VERSION "dbc-export 1 2026.26.6.5"

NS_ :

BS_:

BU_: BMS CP DAS DIF GTW HVP ICR PCS SCCM VCBATT VCFRONT VCFRONT1 VCLEFT VCRIGHT VCSEC

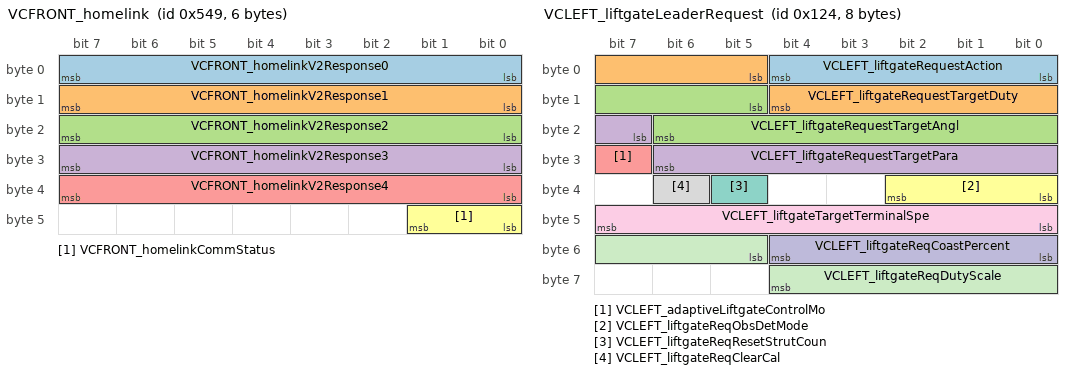
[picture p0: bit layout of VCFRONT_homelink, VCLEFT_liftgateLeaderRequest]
BO_ 1353 VCFRONT_homelink: 6 VCFRONT
 SG_ VCFRONT_homelinkV2Response0 : 0|8@1+ (1,0) [0|255] "" Vector__XXX
 SG_ VCFRONT_homelinkV2Response1 : 8|8@1+ (1,0) [0|255] "" Vector__XXX
 SG_ VCFRONT_homelinkV2Response2 : 16|8@1+ (1,0) [0|255] "" Vector__XXX
 SG_ VCFRONT_homelinkV2Response3 : 24|8@1+ (1,0) [0|255] "" Vector__XXX
 SG_ VCFRONT_homelinkV2Response4 : 32|8@1+ (1,0) [0|255] "" Vector__XXX
 SG_ VCFRONT_homelinkCommStatus : 40|2@1+ (1,0) [1|3] "" Vector__XXX

BO_ 1801 VCFRONT_logging0point1Hz: 8 VCFRONT
 SG_ VCFRONT_logging0point1HzIndex M : 0|6@1+ (1,0) [0|63] "" Vector__XXX
 SG_ VC_hcmlFactoryOfOrigin m26 : 6|2@1+ (1,0) [0|3] "" Vector__XXX
 SG_ VC_hcmlHellaPartNumberStatus m26 : 8|1@1+ (1,0) [0|1] "" Vector__XXX
 SG_ VC_hcmlHellaPartNumber m26 : 9|32@1+ (1,0) [0|4294967295] "-" Vector__XXX
 SG_ VC_hcmlCurrentBinMappingType m26 : 41|2@1+ (1,0) [0|3] "" Vector__XXX
 SG_ VC_hcmlCurrentBin0Value m26 : 43|3@1+ (1,0) [1|7] "" Vector__XXX
 SG_ VC_hcmlCurrentBin1Value m26 : 46|3@1+ (1,0) [1|7] "" Vector__XXX
 SG_ VC_hcmlCurrentBin2Value m26 : 49|3@1+ (1,0) [1|7] "" Vector__XXX
 SG_ VC_hcmlCurrentBin3Value m26 : 52|3@1+ (1,0) [1|7] "" Vector__XXX
 SG_ VC_hcmlCurrentBin4Value m26 : 55|3@1+ (1,0) [1|7] "" Vector__XXX
 SG_ VC_hcmlCurrentBin5Value m26 : 58|3@1+ (1,0) [1|7] "" Vector__XXX
 SG_ VC_hcmlRegionAndSide m26 : 61|3@1+ (1,0) [1|7] "" Vector__XXX
 SG_ VC_hcmrFactoryOfOrigin m27 : 6|2@1+ (1,0) [0|3] "" Vector__XXX
 SG_ VC_hcmrHellaPartNumberStatus m27 : 8|1@1+ (1,0) [0|1] "" Vector__XXX
 SG_ VC_hcmrHellaPartNumber m27 : 9|32@1+ (1,0) [0|4294967295] "-" Vector__XXX
 SG_ VC_hcmrCurrentBinMappingType m27 : 41|2@1+ (1,0) [0|3] "" Vector__XXX
 SG_ VC_hcmrCurrentBin0Value m27 : 43|3@1+ (1,0) [1|7] "" Vector__XXX
 SG_ VC_hcmrCurrentBin1Value m27 : 46|3@1+ (1,0) [1|7] "" Vector__XXX
 SG_ VC_hcmrCurrentBin2Value m27 : 49|3@1+ (1,0) [1|7] "" Vector__XXX
 SG_ VC_hcmrCurrentBin3Value m27 : 52|3@1+ (1,0) [1|7] "" Vector__XXX
 SG_ VC_hcmrCurrentBin4Value m27 : 55|3@1+ (1,0) [1|7] "" Vector__XXX
 SG_ VC_hcmrCurrentBin5Value m27 : 58|3@1+ (1,0) [1|7] "" Vector__XXX
 SG_ VC_hcmrRegionAndSide m27 : 61|3@1+ (1,0) [1|7] "" Vector__XXX

BO_ 957 VCFRONT_parkedEnergyLoss: 8 VCFRONT
 SG_ VCFRONT_energyLossIndex M : 0|3@1+ (1,0) [0|7] "" Vector__XXX
 SG_ VCFRONT_userEnergyLossSinceDrive m1 : 8|14@1+ (0.01,0) [0|163.83] "kWh" Vector__XXX
 SG_ VCFRONT_preconditioningEner_0001 m1 : 22|14@1+ (0.01,0) [0|163.83] "kWh" Vector__XXX
 SG_ VCFRONT_cabinOverheatEnergy_0001 m1 : 36|14@1+ (0.01,0) [0|163.83] "kWh" Vector__XXX
 SG_ VCFRONT_mobileAppEnergyLoss_0001 m1 : 50|14@1+ (0.01,0) [0|163.83] "kWh" Vector__XXX
 SG_ VCFRONT_summonStandbyEnergy_0001 m2 : 8|14@1+ (0.01,0) [0|163.83] "kWh" Vector__XXX
 SG_ VCFRONT_sentryModeEnergyLos_0001 m2 : 22|14@1+ (0.01,0) [0|163.83] "kWh" Vector__XXX
 SG_ VCFRONT_backgroundEnergyLos_0001 m2 : 36|14@1+ (0.01,0) [0|163.83] "kWh" Vector__XXX
 SG_ VCFRONT_evapDryingEnergyLos_0001 m2 : 50|14@1+ (0.01,0) [0|163.83] "kWh" Vector__XXX
 SG_ VCFRONT_userEnergyLossSinceCharg m3 : 8|14@1+ (0.01,0) [0|163.83] "kWh" Vector__XXX
 SG_ VCFRONT_preconditioningEnergyLos m3 : 22|14@1+ (0.01,0) [0|163.83] "kWh" Vector__XXX
 SG_ VCFRONT_cabinOverheatEnergyLossS m3 : 36|14@1+ (0.01,0) [0|163.83] "kWh" Vector__XXX
 SG_ VCFRONT_mobileAppEnergyLossSince m3 : 50|14@1+ (0.01,0) [0|163.83] "kWh" Vector__XXX
 SG_ VCFRONT_summonStandbyEnergyLossS m4 : 8|14@1+ (0.01,0) [0|163.83] "kWh" Vector__XXX
 SG_ VCFRONT_sentryModeEnergyLossSinc m4 : 22|14@1+ (0.01,0) [0|163.83] "kWh" Vector__XXX
 SG_ VCFRONT_backgroundEnergyLossSinc m4 : 36|14@1+ (0.01,0) [0|163.83] "kWh" Vector__XXX
 SG_ VCFRONT_evapDryingEnergyLossSinc m4 : 50|14@1+ (0.01,0) [0|163.83] "kWh" Vector__XXX

BO_ 737 VCFRONT_status: 8 VCFRONT
 SG_ VCFRONT_statusIndex M : 0|3@1+ (1,0) [0|7] "" Vector__XXX
 SG_ VCFRONT_frunkLatchStatus m0 : 3|4@1+ (1,0) [1|15] "" Vector__XXX
 SG_ VCFRONT_wiperSpeed m0 : 8|4@1+ (1,0) [1|15] "" Vector__XXX
 SG_ VCFRONT_wiperPosition m0 : 12|3@1+ (1,0) [1|7] "" Vector__XXX
 SG_ VCFRONT_wiperBlocked m0 : 15|1@1+ (1,0) [0|1] "" Vector__XXX
 SG_ VCFRONT_wiperState m0 : 16|4@1+ (1,0) [1|15] "" Vector__XXX
 SG_ VCFRONT_crashDetectedType m0 : 20|2@1+ (1,0) [0|3] "" Vector__XXX
 SG_ VCFRONT_crashState m0 : 22|2@1+ (1,0) [0|3] "" Vector__XXX
 SG_ VCFRONT_crashUnlockOverrideSet m0 : 24|1@1+ (1,0) [0|1] "" Vector__XXX
 SG_ VCFRONT_washPumpState m0 : 25|2@1+ (1,0) [0|3] "" Vector__XXX
 SG_ VCFRONT_turnIndicatorControlType m0 : 27|2@1+ (1,0) [0|3] "" Vector__XXX
 SG_ VCFRONT_wiperHealth m0 : 32|3@1+ (1,0) [0|7] "" Vector__XXX
 SG_ VCFRONT_wiperLINHealth m0 : 35|3@1+ (1,0) [0|7] "" Vector__XXX
 SG_ VCFRONT_frunkLatchCurrent m0 : 40|8@1- (0.157480314374,0) [-10|10] "A" Vector__XXX
 SG_ VCFRONT_frunkInteriorRelSwitch m0 : 48|1@1+ (1,0) [0|1] "" Vector__XXX
 SG_ VCFRONT_anyClosureOpen m0 : 49|1@1+ (1,0) [0|1] "" Vector__XXX
 SG_ VCFRONT_anyDoorOpen m0 : 50|1@1+ (1,0) [0|1] "" Vector__XXX
 SG_ VCFRONT_hornOn m0 : 51|1@1+ (1,0) [0|1] "" Vector__XXX
 SG_ VCFRONT_radarHeaterState m0 : 52|3@1+ (1,0) [1|7] "" Vector__XXX
 SG_ VCFRONT_trunkExteriorWakeSwitch m0 : 55|1@1+ (1,0) [0|1] "" Vector__XXX
 SG_ VCFRONT_passengerBuckleStatus m0 : 57|1@1+ (1,0) [0|1] "" Vector__XXX
 SG_ VCFRONT_frunkLatchType m0 : 58|2@1+ (1,0) [0|3] "" Vector__XXX
 SG_ VCFRONT_headlampLeftFanStatus m0 : 60|1@1+ (1,0) [0|1] "" Vector__XXX
 SG_ VCFRONT_headlampRightFanStatus m0 : 61|1@1+ (1,0) [0|1] "" Vector__XXX
 SG_ VCFRONT_frunkAccessPost m0 : 62|1@1+ (1,0) [0|1] "" Vector__XXX
 SG_ VCFRONT_isActiveHeatingBattery m0 : 63|1@1+ (1,0) [0|1] "" Vector__XXX
 SG_ VCFRONT_iBoosterWakeLine m1 : 3|1@1+ (1,0) [0|1] "" Vector__XXX
 SG_ VCFRONT_epasWakeLine m1 : 4|1@1+ (1,0) [0|1] "" Vector__XXX
 SG_ VCFRONT_iBoosterStateDBG m1 : 5|3@1+ (1,0) [0|7] "" Vector__XXX
 SG_ VCFRONT_vehicleStatusDBG m1 : 8|5@1+ (1,0) [0|31] "" Vector__XXX
 SG_ VCFRONT_timeSpentSleeping m1 : 13|10@1+ (1,0) [0|1023] "s" Vector__XXX
 SG_ VCFRONT_sleepCurrent m1 : 24|12@1+ (0.125,-511.875) [-511.875|-0.125] "mA" Vector__XXX
 SG_ VCFRONT_hibernationState m1 : 36|3@1+ (1,0) [0|7] "" Vector__XXX
 SG_ VCFRONT_wiperECUType m1 : 40|2@1+ (1,0) [0|3] "" Vector__XXX
 SG_ VCFRONT_wiperHeaterState m1 : 42|3@1+ (1,0) [1|7] "" Vector__XXX
 SG_ VCFRONT_occupantCount m1 : 45|3@1+ (1,0) [0|7] "" Vector__XXX
 SG_ VCFRONT_closureEasterEggState m1 : 48|3@1+ (1,0) [0|7] "" Vector__XXX
 SG_ VCFRONT_espWakeLine m1 : 51|1@1+ (1,0) [0|1] "" Vector__XXX
 SG_ VCFRONT_allowEvapInLowAmbient m1 : 52|1@1+ (1,0) [0|1] "" Vector__XXX
 SG_ VCFRONT_potentialRadiatorSteam m1 : 53|1@1+ (1,0) [0|1] "" Vector__XXX
 SG_ VCFRONT_potentialRadiatorSteamUI m1 : 54|1@1+ (1,0) [0|1] "" Vector__XXX
 SG_ VCFRONT_hvacReqOffForFasterCharg m1 : 55|1@1+ (1,0) [0|1] "" Vector__XXX
 SG_ VCFRONT_limitedSplitTempDeltaEnf m1 : 56|1@1+ (1,0) [0|1] "" Vector__XXX
 SG_ VCFRONT_batteryDischArbState m1 : 57|3@1+ (1,0) [0|7] "" Vector__XXX
 SG_ VCFRONT_maxEvapHeatRejection m2 : 8|8@1+ (65,0) [0|16575] "W" Vector__XXX
 SG_ VCFRONT_minEvapHeatRejection m2 : 16|8@1+ (15,0) [0|3800] "W" Vector__XXX
 SG_ VCFRONT_freezeEvapITerm m2 : 24|1@1+ (1,0) [0|1] "" Vector__XXX
 SG_ VCFRONT_isEvapOperationAllowed m2 : 25|1@1+ (1,0) [0|1] "" Vector__XXX
 SG_ VCFRONT_chillerDemandActive m2 : 26|1@1+ (1,0) [0|1] "" Vector__XXX
 SG_ VCFRONT_compPerfRecoveryLimited m2 : 27|1@1+ (1,0) [0|1] "" Vector__XXX
 SG_ VCFRONT_hvacModeNotAttainable m2 : 28|1@1+ (1,0) [0|1] "" Vector__XXX
 SG_ VCFRONT_hasLowRefrigerant m2 : 29|1@1+ (1,0) [0|1] "" Vector__XXX
 SG_ VCFRONT_isColdStartRunning m2 : 30|1@1+ (1,0) [0|1] "" Vector__XXX
 SG_ VCFRONT_isHeatPumpOilPurgeActive m2 : 31|1@1+ (1,0) [0|1] "" Vector__XXX
 SG_ VCFRONT_pressureRefrigSuction m2 : 32|7@1+ (0.125,0) [0|11.5] "bar" Vector__XXX
 SG_ VCFRONT_pressureRefrigDischarge m2 : 40|9@1+ (0.08,0) [0|37.25] "bar" Vector__XXX
 SG_ VCFRONT_hvacPerfTestCommand m2 : 49|3@1+ (1,0) [0|7] "" Vector__XXX
 SG_ VCFRONT_coolantFillRoutineStatus m2 : 52|2@1+ (1,0) [0|3] "" Vector__XXX
 SG_ VCFRONT_refrigFillRoutineStatus m2 : 54|2@1+ (1,0) [0|3] "" Vector__XXX
 SG_ VCFRONT_isCOP1Running m2 : 56|1@1+ (1,0) [0|1] "" Vector__XXX
 SG_ VCFRONT_closeValvesRoutineStatus m2 : 57|2@1+ (1,0) [0|3] "" Vector__XXX
 SG_ VCFRONT_thermalPerfTestRunning m2 : 59|1@1+ (1,0) [0|1] "" Vector__XXX
 SG_ VCFRONT_extendedHvacPerfTestComm m2 : 60|4@1+ (1,0) [0|15] "" Vector__XXX
 SG_ VCFRONT_5VARailStable m3 : 3|1@1+ (1,0) [0|1] "" Vector__XXX
 SG_ VCFRONT_5VBRailStable m3 : 4|1@1+ (1,0) [0|1] "" Vector__XXX
 SG_ VCFRONT_12VARailStable m3 : 5|1@1+ (1,0) [0|1] "" Vector__XXX
 SG_ VCFRONT_12VBRailStable m3 : 6|1@1+ (1,0) [0|1] "" Vector__XXX
 SG_ VCFRONT_railAState m3 : 7|1@1+ (1,0) [0|1] "" Vector__XXX
 SG_ VCFRONT_railBState m3 : 8|1@1+ (1,0) [0|1] "" Vector__XXX
 SG_ VCFRONT_ChargePumpVoltageStable m3 : 9|1@1+ (1,0) [0|1] "" Vector__XXX
 SG_ VCFRONT_PEResetLineState m3 : 10|1@1+ (1,0) [0|1] "" Vector__XXX
 SG_ VCFRONT_HSDInitCompleteU13 m3 : 11|1@1+ (1,0) [0|1] "" Vector__XXX
 SG_ VCFRONT_HSDInitCompleteU16 m3 : 12|1@1+ (1,0) [0|1] "" Vector__XXX
 SG_ VCFRONT_vbatMonitorVoltage m3 : 16|12@1+ (0.005443676,0) [0|22.286409544] "V" Vector__XXX
 SG_ VCFRONT_AS8510Voltage m3 : 28|12@1+ (0.005443676,0) [0|22.286409544] "V" Vector__XXX
 SG_ VCFRONT_vbatProt m3 : 40|12@1+ (0.005443676,0) [0|22.29185322] "V" Vector__XXX
 SG_ VCFRONT_logVerbosity m3 : 52|3@1+ (1,0) [0|7] "" Vector__XXX
 SG_ VCFRONT_cabinCoolingCapacityLimi m4 : 6|1@1+ (1,0) [0|1] "" Vector__XXX
 SG_ VCFRONT_cabinHeatingCapacityLimi m4 : 7|1@1+ (1,0) [0|1] "" Vector__XXX
 SG_ VCFRONT_compPowerSupportingHvac m4 : 8|11@1+ (10,0) [0|20470] "W" Vector__XXX
 SG_ VCFRONT_compPowerSupportingPT m4 : 19|11@1+ (10,0) [0|20470] "W" Vector__XXX
 SG_ VCFRONT_maxHeatingPowerLeftCC m4 : 30|7@1+ (100,0) [0|12000] "W" Vector__XXX
 SG_ VCFRONT_maxHeatingPowerRightCC m4 : 37|7@1+ (100,0) [0|12000] "W" Vector__XXX
 SG_ VCFRONT_activeLouverOpenPos m4 : 44|7@1+ (1,0) [0|100] "%" Vector__XXX
 SG_ VCFRONT_activeLouverState m4 : 51|5@1+ (1,0) [0|31] "" Vector__XXX
 SG_ VCFRONT_windshieldCameraHeaterPo m4 : 56|6@1+ (2.5,0) [0|155] "W" Vector__XXX

BO_ 507 VCLEFT_TLCStatus: 8 VCLEFT
 SG_ VCLEFT_TLCStatusIndex M : 0|2@1+ (1,0) [0|3] "" Vector__XXX
 SG_ VCLEFT_TLCTemperature m1 : 2|8@1- (1,68) [-59|195] "degC" Vector__XXX
 SG_ VCLEFT_TLCLeftTurnVoltage m1 : 10|8@1+ (0.1,0) [0|25.4] "V" Vector__XXX
 SG_ VCLEFT_TLCRightTurnVoltage m1 : 18|8@1+ (0.1,0) [0|25.4] "V" Vector__XXX
 SG_ VCLEFT_TLCState_LeftTurn m1 : 26|3@1+ (1,0) [0|7] "" Vector__XXX
 SG_ VCLEFT_TLCState_RightTurn m1 : 29|3@1+ (1,0) [0|7] "" Vector__XXX
 SG_ VCLEFT_TLCState_Tail m1 : 32|3@1+ (1,0) [0|7] "" Vector__XXX
 SG_ VCLEFT_TLCState_Stop m1 : 35|3@1+ (1,0) [0|7] "" Vector__XXX
 SG_ VCLEFT_TLCState_Fog m1 : 38|3@1+ (1,0) [0|7] "" Vector__XXX
 SG_ VCLEFT_TLCState_Reverse m1 : 41|3@1+ (1,0) [0|7] "" Vector__XXX

BO_ 292 VCLEFT_liftgateLeaderRequest: 8 VCLEFT
 SG_ VCLEFT_liftgateRequestAction : 0|5@1+ (1,0) [0|31] "" Vector__XXX
 SG_ VCLEFT_liftgateRequestTargetDuty : 5|8@1- (1,0) [-100|100] "%" Vector__XXX
 SG_ VCLEFT_liftgateRequestTargetAngl : 13|10@1- (0.2,0) [-100|100] "deg" Vector__XXX
 SG_ VCLEFT_liftgateRequestTargetPara : 23|8@1- (1,0) [-100|100] "" Vector__XXX
 SG_ VCLEFT_adaptiveLiftgateControlMo : 31|1@1+ (1,0) [0|1] "" Vector__XXX
 SG_ VCLEFT_liftgateReqObsDetMode : 32|3@1+ (1,0) [0|7] "" Vector__XXX
 SG_ VCLEFT_liftgateReqResetStrutCoun : 37|1@1+ (1,0) [0|1] "" Vector__XXX
 SG_ VCLEFT_liftgateReqClearCal : 38|1@1+ (1,0) [0|1] "" Vector__XXX
 SG_ VCLEFT_liftgateTargetTerminalSpe : 40|8@1- (0.08,10) [0|20] "deg/s" Vector__XXX
 SG_ VCLEFT_liftgateReqCoastPercent : 48|5@1+ (4,0) [0|100] "%" Vector__XXX
 SG_ VCLEFT_liftgateReqDutyScale : 53|8@1+ (0.0125,0) [0|3.15] "-" Vector__XXX

BO_ 1802 VCLEFT_logging0point1Hz: 8 VCLEFT
 SG_ VCLEFT_logging0point1HzIndex M : 0|1@1+ (1,0) [0|1] "" Vector__XXX
 SG_ VCLEFT_leftBrakeTailLightCurrent m0 : 2|9@1+ (0.005,0) [0|2.55] "A" Vector__XXX
 SG_ VCLEFT_leftBrakeTailLightCu_0001 m0 : 11|3@1+ (1,0) [1|7] "" Vector__XXX
 SG_ VCLEFT_leftRearTurnLightCurrent m0 : 14|9@1+ (0.002,0) [0|1.02] "A" Vector__XXX
 SG_ VCLEFT_leftRearTurnLightCurrentS m0 : 24|3@1+ (1,0) [1|7] "" Vector__XXX
 SG_ VCLEFT_phoneTemperatureFL m0 : 32|8@1- (1,-50) [-177|77] "degC" Vector__XXX
 SG_ VCLEFT_phoneTemperatureFR m0 : 40|8@1- (1,-50) [-177|77] "degC" Vector__XXX
 SG_ VCLEFT_canAuthResyncDurationMs m0 : 48|16@1+ (1,0) [0|65535] "" Vector__XXX

BO_ 930 VCLEFT_status: 8 VCLEFT
 SG_ VCLEFT_statusIndex M : 0|2@1+ (1,0) [0|3] "" Vector__XXX
 SG_ VCLEFT_securityControllerEnable m0 : 5|1@1+ (1,0) [0|1] "" Vector__XXX
 SG_ VCLEFT_securityControllerVoltage m0 : 6|5@1+ (0.625,0) [0|19.375] "V" Vector__XXX
 SG_ VCLEFT_consoleDoorAssist m0 : 11|1@1+ (1,0) [0|1] "" Vector__XXX
 SG_ VCLEFT_OTAState m0 : 12|1@1+ (1,0) [0|1] "" Vector__XXX
 SG_ VCLEFT_5AVoltage m0 : 13|10@1+ (0.005443676,0) [0|5.568880548] "V" Vector__XXX
 SG_ VCLEFT_vbatProt m0 : 23|12@1+ (0.005443676,0) [0|22.29185322] "V" Vector__XXX
 SG_ VCLEFT_footwellLightCurrent m0 : 35|12@1- (0.1,0) [-204.8|204.7] "mA" Vector__XXX
 SG_ VCLEFT_swcInputVoltage m0 : 47|8@1+ (0.1,0) [0|25.4] "V" Vector__XXX
 SG_ VCLEFT_swcPCBATemperature m0 : 55|8@1- (1,68) [-59|195] "degC" Vector__XXX
 SG_ VCLEFT_obdEthernetActive m0 : 63|1@1+ (1,0) [0|1] "" Vector__XXX
 SG_ VCLEFT_rationalityAggregateCurre m1 : 12|8@1+ (0.5,0) [0|127.5] "A" Vector__XXX
 SG_ VCLEFT_LVBatteryTypeDBG m1 : 20|3@1+ (1,0) [0|7] "" Vector__XXX
 SG_ VCLEFT_DIeFuseFault m1 : 24|1@1+ (1,0) [0|1] "" Vector__XXX
 SG_ VCLEFT_eFuseMgmtVoltageMonitor m1 : 25|7@1+ (0.125,0) [0|15.875] "V" Vector__XXX
 SG_ VCLEFT_trailerAuxCurrent m1 : 32|12@1+ (0.025,0) [0|102.35] "A" Vector__XXX
 SG_ VCLEFT_swcHeatTmp m1 : 44|10@1+ (0.1,-35) [-35|65] "degC" Vector__XXX
 SG_ VCLEFT_swcHeatStatus m1 : 54|3@1+ (1,0) [1|7] "" Vector__XXX
 SG_ VCLEFT_swcHeatInhibited m1 : 57|1@1+ (1,0) [0|1] "" Vector__XXX
 SG_ VCLEFT_obdDeviceDetected m1 : 58|1@1+ (1,0) [0|1] "" Vector__XXX
 SG_ VCLEFT_pcbaTemperature m2 : 4|11@1+ (0.125,-40) [-40|150] "degC" Vector__XXX
 SG_ VCLEFT_swcHeatPwr m2 : 15|9@1+ (0.5,0) [0|254] "W" Vector__XXX
 SG_ VCLEFT_swcHeatDutyCycle m2 : 24|7@1+ (1,0) [0|100] "%" Vector__XXX
 SG_ VCLEFT_DIeFuseCurrent m2 : 31|6@1+ (0.1,0) [0|6.3] "A" Vector__XXX
 SG_ VCLEFT_SWCpresent m2 : 37|1@1+ (1,0) [0|1] "" Vector__XXX
 SG_ VCLEFT_trailerBrakeControllerCur m2 : 38|8@1+ (0.1,0) [0|25.5] "A" Vector__XXX
 SG_ VCLEFT_autonomyBehaviorStatus m2 : 46|2@1+ (1,0) [0|3] "" Vector__XXX
 SG_ VCLEFT_thirdRowLeftMapLightStatu m2 : 48|2@1+ (1,0) [0|2] "" Vector__XXX
 SG_ VCLEFT_thirdRowRightMapLightStat m2 : 50|2@1+ (1,0) [0|2] "" Vector__XXX

BO_ 962 VCLEFT_switchStatus: 8 VCLEFT
 SG_ VCLEFT_switchStatusIndex M : 0|1@1+ (1,0) [0|1] "" Vector__XXX
 SG_ VCLEFT_hornSwitchPressed m0 : 2|1@1+ (1,0) [0|1] "" Vector__XXX
 SG_ VCLEFT_hazardButtonPressed m0 : 3|1@1+ (1,0) [0|1] "" Vector__XXX
 SG_ VCLEFT_brakeSwitchPressed m0 : 4|1@1+ (1,0) [0|1] "" Vector__XXX
 SG_ VCLEFT_rightMirrorTilt m0 : 5|3@1+ (1,0) [0|7] "" Vector__XXX
 SG_ VCLEFT_frontSeatTrackBack m0 : 8|2@1+ (1,0) [1|3] "" Vector__XXX
 SG_ VCLEFT_frontSeatTrackForward m0 : 10|2@1+ (1,0) [1|3] "" Vector__XXX
 SG_ VCLEFT_frontSeatTiltDown m0 : 12|2@1+ (1,0) [1|3] "" Vector__XXX
 SG_ VCLEFT_frontSeatTiltUp m0 : 14|2@1+ (1,0) [1|3] "" Vector__XXX
 SG_ VCLEFT_frontSeatLiftDown m0 : 16|2@1+ (1,0) [1|3] "" Vector__XXX
 SG_ VCLEFT_frontSeatLiftUp m0 : 18|2@1+ (1,0) [1|3] "" Vector__XXX
 SG_ VCLEFT_frontSeatBackrestBack m0 : 20|2@1+ (1,0) [1|3] "" Vector__XXX
 SG_ VCLEFT_frontSeatBackrestForward m0 : 22|2@1+ (1,0) [1|3] "" Vector__XXX
 SG_ VCLEFT_frontSeatLumbarDown m0 : 24|2@1+ (1,0) [1|3] "" Vector__XXX
 SG_ VCLEFT_frontSeatLumbarUp m0 : 26|2@1+ (1,0) [1|3] "" Vector__XXX
 SG_ VCLEFT_frontSeatLumbarIn m0 : 28|2@1+ (1,0) [1|3] "" Vector__XXX
 SG_ VCLEFT_frontSeatLumbarOut m0 : 30|2@1+ (1,0) [1|3] "" Vector__XXX
 SG_ VCLEFT_btnWindowSwPackUpLF m0 : 32|1@1+ (1,0) [0|1] "" Vector__XXX
 SG_ VCLEFT_btnWindowSwPackAutoUpLF m0 : 33|1@1+ (1,0) [0|1] "" Vector__XXX
 SG_ VCLEFT_btnWindowSwPackDownLF m0 : 34|1@1+ (1,0) [0|1] "" Vector__XXX
 SG_ VCLEFT_btnWindowSwPackAutoDownLF m0 : 35|1@1+ (1,0) [0|1] "" Vector__XXX
 SG_ VCLEFT_btnWindowSwPackUpLR m0 : 36|1@1+ (1,0) [0|1] "" Vector__XXX
 SG_ VCLEFT_btnWindowSwPackAutoUpLR m0 : 37|1@1+ (1,0) [0|1] "" Vector__XXX
 SG_ VCLEFT_btnWindowSwPackDownLR m0 : 38|1@1+ (1,0) [0|1] "" Vector__XXX
 SG_ VCLEFT_btnWindowSwPackAutoDownLR m0 : 39|1@1+ (1,0) [0|1] "" Vector__XXX
 SG_ VCLEFT_btnWindowSwPackUpRF m0 : 40|1@1+ (1,0) [0|1] "" Vector__XXX
 SG_ VCLEFT_btnWindowSwPackAutoUpRF m0 : 41|1@1+ (1,0) [0|1] "" Vector__XXX
 SG_ VCLEFT_btnWindowSwPackDownRF m0 : 42|1@1+ (1,0) [0|1] "" Vector__XXX
 SG_ VCLEFT_btnWindowSwPackAutoDownRF m0 : 43|1@1+ (1,0) [0|1] "" Vector__XXX
 SG_ VCLEFT_btnWindowSwPackUpRR m0 : 44|1@1+ (1,0) [0|1] "" Vector__XXX
 SG_ VCLEFT_btnWindowSwPackAutoUpRR m0 : 45|1@1+ (1,0) [0|1] "" Vector__XXX
 SG_ VCLEFT_btnWindowSwPackDownRR m0 : 46|1@1+ (1,0) [0|1] "" Vector__XXX
 SG_ VCLEFT_btnWindowSwPackAutoDownRR m0 : 47|1@1+ (1,0) [0|1] "" Vector__XXX
 SG_ VCLEFT_frontBuckleSwitch m0 : 48|2@1+ (1,0) [1|3] "" Vector__XXX
 SG_ VCLEFT_frontOccupancySwitch m0 : 50|2@1+ (1,0) [1|3] "" Vector__XXX
 SG_ VCLEFT_rearLeftBuckleSwitch m0 : 52|2@1+ (1,0) [1|3] "" Vector__XXX
 SG_ VCLEFT_rearCenterOccupancySwitch m0 : 54|2@1+ (1,0) [1|3] "" Vector__XXX
 SG_ VCLEFT_rearLeftOccupancySwitch m0 : 56|2@1+ (1,0) [1|3] "" Vector__XXX
 SG_ VCLEFT_rearRightOccupancySwitch m0 : 58|2@1+ (1,0) [1|3] "" Vector__XXX
 SG_ VCLEFT_brakePressed m0 : 60|1@1+ (1,0) [0|1] "" Vector__XXX
 SG_ VCLEFT_rearHVACButtonPressed m0 : 61|1@1+ (1,0) [0|1] "" Vector__XXX
 SG_ VCLEFT_rearCenterBuckleSwitch m0 : 62|2@1+ (1,0) [1|3] "" Vector__XXX
 SG_ VCLEFT_isAlcoholInterlockSet m1 : 2|1@1+ (1,0) [0|1] "" Vector__XXX
 SG_ VCLEFT_swcLeftTiltRight m1 : 3|2@1+ (1,0) [1|3] "" Vector__XXX
 SG_ VCLEFT_swcLeftPressed m1 : 5|2@1+ (1,0) [1|3] "" Vector__XXX
 SG_ VCLEFT_swcRightTiltLeft m1 : 8|2@1+ (1,0) [1|3] "" Vector__XXX
 SG_ VCLEFT_swcRightTiltRight m1 : 10|2@1+ (1,0) [1|3] "" Vector__XXX
 SG_ VCLEFT_swcRightPressed m1 : 12|2@1+ (1,0) [1|3] "" Vector__XXX
 SG_ VCLEFT_swcLeftTiltLeft m1 : 14|2@1+ (1,0) [1|3] "" Vector__XXX
 SG_ VCLEFT_swcLeftScrollTicks m1 : 16|6@1- (1,0) [-32|31] "" Vector__XXX
 SG_ VCLEFT_swcWiperButtonState m1 : 22|2@1+ (1,0) [0|3] "" Vector__XXX
 SG_ VCLEFT_swcRightScrollTicks m1 : 24|6@1- (1,0) [-32|31] "" Vector__XXX
 SG_ VCLEFT_swcTurnSignalLeftButtonSt m1 : 30|2@1+ (1,0) [0|3] "" Vector__XXX
 SG_ VCLEFT_btnWindowUpLR m1 : 32|1@1+ (1,0) [0|1] "" Vector__XXX
 SG_ VCLEFT_btnWindowAutoUpLR m1 : 33|1@1+ (1,0) [0|1] "" Vector__XXX
 SG_ VCLEFT_btnWindowDownLR m1 : 34|1@1+ (1,0) [0|1] "" Vector__XXX
 SG_ VCLEFT_btnWindowAutoDownLR m1 : 35|1@1+ (1,0) [0|1] "" Vector__XXX
 SG_ VCLEFT_2RowSeatLeftFoldFlatSwitc m1 : 38|1@1+ (1,0) [0|1] "" Vector__XXX
 SG_ VCLEFT_2RowSeatRightFoldFlatSwit m1 : 39|1@1+ (1,0) [0|1] "" Vector__XXX
 SG_ VCLEFT_2RowSeatBothFoldFlatSwitc m1 : 40|1@1+ (1,0) [0|1] "" Vector__XXX
 SG_ VCLEFT_swcLeftDoublePress m1 : 41|1@1+ (1,0) [0|1] "" Vector__XXX
 SG_ VCLEFT_swcRightDoublePress m1 : 42|1@1+ (1,0) [0|1] "" Vector__XXX
 SG_ VCLEFT_swcTurnSignalRightButtonS m1 : 44|2@1+ (1,0) [0|3] "" Vector__XXX
 SG_ VCLEFT_swcHighBeamButtonState m1 : 46|2@1+ (1,0) [0|3] "" Vector__XXX
 SG_ VCLEFT_swcVoiceControlPress m1 : 48|2@1+ (1,0) [1|3] "" Vector__XXX
 SG_ VCLEFT_swcCameraButtonState m1 : 50|2@1+ (1,0) [0|3] "" Vector__XXX
 SG_ VCLEFT_swcRightPressedQF m1 : 52|1@1+ (1,0) [0|1] "" Vector__XXX
 SG_ VCLEFT_2RowSeatReclineSwitchpack m1 : 53|3@1+ (1,0) [0|7] "" Vector__XXX
 SG_ VCLEFT_3RowLeftBuckleSwitch m1 : 56|2@1+ (1,0) [1|3] "" Vector__XXX
 SG_ VCLEFT_frontSeatThighSupportExte m1 : 58|2@1+ (1,0) [1|3] "" Vector__XXX
 SG_ VCLEFT_frontSeatThighSupportRetr m1 : 60|2@1+ (1,0) [1|3] "" Vector__XXX
 SG_ VCLEFT_frontSeatResistiveOccupan m1 : 62|2@1+ (1,0) [1|3] "" Vector__XXX

BO_ 1114 VCRIGHT_AP_hvacState10Hz: 8 VCRIGHT
 SG_ VCRIGHT_AP_hvacState10HzIndex M : 0|2@1+ (1,0) [0|3] "" Vector__XXX
 SG_ VCRIGHT_AP_autoDefogAvailable m0 : 2|1@1+ (1,0) [0|1] "" Vector__XXX
 SG_ VCRIGHT_AP_hvacFlashFoggingDetec m0 : 3|1@1+ (1,0) [0|1] "" Vector__XXX
 SG_ VCRIGHT_AP_hvacModelInitStatus m0 : 4|3@1+ (1,0) [0|7] "" Vector__XXX
 SG_ VCRIGHT_AP_cabinTempWindshield m0 : 7|8@1+ (0.5,-40) [-40|80] "degC" Vector__XXX
 SG_ VCRIGHT_AP_cabinTempSideGlassRig m0 : 15|8@1+ (0.5,-40) [-40|80] "degC" Vector__XXX
 SG_ VCRIGHT_AP_cabinTempSideGlassLef m0 : 23|8@1+ (0.5,-40) [-40|80] "degC" Vector__XXX
 SG_ VCRIGHT_AP_hvacRecircDoorPercent m0 : 31|6@1+ (1.6,0) [0|100] "%" Vector__XXX
 SG_ VCRIGHT_AP_hvacAirDistributionMo m0 : 37|3@1+ (1,0) [0|7] "" Vector__XXX
 SG_ VCRIGHT_AP_hvacEstimateWindshiel m0 : 40|8@1+ (1,0) [0|150] "%" Vector__XXX
 SG_ VCRIGHT_AP_hvacMassflowTarget m0 : 48|8@1+ (1,0) [0|200] "g/s" Vector__XXX
 SG_ VCRIGHT_AP_tempDuctDefrost m0 : 56|8@1+ (0.5,-22) [-22|105] "degC" Vector__XXX
 SG_ VCRIGHT_AP_cameraTurnOnTime m1 : 2|9@1+ (5,0) [0|2540] "min" Vector__XXX
 SG_ VCRIGHT_AP_cameraDefogType m1 : 11|3@1+ (1,0) [0|7] "" Vector__XXX
 SG_ VCRIGHT_ah_hvacFaultSurvivabilit m1 : 14|5@1+ (10,0) [0|300] "sec" Vector__XXX
 SG_ VCRIGHT_ah_defoggingTimeNeeded m1 : 19|5@1+ (1,0) [0|30] "min" Vector__XXX
 SG_ VCRIGHT_AP_cameraFanDutyRequest m1 : 24|7@1+ (1,0) [0|100] "%" Vector__XXX
 SG_ VCRIGHT_ah_defogSystemState m1 : 31|3@1+ (1,0) [0|6] "" Vector__XXX
 SG_ VCRIGHT_AP_turnForwardCameraHeat m1 : 34|4@1+ (1,0) [0|15] "" Vector__XXX
 SG_ VCRIGHT_AP_turnCameraFanOffReaso m1 : 38|3@1+ (1,0) [0|7] "" Vector__XXX
 SG_ VCRIGHT_AP_forwardCameraIntegrat m1 : 41|1@1+ (1,0) [0|1] "" Vector__XXX
 SG_ VCRIGHT_AP_solarFluxOnRightWindo m1 : 48|8@1+ (5,0) [0|1150] "W/m2" Vector__XXX
 SG_ VCRIGHT_AP_solarFluxOnLeftWindow m1 : 56|8@1+ (5,0) [0|1150] "W/m2" Vector__XXX

BO_ 1795 VCRIGHT_debugThermal10Hz: 8 VCRIGHT
 SG_ VCRIGHT_debugThermal10HzIndex M : 0|4@1+ (1,0) [0|15] "" Vector__XXX
 SG_ VCRIGHT_hvacPanelFloorSplitRow1 m2 : 8|8@1+ (0.4,0) [0|100] "%" Vector__XXX
 SG_ VCRIGHT_hvacDefrostPercent m2 : 16|8@1+ (0.4,0) [0|100] "%" Vector__XXX
 SG_ VCRIGHT_hvacRow2Percent m2 : 24|8@1+ (0.4,0) [0|100] "%" Vector__XXX
 SG_ VCRIGHT_hvacPanelFloorSplitRow2 m2 : 32|8@1+ (0.4,0) [0|100] "%" Vector__XXX
 SG_ VCRIGHT_hvacFreshMassCounter m2 : 40|12@1+ (10,0) [0|40000] "kg" Vector__XXX
 SG_ VCRIGHT_hvacRecircMassCounter m2 : 52|12@1+ (10,0) [0|40000] "kg" Vector__XXX
 SG_ VCRIGHT_setTempAdjustmentLeft m3 : 8|7@1+ (0.1,0) [0|12] "degC" Vector__XXX
 SG_ VCRIGHT_setTempAdjustmentRight m3 : 16|7@1+ (0.1,0) [0|12] "degC" Vector__XXX
 SG_ VCRIGHT_hvacLHVaneVelocity m3 : 24|8@1- (0.8,0) [-100|100] "deg/s" Vector__XXX
 SG_ VCRIGHT_hvacRHVaneVelocity m3 : 32|8@1- (0.8,0) [-100|100] "deg/s" Vector__XXX
 SG_ VCRIGHT_hvacVehicleSpeed m3 : 40|5@1+ (5,0) [0|150] "kph" Vector__XXX
 SG_ VCRIGHT_hvacMassflowCompensated m3 : 47|8@1+ (1.5,0) [0|250] "g/s" Vector__XXX
 SG_ VCRIGHT_PTCcenterPowerLeft m5 : 8|6@1+ (30,0) [0|1800] "W" Vector__XXX
 SG_ VCRIGHT_PTCouterPowerLeft m5 : 16|6@1+ (30,0) [0|1800] "W" Vector__XXX
 SG_ VCRIGHT_PTCinnerPowerLeft m5 : 24|6@1+ (30,0) [0|1800] "W" Vector__XXX
 SG_ VCRIGHT_PTCcenterPowerRight m5 : 32|6@1+ (30,0) [0|1800] "W" Vector__XXX
 SG_ VCRIGHT_PTCouterPowerRight m5 : 40|6@1+ (30,0) [0|1800] "W" Vector__XXX
 SG_ VCRIGHT_PTCinnerPowerRight m5 : 48|6@1+ (30,0) [0|1800] "W" Vector__XXX
 SG_ VCRIGHT_PTCcenterStoneTempLeft m6 : 8|8@1+ (2,-70) [-70|438] "degC" Vector__XXX
 SG_ VCRIGHT_PTCcenterStoneTempRight m6 : 16|8@1+ (2,-70) [-70|438] "degC" Vector__XXX
 SG_ VCRIGHT_PTCinnerStoneTempLeft m6 : 24|8@1+ (2,-70) [-70|438] "degC" Vector__XXX
 SG_ VCRIGHT_PTCinnerStoneTempRight m6 : 32|8@1+ (2,-70) [-70|438] "degC" Vector__XXX
 SG_ VCRIGHT_PTCouterStoneTempLeft m7 : 8|8@1+ (2,-70) [-70|438] "degC" Vector__XXX
 SG_ VCRIGHT_PTCouterRodTempLeft m7 : 16|8@1+ (2,-70) [-70|438] "degC" Vector__XXX
 SG_ VCRIGHT_PTCouterAirTempLeft m7 : 24|8@1+ (2,-70) [-70|438] "degC" Vector__XXX
 SG_ VCRIGHT_PTCcenterRodTempLeft m7 : 32|8@1+ (2,-70) [-70|438] "degC" Vector__XXX
 SG_ VCRIGHT_PTCinnerRodTempLeft m7 : 40|8@1+ (2,-70) [-70|438] "degC" Vector__XXX
 SG_ VCRIGHT_PTCcenterAirTempLeft m7 : 48|8@1+ (2,-70) [-70|438] "degC" Vector__XXX
 SG_ VCRIGHT_PTCinnerAirTempLeft m7 : 56|8@1+ (2,-70) [-70|438] "degC" Vector__XXX
 SG_ VCRIGHT_PTCouterStoneTempRight m8 : 8|8@1+ (2,-70) [-70|438] "degC" Vector__XXX
 SG_ VCRIGHT_PTCouterRodTempRight m8 : 16|8@1+ (2,-70) [-70|438] "degC" Vector__XXX
 SG_ VCRIGHT_PTCouterAirTempRight m8 : 24|8@1+ (2,-70) [-70|438] "degC" Vector__XXX
 SG_ VCRIGHT_PTCcenterRodTempRight m8 : 32|8@1+ (2,-70) [-70|438] "degC" Vector__XXX
 SG_ VCRIGHT_PTCinnerRodTempRight m8 : 40|8@1+ (2,-70) [-70|438] "degC" Vector__XXX
 SG_ VCRIGHT_PTCcenterAirTempRight m8 : 48|8@1+ (2,-70) [-70|438] "degC" Vector__XXX
 SG_ VCRIGHT_PTCinnerAirTempRight m8 : 56|8@1+ (2,-70) [-70|438] "degC" Vector__XXX

BO_ 291 VCRIGHT_doorStatus2: 8 VCRIGHT
 SG_ VCRIGHT_doorStatus2Index M : 0|1@1+ (1,0) [0|1] "" Vector__XXX
 SG_ VCRIGHT_frontLatchRelDuty m1 : 8|8@1+ (1,0) [0|255] "%" Vector__XXX
 SG_ VCRIGHT_BPillarCameraHeaterState m1 : 16|3@1+ (1,0) [1|7] "" Vector__XXX
 SG_ VCRIGHT_doorLatchAjarSwitchVolta m1 : 24|8@1+ (0.02,0) [0|5] "V" Vector__XXX
 SG_ VCRIGHT_doorLatchAjarSwitch_0001 m1 : 32|8@1+ (0.02,0) [0|5] "V" Vector__XXX
 SG_ VCRIGHT_BPillarCameraHeaterCurre m1 : 40|6@1+ (0.02,0) [0|1.24] "A" Vector__XXX
 SG_ VCRIGHT_mirrorTiltXOffset m1 : 48|8@1- (0.02,0) [-2.5|2.5] "V" Vector__XXX
 SG_ VCRIGHT_mirrorTiltYOffset m1 : 56|8@1- (0.02,0) [-2.5|2.5] "V" Vector__XXX

BO_ 739 VCRIGHT_seatStatus2: 7 VCRIGHT
 SG_ VCRIGHT_seatStatus2Index M : 0|4@1+ (1,0) [0|15] "" Vector__XXX
 SG_ VCRIGHT_frontSeatHeatCurrent m0 : 4|12@1+ (0.01,0) [0|40.95] "A" Vector__XXX
 SG_ VCRIGHT_frontSeatHeatDuty m0 : 16|8@1+ (1,0) [0|255] "%" Vector__XXX
 SG_ VCRIGHT_frontSeatHeatTmp m0 : 24|12@1- (0.05,0) [-40|80] "degC" Vector__XXX
 SG_ VCRIGHT_frontSeatHeatTmpTarget m0 : 36|8@1- (0.5,0) [0|60] "degC" Vector__XXX
 SG_ VCRIGHT_frontSeatHeatInhibited m0 : 44|1@1+ (1,0) [0|1] "" Vector__XXX
 SG_ VCRIGHT_frontSeatHeatPowered m0 : 45|1@1+ (1,0) [0|1] "" Vector__XXX
 SG_ VC_AH_1RowRightSeatHeatVentHealt m0 : 54|2@1+ (1,0) [0|3] "" Vector__XXX
 SG_ VCRIGHT_rearLSeatHeatCurrent m1 : 4|12@1+ (0.01,0) [0|40.95] "A" Vector__XXX
 SG_ VCRIGHT_rearLSeatHeatDuty m1 : 16|8@1+ (1,0) [0|255] "%" Vector__XXX
 SG_ VCRIGHT_rearLSeatHeatTmp m1 : 24|12@1- (0.05,0) [-40|80] "degC" Vector__XXX
 SG_ VCRIGHT_rearLSeatHeatTmpTarget m1 : 36|8@1- (0.5,0) [0|60] "degC" Vector__XXX
 SG_ VCRIGHT_rearLSeatHeatInhibited m1 : 44|1@1+ (1,0) [0|1] "" Vector__XXX
 SG_ VCRIGHT_rearLSeatHeatPowered m1 : 45|1@1+ (1,0) [0|1] "" Vector__XXX
 SG_ VCRIGHT_rearCSeatHeatCurrent m2 : 4|12@1+ (0.01,0) [0|40.95] "A" Vector__XXX
 SG_ VCRIGHT_rearCSeatHeatDuty m2 : 16|8@1+ (1,0) [0|255] "%" Vector__XXX
 SG_ VCRIGHT_rearCSeatHeatTmp m2 : 24|12@1- (0.05,0) [-40|80] "degC" Vector__XXX
 SG_ VCRIGHT_rearCSeatHeatTmpTarget m2 : 36|8@1- (0.5,0) [0|60] "degC" Vector__XXX
 SG_ VCRIGHT_rearCSeatHeatInhibited m2 : 44|1@1+ (1,0) [0|1] "" Vector__XXX
 SG_ VCRIGHT_rearCSeatHeatPowered m2 : 45|1@1+ (1,0) [0|1] "" Vector__XXX
 SG_ VCRIGHT_rearRSeatHeatCurrent m3 : 4|12@1+ (0.01,0) [0|40.95] "A" Vector__XXX
 SG_ VCRIGHT_rearRSeatHeatDuty m3 : 16|8@1+ (1,0) [0|255] "%" Vector__XXX
 SG_ VCRIGHT_rearRSeatHeatTmp m3 : 24|12@1- (0.05,0) [-40|80] "degC" Vector__XXX
 SG_ VCRIGHT_rearRSeatHeatTmpTarget m3 : 36|8@1- (0.5,0) [0|60] "degC" Vector__XXX
 SG_ VCRIGHT_rearRSeatHeatInhibited m3 : 44|1@1+ (1,0) [0|1] "" Vector__XXX
 SG_ VCRIGHT_rearRSeatHeatPowered m3 : 45|1@1+ (1,0) [0|1] "" Vector__XXX
 SG_ VCRIGHT_2RowSeatReclineState m11 : 4|4@1+ (1,0) [0|14] "" Vector__XXX
 SG_ VCRIGHT_2RowSeatReclineDuty m11 : 8|8@1- (1,0) [-100|100] "%" Vector__XXX
 SG_ VCRIGHT_2RowSeatReclineCurrent m11 : 16|12@1- (0.05,0) [-100|100] "A" Vector__XXX
 SG_ VCRIGHT_2RowSeatReclineCalibrate m11 : 28|1@1+ (1,0) [0|1] "" Vector__XXX
 SG_ VCRIGHT_2RowSeatReclinePositionR m11 : 29|12@1- (1,0) [-2048|2047] "" Vector__XXX
 SG_ VCRIGHT_2RowSeatReclineAngle m11 : 41|12@1- (0.1,0) [-204.8|204.7] "deg" Vector__XXX
 SG_ VCRIGHT_2RowSeatReclineAbsPosSwi m11 : 53|2@1+ (1,0) [1|3] "" Vector__XXX
 SG_ VCRIGHT_2RowSeatReclinePositionS m12 : 4|3@1+ (1,0) [0|7] "" Vector__XXX
 SG_ VCRIGHT_2RowSeatReclineAdjustmen m12 : 7|1@1+ (1,0) [0|1] "" Vector__XXX
 SG_ VCRIGHT_2RowSeatReclineFoldAllow m12 : 8|1@1+ (1,0) [0|1] "" Vector__XXX
 SG_ VCRIGHT_2RowSeatReclineUnfoldAll m12 : 9|1@1+ (1,0) [0|1] "" Vector__XXX
 SG_ VCRIGHT_2RowSeatReclineNextToggl m12 : 10|2@1+ (1,0) [0|3] "" Vector__XXX
 SG_ VCRIGHT_2RowSeatReclineChoreoBlo m12 : 12|1@1+ (1,0) [0|1] "" Vector__XXX
 SG_ VCRIGHT_2RowSeat1RClashAvoidance m12 : 13|3@1+ (1,0) [0|7] "" Vector__XXX
 SG_ VCRIGHT_2RowSeat1RClashAvoi_0001 m12 : 16|2@1+ (1,0) [0|3] "" Vector__XXX
 SG_ VCRIGHT_2RowSeatReclineAbsP_0001 m12 : 18|12@1- (0.1,0) [-204.8|204.7] "deg" Vector__XXX
 SG_ VC_AH_2RowRightSeatMovementHealt m12 : 53|3@1+ (1,0) [0|7] "" Vector__XXX
 SG_ VCRIGHT_3RowSeatReclineState m14 : 4|4@1+ (1,0) [0|14] "" Vector__XXX
 SG_ VCRIGHT_3RowSeatReclineDuty m14 : 8|8@1- (1,0) [-100|100] "%" Vector__XXX
 SG_ VCRIGHT_3RowSeatReclineCurrent m14 : 16|12@1- (0.05,0) [-100|100] "A" Vector__XXX
 SG_ VCRIGHT_3RowSeatReclineCalibrate m14 : 28|1@1+ (1,0) [0|1] "" Vector__XXX
 SG_ VCRIGHT_3RowSeatReclinePositionR m14 : 29|12@1- (1,0) [-2048|2047] "" Vector__XXX
 SG_ VCRIGHT_3RowSeatReclineAngle m14 : 41|12@1- (0.1,0) [-204.8|204.7] "deg" Vector__XXX
 SG_ VCRIGHT_3RowSeatReclineNextToggl m14 : 53|2@1+ (1,0) [0|3] "" Vector__XXX
 SG_ VCRIGHT_3RRightSeatHeatCurrent m15 : 5|12@1+ (0.01,0) [0|40.95] "A" Vector__XXX
 SG_ VCRIGHT_3RRightSeatHeatDuty m15 : 17|8@1- (1,0) [-100|100] "%" Vector__XXX
 SG_ VCRIGHT_3RRightSeatHeatTmp m15 : 25|12@1- (0.05,0) [-40|80] "degC" Vector__XXX
 SG_ VCRIGHT_3RRightSeatHeatTmpTarget m15 : 37|8@1- (0.5,0) [0|60] "degC" Vector__XXX
 SG_ VCRIGHT_3RRightSeatHeatInhibited m15 : 45|1@1+ (1,0) [0|1] "" Vector__XXX
 SG_ VCRIGHT_3RowSeatReclinePositionS m15 : 46|3@1+ (1,0) [0|7] "" Vector__XXX
 SG_ VCRIGHT_3RowSeatReclineAdjustmen m15 : 49|1@1+ (1,0) [0|1] "" Vector__XXX
 SG_ VCRIGHT_3RowSeatReclineFoldAllow m15 : 50|1@1+ (1,0) [0|1] "" Vector__XXX
 SG_ VCRIGHT_3RowSeatReclineUnfoldAll m15 : 51|1@1+ (1,0) [0|1] "" Vector__XXX
 SG_ VCRIGHT_3RowSeatReclineChoreoBlo m15 : 52|1@1+ (1,0) [0|1] "" Vector__XXX
 SG_ VCRIGHT_3RowSeatReclineAbsPosSwi m15 : 53|2@1+ (1,0) [1|3] "" Vector__XXX

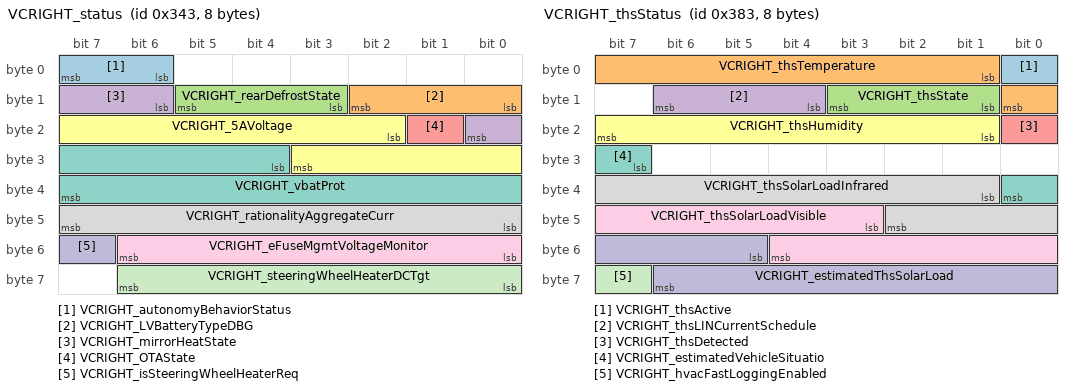
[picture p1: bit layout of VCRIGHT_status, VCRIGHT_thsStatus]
BO_ 835 VCRIGHT_status: 8 VCRIGHT
 SG_ VCRIGHT_autonomyBehaviorStatus : 6|2@1+ (1,0) [0|3] "" Vector__XXX
 SG_ VCRIGHT_LVBatteryTypeDBG : 8|3@1+ (1,0) [0|7] "" Vector__XXX
 SG_ VCRIGHT_rearDefrostState : 11|3@1+ (1,0) [1|7] "" Vector__XXX
 SG_ VCRIGHT_mirrorHeatState : 14|3@1+ (1,0) [1|7] "" Vector__XXX
 SG_ VCRIGHT_OTAState : 17|1@1+ (1,0) [0|1] "" Vector__XXX
 SG_ VCRIGHT_5AVoltage : 18|10@1+ (0.005443676,0) [0|5.568880548] "V" Vector__XXX
 SG_ VCRIGHT_vbatProt : 28|12@1+ (0.005443676,0) [0|22.29185322] "V" Vector__XXX
 SG_ VCRIGHT_rationalityAggregateCurr : 40|8@1+ (0.5,0) [0|127.5] "A" Vector__XXX
 SG_ VCRIGHT_eFuseMgmtVoltageMonitor : 48|7@1+ (0.125,0) [0|15.875] "V" Vector__XXX
 SG_ VCRIGHT_isSteeringWheelHeaterReq : 55|1@1+ (1,0) [0|1] "" Vector__XXX
 SG_ VCRIGHT_steeringWheelHeaterDCTgt : 56|7@1+ (0.01,0) [0|1] "-" Vector__XXX

BO_ 899 VCRIGHT_thsStatus: 8 VCRIGHT
 SG_ VCRIGHT_thsActive : 0|1@1+ (1,0) [0|1] "" Vector__XXX
 SG_ VCRIGHT_thsTemperature : 1|8@1+ (1,-40) [-40|150] "degC" Vector__XXX
 SG_ VCRIGHT_thsState : 9|3@1+ (1,0) [0|7] "" Vector__XXX
 SG_ VCRIGHT_thsLINCurrentSchedule : 12|3@1+ (1,0) [0|7] "" Vector__XXX
 SG_ VCRIGHT_thsDetected : 16|1@1+ (1,0) [0|1] "" Vector__XXX
 SG_ VCRIGHT_thsHumidity : 17|7@1+ (1,0) [0|100] "%" Vector__XXX
 SG_ VCRIGHT_estimatedVehicleSituatio : 31|2@1+ (1,0) [0|3] "" Vector__XXX
 SG_ VCRIGHT_thsSolarLoadInfrared : 33|10@1+ (2,0) [0|2044] "W/m2" Vector__XXX
 SG_ VCRIGHT_thsSolarLoadVisible : 43|10@1+ (2,0) [0|2044] "W/m2" Vector__XXX
 SG_ VCRIGHT_estimatedThsSolarLoad : 53|10@1+ (1,0) [0|1022] "W/m2" Vector__XXX
 SG_ VCRIGHT_hvacFastLoggingEnabled : 63|1@1+ (1,0) [0|1] "" Vector__XXX

BO_ 1066 VCSEC_TPMSConnectionData: 8 VCSEC
 SG_ VCSEC_TPMSSensorState0 : 0|3@1+ (1,0) [0|7] "" Vector__XXX
 SG_ VCSEC_TPMSRSSI0 : 3|7@1+ (1,-127) [-127|0] "dBm" Vector__XXX
 SG_ VCSEC_TPMSConnectionTypeCurrent0 : 10|2@1+ (1,0) [0|3] "" Vector__XXX
 SG_ VCSEC_TPMSConnectionTypeDesired0 : 12|2@1+ (1,0) [0|3] "" Vector__XXX
 SG_ VCSEC_TPMSSensorState1 : 14|3@1+ (1,0) [0|7] "" Vector__XXX
 SG_ VCSEC_TPMSRSSI1 : 17|7@1+ (1,-127) [-127|0] "dBm" Vector__XXX
 SG_ VCSEC_TPMSConnectionTypeCurrent1 : 24|2@1+ (1,0) [0|3] "" Vector__XXX
 SG_ VCSEC_TPMSConnectionTypeDesired1 : 26|2@1+ (1,0) [0|3] "" Vector__XXX
 SG_ VCSEC_TPMSSensorState2 : 28|3@1+ (1,0) [0|7] "" Vector__XXX
 SG_ VCSEC_TPMSRSSI2 : 31|7@1+ (1,-127) [-127|0] "dBm" Vector__XXX
 SG_ VCSEC_TPMSConnectionTypeCurrent2 : 38|2@1+ (1,0) [0|3] "" Vector__XXX
 SG_ VCSEC_TPMSConnectionTypeDesired2 : 40|2@1+ (1,0) [0|3] "" Vector__XXX
 SG_ VCSEC_TPMSSensorState3 : 42|3@1+ (1,0) [0|7] "" Vector__XXX
 SG_ VCSEC_TPMSRSSI3 : 45|7@1+ (1,-127) [-127|0] "dBm" Vector__XXX
 SG_ VCSEC_TPMSConnectionTypeCurrent3 : 52|2@1+ (1,0) [0|3] "" Vector__XXX
 SG_ VCSEC_TPMSConnectionTypeDesired3 : 54|2@1+ (1,0) [0|3] "" Vector__XXX
 SG_ VCSEC_TPMSSensorPresence0 : 56|2@1+ (1,0) [0|3] "" Vector__XXX
 SG_ VCSEC_TPMSSensorPresence1 : 58|2@1+ (1,0) [0|3] "" Vector__XXX
 SG_ VCSEC_TPMSSensorPresence2 : 60|2@1+ (1,0) [0|3] "" Vector__XXX
 SG_ VCSEC_TPMSSensorPresence3 : 62|2@1+ (1,0) [0|3] "" Vector__XXX

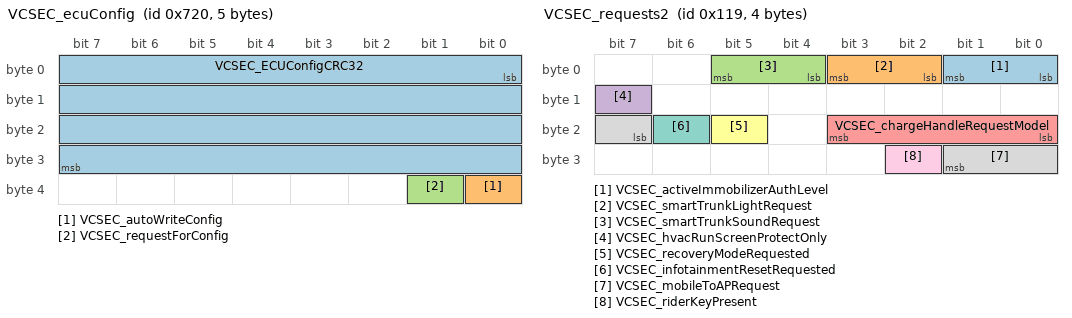
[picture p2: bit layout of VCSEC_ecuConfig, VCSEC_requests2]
BO_ 1824 VCSEC_ecuConfig: 5 VCSEC
 SG_ VCSEC_ECUConfigCRC32 : 0|32@1+ (1,0) [0|4294967295] "" Vector__XXX
 SG_ VCSEC_autoWriteConfig : 32|1@1+ (1,0) [0|1] "" Vector__XXX
 SG_ VCSEC_requestForConfig : 33|1@1+ (1,0) [0|1] "" Vector__XXX

BO_ 281 VCSEC_requests2: 4 VCSEC
 SG_ VCSEC_activeImmobilizerAuthLevel : 0|2@1+ (1,0) [0|3] "" Vector__XXX
 SG_ VCSEC_smartTrunkLightRequest : 2|2@1+ (1,0) [0|3] "" Vector__XXX
 SG_ VCSEC_smartTrunkSoundRequest : 4|2@1+ (1,0) [0|3] "" Vector__XXX
 SG_ VCSEC_hvacRunScreenProtectOnly : 15|1@1+ (1,0) [0|1] "" Vector__XXX
 SG_ VCSEC_chargeHandleRequestModel : 16|4@1+ (1,0) [0|15] "" Vector__XXX
 SG_ VCSEC_recoveryModeRequested : 21|1@1+ (1,0) [0|1] "" Vector__XXX
 SG_ VCSEC_infotainmentResetRequested : 22|1@1+ (1,0) [0|1] "" Vector__XXX
 SG_ VCSEC_mobileToAPRequest : 23|3@1+ (1,0) [0|7] "" Vector__XXX
 SG_ VCSEC_riderKeyPresent : 26|1@1+ (1,0) [0|1] "" Vector__XXX

BO_TX_BU_ 1353 : VCFRONT;
BO_TX_BU_ 1801 : VCFRONT;
BO_TX_BU_ 957 : VCFRONT;
BO_TX_BU_ 737 : VCFRONT;
BO_TX_BU_ 507 : VCLEFT;
BO_TX_BU_ 292 : VCLEFT;
BO_TX_BU_ 1802 : VCLEFT;
BO_TX_BU_ 930 : VCLEFT;
BO_TX_BU_ 962 : VCLEFT;
BO_TX_BU_ 1114 : VCRIGHT;
BO_TX_BU_ 1795 : VCRIGHT;
BO_TX_BU_ 291 : VCRIGHT;
BO_TX_BU_ 739 : VCRIGHT;
BO_TX_BU_ 835 : VCRIGHT;
BO_TX_BU_ 899 : VCRIGHT;
BO_TX_BU_ 1066 : VCSEC;
BO_TX_BU_ 1824 : VCSEC;
BO_TX_BU_ 281 : VCSEC;
CM_ BO_ 1353 "Front body controller message: homelink";
CM_ SG_ 1353 VCFRONT_homelinkV2Response0 "Front body controller: homelink V2 response0";
CM_ SG_ 1353 VCFRONT_homelinkV2Response1 "Front body controller: homelink V2 response1";
CM_ SG_ 1353 VCFRONT_homelinkV2Response2 "Front body controller: homelink V2 response2";
CM_ SG_ 1353 VCFRONT_homelinkV2Response3 "Front body controller: homelink V2 response3";
CM_ SG_ 1353 VCFRONT_homelinkV2Response4 "Front body controller: homelink V2 response4";
CM_ SG_ 1353 VCFRONT_homelinkCommStatus "Homelink communication status; raw 0 = signal not available (SNA)";
CM_ BO_ 1801 "Front body controller message: logging0point1 hz";
CM_ SG_ 1801 VCFRONT_logging0point1HzIndex "Front body controller: logging0point1 hz index";
CM_ SG_ 1801 VC_hcmlFactoryOfOrigin "Tier 1 supplier (Hella) factory of origin of the left headlamp";
CM_ SG_ 1801 VC_hcmlHellaPartNumberStatus "Front body controller: hcml hella part number status";
CM_ SG_ 1801 VC_hcmlHellaPartNumber "Value of the Hella Part Number written into EEPROM in the left headlamp";
CM_ SG_ 1801 VC_hcmlCurrentBinMappingType "Front body controller: hcml current bin mapping type";
CM_ SG_ 1801 VC_hcmlCurrentBin0Value "Front body controller: hcml current bin0 value; raw 0 = signal not available (SNA)";
CM_ SG_ 1801 VC_hcmlCurrentBin1Value "Front body controller: hcml current bin1 value; raw 0 = signal not available (SNA)";
CM_ SG_ 1801 VC_hcmlCurrentBin2Value "Front body controller: hcml current bin2 value; raw 0 = signal not available (SNA)";
CM_ SG_ 1801 VC_hcmlCurrentBin3Value "Front body controller: hcml current bin3 value; raw 0 = signal not available (SNA)";
CM_ SG_ 1801 VC_hcmlCurrentBin4Value "Front body controller: hcml current bin4 value; raw 0 = signal not available (SNA)";
CM_ SG_ 1801 VC_hcmlCurrentBin5Value "Front body controller: hcml current bin5 value; raw 0 = signal not available (SNA)";
CM_ SG_ 1801 VC_hcmlRegionAndSide "Left headlamp EEPROM region and side; raw 0 = signal not available (SNA)";
CM_ SG_ 1801 VC_hcmrFactoryOfOrigin "Tier 1 supplier (Hella) factory of origin of the right headlamp";
CM_ SG_ 1801 VC_hcmrHellaPartNumberStatus "Front body controller: hcmr hella part number status";
CM_ SG_ 1801 VC_hcmrHellaPartNumber "Value of the Hella Part Number written into EEPROM in the right headlamp";
CM_ SG_ 1801 VC_hcmrCurrentBinMappingType "Front body controller: hcmr current bin mapping type";
CM_ SG_ 1801 VC_hcmrCurrentBin0Value "Front body controller: hcmr current bin0 value; raw 0 = signal not available (SNA)";
CM_ SG_ 1801 VC_hcmrCurrentBin1Value "Front body controller: hcmr current bin1 value; raw 0 = signal not available (SNA)";
CM_ SG_ 1801 VC_hcmrCurrentBin2Value "Front body controller: hcmr current bin2 value; raw 0 = signal not available (SNA)";
CM_ SG_ 1801 VC_hcmrCurrentBin3Value "Front body controller: hcmr current bin3 value; raw 0 = signal not available (SNA)";
CM_ SG_ 1801 VC_hcmrCurrentBin4Value "Front body controller: hcmr current bin4 value; raw 0 = signal not available (SNA)";
CM_ SG_ 1801 VC_hcmrCurrentBin5Value "Front body controller: hcmr current bin5 value; raw 0 = signal not available (SNA)";
CM_ SG_ 1801 VC_hcmrRegionAndSide "Right headlamp EEPROM region and side; raw 0 = signal not available (SNA)";
CM_ BO_ 957 "Front body controller message: parked energy loss";
CM_ SG_ 957 VCFRONT_energyLossIndex "Front body controller: energy loss index";
CM_ SG_ 957 VCFRONT_userEnergyLossSinceDrive "Energy loss due to user interaction since last drive";
CM_ SG_ 957 VCFRONT_preconditioningEner_0001 "Energy loss due to preconditioning since last drive";
CM_ SG_ 957 VCFRONT_cabinOverheatEnergy_0001 "Energy loss due to cabin overheat protection since last drive";
CM_ SG_ 957 VCFRONT_mobileAppEnergyLoss_0001 "Energy loss due to mobile app interaction since last drive";
CM_ SG_ 957 VCFRONT_summonStandbyEnergy_0001 "Energy loss due to summon standby since last drive";
CM_ SG_ 957 VCFRONT_sentryModeEnergyLos_0001 "Energy loss due to sentry mode since last drive";
CM_ SG_ 957 VCFRONT_backgroundEnergyLos_0001 "Energy loss due to background vehicle op since last drive";
CM_ SG_ 957 VCFRONT_evapDryingEnergyLos_0001 "Energy loss due to evap drying since last drive";
CM_ SG_ 957 VCFRONT_userEnergyLossSinceCharg "Energy loss due to user interaction since last charge";
CM_ SG_ 957 VCFRONT_preconditioningEnergyLos "Energy loss due to preconditioning since last charge";
CM_ SG_ 957 VCFRONT_cabinOverheatEnergyLossS "Energy loss due to cabin overheat protection since last charge";
CM_ SG_ 957 VCFRONT_mobileAppEnergyLossSince "Energy loss due to mobile app interaction since last charge";
CM_ SG_ 957 VCFRONT_summonStandbyEnergyLossS "Energy loss due to summon standby since last charge";
CM_ SG_ 957 VCFRONT_sentryModeEnergyLossSinc "Energy loss due to sentry mode since last charge";
CM_ SG_ 957 VCFRONT_backgroundEnergyLossSinc "Energy loss due to background vehicle op since last charge";
CM_ SG_ 957 VCFRONT_evapDryingEnergyLossSinc "Energy loss due to evap drying since last charge";
CM_ BO_ 737 "Front body controller message: status";
CM_ SG_ 737 VCFRONT_statusIndex "Front body controller: status index";
CM_ SG_ 737 VCFRONT_frunkLatchStatus "Front body controller: frunk latch status; raw 0 = signal not available (SNA)";
CM_ SG_ 737 VCFRONT_wiperSpeed "Front body controller: wiper speed; raw 0 = signal not available (SNA)";
CM_ SG_ 737 VCFRONT_wiperPosition "Wiper position; raw 0 = signal not available (SNA)";
CM_ SG_ 737 VCFRONT_wiperBlocked "Wiper ECU is reporting a block";
CM_ SG_ 737 VCFRONT_wiperState "Front body controller: wiper state; raw 0 = signal not available (SNA)";
CM_ SG_ 737 VCFRONT_crashDetectedType "Front body controller: crash detected type";
CM_ SG_ 737 VCFRONT_crashState "Front body controller: crash state";
CM_ SG_ 737 VCFRONT_crashUnlockOverrideSet "Indication that vehicle lock state has been overridden due to a collision.";
CM_ SG_ 737 VCFRONT_washPumpState "Front body controller: wash pump state; raw 1 = signal not available (SNA)";
CM_ SG_ 737 VCFRONT_turnIndicatorControlType "Turn indicator control hardware variant";
CM_ SG_ 737 VCFRONT_wiperHealth "Health metric to track the power and communication state of the wiper module";
CM_ SG_ 737 VCFRONT_wiperLINHealth "Health metric to track the power and communication state of the wiper module";
CM_ SG_ 737 VCFRONT_frunkLatchCurrent "Reports the current used by the frunk latch.";
CM_ SG_ 737 VCFRONT_frunkInteriorRelSwitch "State of the frunk interior release switch";
CM_ SG_ 737 VCFRONT_anyClosureOpen "Front body controller: any closure open";
CM_ SG_ 737 VCFRONT_anyDoorOpen "Front body controller: any door open";
CM_ SG_ 737 VCFRONT_hornOn "Indication that the horn is on";
CM_ SG_ 737 VCFRONT_radarHeaterState "Front body controller: radar heater state; raw 0 = signal not available (SNA)";
CM_ SG_ 737 VCFRONT_trunkExteriorWakeSwitch "State of the trunk exterior switch, used for wake only";
CM_ SG_ 737 VCFRONT_passengerBuckleStatus "State of the passenger's seat belt buckle";
CM_ SG_ 737 VCFRONT_frunkLatchType "Front body controller: frunk latch type";
CM_ SG_ 737 VCFRONT_headlampLeftFanStatus "Front body controller: headlamp left fan status";
CM_ SG_ 737 VCFRONT_headlampRightFanStatus "Front body controller: headlamp right fan status";
CM_ SG_ 737 VCFRONT_frunkAccessPost "Front body controller: frunk access post";
CM_ SG_ 737 VCFRONT_isActiveHeatingBattery "Front body controller: is active heating battery";
CM_ SG_ 737 VCFRONT_iBoosterWakeLine "Front body controller: i booster wake line";
CM_ SG_ 737 VCFRONT_epasWakeLine "Front body controller: epas wake line";
CM_ SG_ 737 VCFRONT_iBoosterStateDBG "Front body controller: i booster state DBG";
CM_ SG_ 737 VCFRONT_vehicleStatusDBG "Vehicle state machine state debug; raw 18 = signal not available (SNA)";
CM_ SG_ 737 VCFRONT_timeSpentSleeping "Measures time elapsed while the vehicle has been sleeping.";
CM_ SG_ 737 VCFRONT_sleepCurrent "Calculated electrical current into the 12V battery during VCFRONT sleep; raw 4095 = signal not available (SNA)";
CM_ SG_ 737 VCFRONT_hibernationState "Front body controller: hibernation state";
CM_ SG_ 737 VCFRONT_wiperECUType "Wiper ECU type detected";
CM_ SG_ 737 VCFRONT_wiperHeaterState "Indicates the state of the wiper heater; raw 0 = signal not available (SNA)";
CM_ SG_ 737 VCFRONT_occupantCount "Front body controller: occupant count";
CM_ SG_ 737 VCFRONT_closureEasterEggState "Front body controller: closure easter egg state";
CM_ SG_ 737 VCFRONT_espWakeLine "Front body controller: esp wake line";
CM_ SG_ 737 VCFRONT_allowEvapInLowAmbient "Front body controller: allow evap in low ambient";
CM_ SG_ 737 VCFRONT_potentialRadiatorSteam "Front body controller: potential radiator steam";
CM_ SG_ 737 VCFRONT_potentialRadiatorSteamUI "Front body controller: potential radiator steam UI";
CM_ SG_ 737 VCFRONT_hvacReqOffForFasterCharg "Reports if turning Heating, Ventilation, and Air Conditioning (HVAC) off may improve supercharging power.";
CM_ SG_ 737 VCFRONT_limitedSplitTempDeltaEnf "Front body controller: limited split temp delta enforced";
CM_ SG_ 737 VCFRONT_batteryDischArbState "Front body controller: battery disch arb state";
CM_ SG_ 737 VCFRONT_maxEvapHeatRejection "Front body controller: max evap heat rejection";
CM_ SG_ 737 VCFRONT_minEvapHeatRejection "Front body controller: min evap heat rejection";
CM_ SG_ 737 VCFRONT_freezeEvapITerm "Front body controller: freeze evap i term";
CM_ SG_ 737 VCFRONT_isEvapOperationAllowed "Front body controller: is evap operation allowed";
CM_ SG_ 737 VCFRONT_chillerDemandActive "Front body controller: chiller demand active";
CM_ SG_ 737 VCFRONT_compPerfRecoveryLimited "Front body controller: comp perf recovery limited";
CM_ SG_ 737 VCFRONT_hvacModeNotAttainable "Front body controller: hvac mode not attainable";
CM_ SG_ 737 VCFRONT_hasLowRefrigerant "Front body controller: has low refrigerant";
CM_ SG_ 737 VCFRONT_isColdStartRunning "Front body controller: is cold start running";
CM_ SG_ 737 VCFRONT_isHeatPumpOilPurgeActive "Front body controller: is heat pump oil purge active";
CM_ SG_ 737 VCFRONT_pressureRefrigSuction "Refrigerant system suction pressure; raw 127 = signal not available (SNA)";
CM_ SG_ 737 VCFRONT_pressureRefrigDischarge "Refrigerant system discharge pressure; raw 511 = signal not available (SNA)";
CM_ SG_ 737 VCFRONT_hvacPerfTestCommand "Front body controller: hvac perf test command";
CM_ SG_ 737 VCFRONT_coolantFillRoutineStatus "Front body controller: coolant fill routine status";
CM_ SG_ 737 VCFRONT_refrigFillRoutineStatus "Front body controller: refrig fill routine status";
CM_ SG_ 737 VCFRONT_isCOP1Running "Front body controller: is COP1 running";
CM_ SG_ 737 VCFRONT_closeValvesRoutineStatus "Front body controller: close valves routine status";
CM_ SG_ 737 VCFRONT_thermalPerfTestRunning "Front body controller: thermal perf test running";
CM_ SG_ 737 VCFRONT_extendedHvacPerfTestComm "Front body controller: extended hvac perf test command";
CM_ SG_ 737 VCFRONT_5VARailStable "Front body controller: 5 VA rail stable";
CM_ SG_ 737 VCFRONT_5VBRailStable "Front body controller: 5 VB rail stable";
CM_ SG_ 737 VCFRONT_12VARailStable "Front body controller: 12 VA rail stable";
CM_ SG_ 737 VCFRONT_12VBRailStable "Front body controller: 12 VB rail stable";
CM_ SG_ 737 VCFRONT_railAState "Front body controller: rail a state";
CM_ SG_ 737 VCFRONT_railBState "Front body controller: rail b state";
CM_ SG_ 737 VCFRONT_ChargePumpVoltageStable "Front body controller: charge pump voltage stable";
CM_ SG_ 737 VCFRONT_PEResetLineState "Front body controller: PE reset line state";
CM_ SG_ 737 VCFRONT_HSDInitCompleteU13 "Front body controller: HSD init complete U13";
CM_ SG_ 737 VCFRONT_HSDInitCompleteU16 "Front body controller: HSD init complete U16";
CM_ SG_ 737 VCFRONT_vbatMonitorVoltage "Front body controller: vbat monitor voltage; raw 4095 = signal not available (SNA)";
CM_ SG_ 737 VCFRONT_AS8510Voltage "Front body controller: AS8510 voltage; raw 4095 = signal not available (SNA)";
CM_ SG_ 737 VCFRONT_vbatProt "Front body controller: vbat prot";
CM_ SG_ 737 VCFRONT_logVerbosity "Front body controller: log verbosity";
CM_ SG_ 737 VCFRONT_cabinCoolingCapacityLimi "Front body controller: cabin cooling capacity limited";
CM_ SG_ 737 VCFRONT_cabinHeatingCapacityLimi "Front body controller: cabin heating capacity limited";
CM_ SG_ 737 VCFRONT_compPowerSupportingHvac "Front body controller: comp power supporting hvac";
CM_ SG_ 737 VCFRONT_compPowerSupportingPT "Front body controller: comp power supporting PT";
CM_ SG_ 737 VCFRONT_maxHeatingPowerLeftCC "Front body controller: max heating power left CC";
CM_ SG_ 737 VCFRONT_maxHeatingPowerRightCC "Front body controller: max heating power right CC";
CM_ SG_ 737 VCFRONT_activeLouverOpenPos "The actual position for the active louver";
CM_ SG_ 737 VCFRONT_activeLouverState "State of the active louver circuit";
CM_ SG_ 737 VCFRONT_windshieldCameraHeaterPo "Front body controller: windshield camera heater power; raw 63 = signal not available (SNA)";
CM_ BO_ 507 "Left body controller message: TLC status";
CM_ SG_ 507 VCLEFT_TLCStatusIndex "Left body controller: TLC status index";
CM_ SG_ 507 VCLEFT_TLCTemperature "Monitors board temperatures for electrical validation.; raw 128 = signal not available (SNA)";
CM_ SG_ 507 VCLEFT_TLCLeftTurnVoltage "Reports voltage for analysis of in field issues.; raw 255 = signal not available (SNA)";
CM_ SG_ 507 VCLEFT_TLCRightTurnVoltage "Reports voltage for analysis of in field issues.; raw 255 = signal not available (SNA)";
CM_ SG_ 507 VCLEFT_TLCState_LeftTurn "Reports trailer light status.; raw 5 = signal not available (SNA)";
CM_ SG_ 507 VCLEFT_TLCState_RightTurn "Reports trailer light status.; raw 5 = signal not available (SNA)";
CM_ SG_ 507 VCLEFT_TLCState_Tail "Reports trailer light status.; raw 5 = signal not available (SNA)";
CM_ SG_ 507 VCLEFT_TLCState_Stop "Reports trailer light status.; raw 5 = signal not available (SNA)";
CM_ SG_ 507 VCLEFT_TLCState_Fog "Reports trailer light status.; raw 5 = signal not available (SNA)";
CM_ SG_ 507 VCLEFT_TLCState_Reverse "Reports trailer light status.; raw 5 = signal not available (SNA)";
CM_ BO_ 292 "Left body controller message: liftgate leader request";
CM_ SG_ 292 VCLEFT_liftgateRequestAction "Action of dual strut PLG requested by the leader";
CM_ SG_ 292 VCLEFT_liftgateRequestTargetDuty "Left body controller: liftgate request target duty";
CM_ SG_ 292 VCLEFT_liftgateRequestTargetAngl "Left body controller: liftgate request target angle";
CM_ SG_ 292 VCLEFT_liftgateRequestTargetPara "Left body controller: liftgate request target param";
CM_ SG_ 292 VCLEFT_adaptiveLiftgateControlMo "Indicates if adaptive liftgate control mode is active";
CM_ SG_ 292 VCLEFT_liftgateReqObsDetMode "Pinch mode requrest by the PLG leader";
CM_ SG_ 292 VCLEFT_liftgateReqResetStrutCoun "Set strut count reset request from the leader";
CM_ SG_ 292 VCLEFT_liftgateReqClearCal "Request follower strut ro clear it calibration";
CM_ SG_ 292 VCLEFT_liftgateTargetTerminalSpe "Left body controller: liftgate target terminal speed";
CM_ SG_ 292 VCLEFT_liftgateReqCoastPercent "Reports the percentage of time to coast the strut.";
CM_ SG_ 292 VCLEFT_liftgateReqDutyScale "Reports the amount to scale duty from current value to ramp to for a LATCH_CURRENT_SCALED request";
CM_ BO_ 1802 "Left body controller message: logging0point1 hz";
CM_ SG_ 1802 VCLEFT_logging0point1HzIndex "Left body controller: logging0point1 hz index";
CM_ SG_ 1802 VCLEFT_leftBrakeTailLightCurrent "Current sensed by the left brake tail light HSD (high side driver).; raw 511 = signal not available (SNA)";
CM_ SG_ 1802 VCLEFT_leftBrakeTailLightCu_0001 "State representing validity of the left brake tail light HSD (high side driver) current sense.; raw 0 = signal not available (SNA)";
CM_ SG_ 1802 VCLEFT_leftRearTurnLightCurrent "Current sensed by the left rear turn signal HSD (high side driver).; raw 511 = signal not available (SNA)";
CM_ SG_ 1802 VCLEFT_leftRearTurnLightCurrentS "State representing validity of the left rear turn signal HSD (high side driver) current sense.; raw 0 = signal not available (SNA)";
CM_ SG_ 1802 VCLEFT_phoneTemperatureFL "Temperature of front left wireless phone charger (if installed); raw 128 = signal not available (SNA)";
CM_ SG_ 1802 VCLEFT_phoneTemperatureFR "Temperature of front right wireless phone charger (if installed); raw 128 = signal not available (SNA)";
CM_ SG_ 1802 VCLEFT_canAuthResyncDurationMs "Left body controller: can auth resync duration ms";
CM_ BO_ 930 "Left body controller message: status";
CM_ SG_ 930 VCLEFT_statusIndex "Left body controller: status index";
CM_ SG_ 930 VCLEFT_securityControllerEnable "Left body controller: security controller enable";
CM_ SG_ 930 VCLEFT_securityControllerVoltage "Voltage of the VCSEC power feed";
CM_ SG_ 930 VCLEFT_consoleDoorAssist "Left body controller: console door assist";
CM_ SG_ 930 VCLEFT_OTAState "Left body controller: OTA state";
CM_ SG_ 930 VCLEFT_5AVoltage "Left body controller: 5 a voltage";
CM_ SG_ 930 VCLEFT_vbatProt "Left body controller: vbat prot";
CM_ SG_ 930 VCLEFT_footwellLightCurrent "Left body controller: footwell light current";
CM_ SG_ 930 VCLEFT_swcInputVoltage "Input voltage reported by steering wheel controller module; raw 255 = signal not available (SNA)";
CM_ SG_ 930 VCLEFT_swcPCBATemperature "Left body controller: swc PCBA temperature; raw 128 = signal not available (SNA)";
CM_ SG_ 930 VCLEFT_obdEthernetActive "Left body controller: obd ethernet active";
CM_ SG_ 930 VCLEFT_rationalityAggregateCurre "Left body controller: rationality aggregate current";
CM_ SG_ 930 VCLEFT_LVBatteryTypeDBG "Left body controller: LV battery type DBG";
CM_ SG_ 930 VCLEFT_DIeFuseFault "Left body controller: d ie fuse fault";
CM_ SG_ 930 VCLEFT_eFuseMgmtVoltageMonitor "Left body controller: e fuse mgmt voltage monitor";
CM_ SG_ 930 VCLEFT_trailerAuxCurrent "Current Draw of the trailer aux output; raw 4095 = signal not available (SNA)";
CM_ SG_ 930 VCLEFT_swcHeatTmp "Temperature of steering wheel heater as reported by NTC; raw 1023 = signal not available (SNA)";
CM_ SG_ 930 VCLEFT_swcHeatStatus "Status of steering wheel heater; raw 0 = signal not available (SNA)";
CM_ SG_ 930 VCLEFT_swcHeatInhibited "Status describing whether steering wheel heat is inhibited";
CM_ SG_ 930 VCLEFT_obdDeviceDetected "Reports whether the Left Vehicle Controller (VCLEFT) detects that an external device is connected to the OBD port.";
CM_ SG_ 930 VCLEFT_pcbaTemperature "Left body controller: pcba temperature";
CM_ SG_ 930 VCLEFT_swcHeatPwr "Power of steering wheel heater; raw 511 = signal not available (SNA)";
CM_ SG_ 930 VCLEFT_swcHeatDutyCycle "Steering wheel heater duty cycle; raw 127 = signal not available (SNA)";
CM_ SG_ 930 VCLEFT_DIeFuseCurrent "Left body controller: d ie fuse current";
CM_ SG_ 930 VCLEFT_SWCpresent "Left body controller: SW cpresent";
CM_ SG_ 930 VCLEFT_trailerBrakeControllerCur "Value of the trailer brake controller HSD (high side driver) current sense.";
CM_ SG_ 930 VCLEFT_autonomyBehaviorStatus "Left body controller: autonomy behavior status";
CM_ SG_ 930 VCLEFT_thirdRowLeftMapLightStatu "Reports the status of the third row left overhead map light.; raw 3 = signal not available (SNA)";
CM_ SG_ 930 VCLEFT_thirdRowRightMapLightStat "Reports the status of the third row right overhead map light; raw 3 = signal not available (SNA)";
CM_ BO_ 962 "Left body controller message: switch status";
CM_ SG_ 962 VCLEFT_switchStatusIndex "Left body controller: switch status index";
CM_ SG_ 962 VCLEFT_hornSwitchPressed "Left body controller: horn switch pressed";
CM_ SG_ 962 VCLEFT_hazardButtonPressed "Left body controller: hazard button pressed";
CM_ SG_ 962 VCLEFT_brakeSwitchPressed "Status of the brake pedal switch";
CM_ SG_ 962 VCLEFT_rightMirrorTilt "Left body controller: right mirror tilt";
CM_ SG_ 962 VCLEFT_frontSeatTrackBack "Left body controller: front seat track back; raw 0 = signal not available (SNA)";
CM_ SG_ 962 VCLEFT_frontSeatTrackForward "Left body controller: front seat track forward; raw 0 = signal not available (SNA)";
CM_ SG_ 962 VCLEFT_frontSeatTiltDown "Left body controller: front seat tilt down; raw 0 = signal not available (SNA)";
CM_ SG_ 962 VCLEFT_frontSeatTiltUp "Left body controller: front seat tilt up; raw 0 = signal not available (SNA)";
CM_ SG_ 962 VCLEFT_frontSeatLiftDown "Left body controller: front seat lift down; raw 0 = signal not available (SNA)";
CM_ SG_ 962 VCLEFT_frontSeatLiftUp "Left body controller: front seat lift up; raw 0 = signal not available (SNA)";
CM_ SG_ 962 VCLEFT_frontSeatBackrestBack "Left body controller: front seat backrest back; raw 0 = signal not available (SNA)";
CM_ SG_ 962 VCLEFT_frontSeatBackrestForward "Left body controller: front seat backrest forward; raw 0 = signal not available (SNA)";
CM_ SG_ 962 VCLEFT_frontSeatLumbarDown "Left body controller: front seat lumbar down; raw 0 = signal not available (SNA)";
CM_ SG_ 962 VCLEFT_frontSeatLumbarUp "Left body controller: front seat lumbar up; raw 0 = signal not available (SNA)";
CM_ SG_ 962 VCLEFT_frontSeatLumbarIn "Left body controller: front seat lumbar in; raw 0 = signal not available (SNA)";
CM_ SG_ 962 VCLEFT_frontSeatLumbarOut "Left body controller: front seat lumbar out; raw 0 = signal not available (SNA)";
CM_ SG_ 962 VCLEFT_btnWindowSwPackUpLF "Left body controller: btn window sw pack up LF";
CM_ SG_ 962 VCLEFT_btnWindowSwPackAutoUpLF "Left body controller: btn window sw pack auto up LF";
CM_ SG_ 962 VCLEFT_btnWindowSwPackDownLF "Left body controller: btn window sw pack down LF";
CM_ SG_ 962 VCLEFT_btnWindowSwPackAutoDownLF "Left body controller: btn window sw pack auto down LF";
CM_ SG_ 962 VCLEFT_btnWindowSwPackUpLR "Left body controller: btn window sw pack up LR";
CM_ SG_ 962 VCLEFT_btnWindowSwPackAutoUpLR "Left body controller: btn window sw pack auto up LR";
CM_ SG_ 962 VCLEFT_btnWindowSwPackDownLR "Left body controller: btn window sw pack down LR";
CM_ SG_ 962 VCLEFT_btnWindowSwPackAutoDownLR "Left body controller: btn window sw pack auto down LR";
CM_ SG_ 962 VCLEFT_btnWindowSwPackUpRF "Left body controller: btn window sw pack up RF";
CM_ SG_ 962 VCLEFT_btnWindowSwPackAutoUpRF "Left body controller: btn window sw pack auto up RF";
CM_ SG_ 962 VCLEFT_btnWindowSwPackDownRF "Left body controller: btn window sw pack down RF";
CM_ SG_ 962 VCLEFT_btnWindowSwPackAutoDownRF "Left body controller: btn window sw pack auto down RF";
CM_ SG_ 962 VCLEFT_btnWindowSwPackUpRR "Left body controller: btn window sw pack up RR";
CM_ SG_ 962 VCLEFT_btnWindowSwPackAutoUpRR "Left body controller: btn window sw pack auto up RR";
CM_ SG_ 962 VCLEFT_btnWindowSwPackDownRR "Left body controller: btn window sw pack down RR";
CM_ SG_ 962 VCLEFT_btnWindowSwPackAutoDownRR "Left body controller: btn window sw pack auto down RR";
CM_ SG_ 962 VCLEFT_frontBuckleSwitch "Left body controller: front buckle switch; raw 0 = signal not available (SNA)";
CM_ SG_ 962 VCLEFT_frontOccupancySwitch "Front left seat occupancy status; raw 0 = signal not available (SNA)";
CM_ SG_ 962 VCLEFT_rearLeftBuckleSwitch "Left body controller: rear left buckle switch; raw 0 = signal not available (SNA)";
CM_ SG_ 962 VCLEFT_rearCenterOccupancySwitch "Left body controller: rear center occupancy switch; raw 0 = signal not available (SNA)";
CM_ SG_ 962 VCLEFT_rearLeftOccupancySwitch "Left body controller: rear left occupancy switch; raw 0 = signal not available (SNA)";
CM_ SG_ 962 VCLEFT_rearRightOccupancySwitch "Left body controller: rear right occupancy switch; raw 0 = signal not available (SNA)";
CM_ SG_ 962 VCLEFT_brakePressed "Status of the brake pedal";
CM_ SG_ 962 VCLEFT_rearHVACButtonPressed "Left body controller: rear HVAC button pressed";
CM_ SG_ 962 VCLEFT_rearCenterBuckleSwitch "Left body controller: rear center buckle switch; raw 0 = signal not available (SNA)";
CM_ SG_ 962 VCLEFT_isAlcoholInterlockSet "Reports if the alcohol interlock is set.";
CM_ SG_ 962 VCLEFT_swcLeftTiltRight "Left body controller: swc left tilt right; raw 0 = signal not available (SNA)";
CM_ SG_ 962 VCLEFT_swcLeftPressed "Left body controller: swc left pressed; raw 0 = signal not available (SNA)";
CM_ SG_ 962 VCLEFT_swcRightTiltLeft "Left body controller: swc right tilt left; raw 0 = signal not available (SNA)";
CM_ SG_ 962 VCLEFT_swcRightTiltRight "Left body controller: swc right tilt right; raw 0 = signal not available (SNA)";
CM_ SG_ 962 VCLEFT_swcRightPressed "Left body controller: swc right pressed; raw 0 = signal not available (SNA)";
CM_ SG_ 962 VCLEFT_swcLeftTiltLeft "Left body controller: swc left tilt left; raw 0 = signal not available (SNA)";
CM_ SG_ 962 VCLEFT_swcLeftScrollTicks "Left body controller: swc left scroll ticks";
CM_ SG_ 962 VCLEFT_swcWiperButtonState "Left body controller: swc wiper button state";
CM_ SG_ 962 VCLEFT_swcRightScrollTicks "Encoder value for right steering wheel switch scroll";
CM_ SG_ 962 VCLEFT_swcTurnSignalLeftButtonSt "Left body controller: swc turn signal left button state";
CM_ SG_ 962 VCLEFT_btnWindowUpLR "Left body controller: btn window up LR";
CM_ SG_ 962 VCLEFT_btnWindowAutoUpLR "Left body controller: btn window auto up LR";
CM_ SG_ 962 VCLEFT_btnWindowDownLR "Left body controller: btn window down LR";
CM_ SG_ 962 VCLEFT_btnWindowAutoDownLR "Left body controller: btn window auto down LR";
CM_ SG_ 962 VCLEFT_2RowSeatLeftFoldFlatSwitc "Second row seat left fold flat switch";
CM_ SG_ 962 VCLEFT_2RowSeatRightFoldFlatSwit "Second row seat right fold flat switch";
CM_ SG_ 962 VCLEFT_2RowSeatBothFoldFlatSwitc "Second row seat both fold flat switch";
CM_ SG_ 962 VCLEFT_swcLeftDoublePress "Left body controller: swc left double press";
CM_ SG_ 962 VCLEFT_swcRightDoublePress "Left body controller: swc right double press";
CM_ SG_ 962 VCLEFT_swcTurnSignalRightButtonS "Left body controller: swc turn signal right button state";
CM_ SG_ 962 VCLEFT_swcHighBeamButtonState "Left body controller: swc high beam button state";
CM_ SG_ 962 VCLEFT_swcVoiceControlPress "Left body controller: swc voice control press; raw 0 = signal not available (SNA)";
CM_ SG_ 962 VCLEFT_swcCameraButtonState "Left body controller: swc camera button state";
CM_ SG_ 962 VCLEFT_swcRightPressedQF "Quality of steering wheel right scroll wheel button signal";
CM_ SG_ 962 VCLEFT_2RowSeatReclineSwitchpack "State of the left second row powered recline adjustment switchpack";
CM_ SG_ 962 VCLEFT_3RowLeftBuckleSwitch "Report status of 3rd row left seatbelt buckle; raw 0 = signal not available (SNA)";
CM_ SG_ 962 VCLEFT_frontSeatThighSupportExte "Status of the switch used to extend front seat thigh support.; raw 0 = signal not available (SNA)";
CM_ SG_ 962 VCLEFT_frontSeatThighSupportRetr "Status of the switch used to retract front seat thigh support.; raw 0 = signal not available (SNA)";
CM_ SG_ 962 VCLEFT_frontSeatResistiveOccupan "Front left seat occupancy status; raw 0 = signal not available (SNA)";
CM_ BO_ 1114 "Right body controller message: AP hvac state10 hz";
CM_ SG_ 1114 VCRIGHT_AP_hvacState10HzIndex "Right body controller: AP hvac state10 hz index";
CM_ SG_ 1114 VCRIGHT_AP_autoDefogAvailable "Right body controller: AP auto defog available";
CM_ SG_ 1114 VCRIGHT_AP_hvacFlashFoggingDetec "Right body controller: AP hvac flash fogging detected";
CM_ SG_ 1114 VCRIGHT_AP_hvacModelInitStatus "Right body controller: AP hvac model init status";
CM_ SG_ 1114 VCRIGHT_AP_cabinTempWindshield "Right body controller: AP cabin temp windshield; raw 255 = signal not available (SNA)";
CM_ SG_ 1114 VCRIGHT_AP_cabinTempSideGlassRig "Right body controller: AP cabin temp side glass right; raw 255 = signal not available (SNA)";
CM_ SG_ 1114 VCRIGHT_AP_cabinTempSideGlassLef "Right body controller: AP cabin temp side glass left; raw 255 = signal not available (SNA)";
CM_ SG_ 1114 VCRIGHT_AP_hvacRecircDoorPercent "Right body controller: AP hvac recirc door percent";
CM_ SG_ 1114 VCRIGHT_AP_hvacAirDistributionMo "Right body controller: AP hvac air distribution mode";
CM_ SG_ 1114 VCRIGHT_AP_hvacEstimateWindshiel "Right body controller: AP hvac estimate windshield RH";
CM_ SG_ 1114 VCRIGHT_AP_hvacMassflowTarget "Right body controller: AP hvac massflow target";
CM_ SG_ 1114 VCRIGHT_AP_tempDuctDefrost "Right body controller: AP temp duct defrost; raw 255 = signal not available (SNA)";
CM_ SG_ 1114 VCRIGHT_AP_cameraTurnOnTime "Reports the time duration requested to run the Autopilot (AP) cameras for defogging purposes.; raw 511 = signal not available (SNA)";
CM_ SG_ 1114 VCRIGHT_AP_cameraDefogType "Right body controller: AP camera defog type";
CM_ SG_ 1114 VCRIGHT_ah_hvacFaultSurvivabilit "Right body controller: ah hvac fault survivability time; raw 31 = signal not available (SNA)";
CM_ SG_ 1114 VCRIGHT_ah_defoggingTimeNeeded "Right body controller: ah defogging time needed; raw 31 = signal not available (SNA)";
CM_ SG_ 1114 VCRIGHT_AP_cameraFanDutyRequest "Right body controller: AP camera fan duty request; raw 127 = signal not available (SNA)";
CM_ SG_ 1114 VCRIGHT_ah_defogSystemState "Right body controller: ah defog system state; raw 7 = signal not available (SNA)";
CM_ SG_ 1114 VCRIGHT_AP_turnForwardCameraHeat "Right body controller: AP turn forward camera heater on reason";
CM_ SG_ 1114 VCRIGHT_AP_turnCameraFanOffReaso "Reports the reason for requesting the triple camera fan to turn off.";
CM_ SG_ 1114 VCRIGHT_AP_forwardCameraIntegrat "Request to run forward camera heating.";
CM_ SG_ 1114 VCRIGHT_AP_solarFluxOnRightWindo "Right body controller: AP solar flux on right window; raw 255 = signal not available (SNA)";
CM_ SG_ 1114 VCRIGHT_AP_solarFluxOnLeftWindow "Right body controller: AP solar flux on left window; raw 255 = signal not available (SNA)";
CM_ BO_ 1795 "Right body controller message: debug thermal10 hz";
CM_ SG_ 1795 VCRIGHT_debugThermal10HzIndex "Right body controller: debug thermal10 hz index";
CM_ SG_ 1795 VCRIGHT_hvacPanelFloorSplitRow1 "Right body controller: hvac panel floor split row1";
CM_ SG_ 1795 VCRIGHT_hvacDefrostPercent "Right body controller: hvac defrost percent";
CM_ SG_ 1795 VCRIGHT_hvacRow2Percent "Right body controller: hvac row2 percent";
CM_ SG_ 1795 VCRIGHT_hvacPanelFloorSplitRow2 "Right body controller: hvac panel floor split row2";
CM_ SG_ 1795 VCRIGHT_hvacFreshMassCounter "Right body controller: hvac fresh mass counter";
CM_ SG_ 1795 VCRIGHT_hvacRecircMassCounter "Right body controller: hvac recirc mass counter";
CM_ SG_ 1795 VCRIGHT_setTempAdjustmentLeft "Right body controller: set temp adjustment left; raw 127 = signal not available (SNA)";
CM_ SG_ 1795 VCRIGHT_setTempAdjustmentRight "Right body controller: set temp adjustment right; raw 127 = signal not available (SNA)";
CM_ SG_ 1795 VCRIGHT_hvacLHVaneVelocity "Right body controller: hvac LH vane velocity";
CM_ SG_ 1795 VCRIGHT_hvacRHVaneVelocity "Right body controller: hvac RH vane velocity";
CM_ SG_ 1795 VCRIGHT_hvacVehicleSpeed "Right body controller: hvac vehicle speed";
CM_ SG_ 1795 VCRIGHT_hvacMassflowCompensated "Right body controller: hvac massflow compensated";
CM_ SG_ 1795 VCRIGHT_PTCcenterPowerLeft "Right body controller: PT ccenter power left; raw 63 = signal not available (SNA)";
CM_ SG_ 1795 VCRIGHT_PTCouterPowerLeft "Right body controller: PT couter power left; raw 63 = signal not available (SNA)";
CM_ SG_ 1795 VCRIGHT_PTCinnerPowerLeft "Right body controller: PT cinner power left; raw 63 = signal not available (SNA)";
CM_ SG_ 1795 VCRIGHT_PTCcenterPowerRight "Right body controller: PT ccenter power right; raw 63 = signal not available (SNA)";
CM_ SG_ 1795 VCRIGHT_PTCouterPowerRight "Right body controller: PT couter power right; raw 63 = signal not available (SNA)";
CM_ SG_ 1795 VCRIGHT_PTCinnerPowerRight "Right body controller: PT cinner power right; raw 63 = signal not available (SNA)";
CM_ SG_ 1795 VCRIGHT_PTCcenterStoneTempLeft "Right body controller: PT ccenter stone temp left; raw 255 = signal not available (SNA)";
CM_ SG_ 1795 VCRIGHT_PTCcenterStoneTempRight "Right body controller: PT ccenter stone temp right; raw 255 = signal not available (SNA)";
CM_ SG_ 1795 VCRIGHT_PTCinnerStoneTempLeft "Right body controller: PT cinner stone temp left; raw 255 = signal not available (SNA)";
CM_ SG_ 1795 VCRIGHT_PTCinnerStoneTempRight "Right body controller: PT cinner stone temp right; raw 255 = signal not available (SNA)";
CM_ SG_ 1795 VCRIGHT_PTCouterStoneTempLeft "Right body controller: PT couter stone temp left; raw 255 = signal not available (SNA)";
CM_ SG_ 1795 VCRIGHT_PTCouterRodTempLeft "Right body controller: PT couter rod temp left; raw 255 = signal not available (SNA)";
CM_ SG_ 1795 VCRIGHT_PTCouterAirTempLeft "Right body controller: PT couter air temp left; raw 255 = signal not available (SNA)";
CM_ SG_ 1795 VCRIGHT_PTCcenterRodTempLeft "Right body controller: PT ccenter rod temp left; raw 255 = signal not available (SNA)";
CM_ SG_ 1795 VCRIGHT_PTCinnerRodTempLeft "Right body controller: PT cinner rod temp left; raw 255 = signal not available (SNA)";
CM_ SG_ 1795 VCRIGHT_PTCcenterAirTempLeft "Right body controller: PT ccenter air temp left; raw 255 = signal not available (SNA)";
CM_ SG_ 1795 VCRIGHT_PTCinnerAirTempLeft "Right body controller: PT cinner air temp left; raw 255 = signal not available (SNA)";
CM_ SG_ 1795 VCRIGHT_PTCouterStoneTempRight "Right body controller: PT couter stone temp right; raw 255 = signal not available (SNA)";
CM_ SG_ 1795 VCRIGHT_PTCouterRodTempRight "Right body controller: PT couter rod temp right; raw 255 = signal not available (SNA)";
CM_ SG_ 1795 VCRIGHT_PTCouterAirTempRight "Right body controller: PT couter air temp right; raw 255 = signal not available (SNA)";
CM_ SG_ 1795 VCRIGHT_PTCcenterRodTempRight "Right body controller: PT ccenter rod temp right; raw 255 = signal not available (SNA)";
CM_ SG_ 1795 VCRIGHT_PTCinnerRodTempRight "Right body controller: PT cinner rod temp right; raw 255 = signal not available (SNA)";
CM_ SG_ 1795 VCRIGHT_PTCcenterAirTempRight "Right body controller: PT ccenter air temp right; raw 255 = signal not available (SNA)";
CM_ SG_ 1795 VCRIGHT_PTCinnerAirTempRight "Right body controller: PT cinner air temp right; raw 255 = signal not available (SNA)";
CM_ BO_ 291 "Right body controller message: door status2";
CM_ SG_ 291 VCRIGHT_doorStatus2Index "Right body controller: door status2 index";
CM_ SG_ 291 VCRIGHT_frontLatchRelDuty "Front left door latch motor duty cycle.";
CM_ SG_ 291 VCRIGHT_BPillarCameraHeaterState "Indicates the state of the right b-pillar camera heater; raw 0 = signal not available (SNA)";
CM_ SG_ 291 VCRIGHT_doorLatchAjarSwitchVolta "Door latch switch voltage feeding switch logic";
CM_ SG_ 291 VCRIGHT_doorLatchAjarSwitch_0001 "Door latch switch voltage feeding switch logic";
CM_ SG_ 291 VCRIGHT_BPillarCameraHeaterCurre "Current drawn by the right b-pillar camera heater; raw 63 = signal not available (SNA)";
CM_ SG_ 291 VCRIGHT_mirrorTiltXOffset "Communicates post calibration position offset of right side view mirror tilt horizontal position";
CM_ SG_ 291 VCRIGHT_mirrorTiltYOffset "Communicates post calibration position offset of right side view mirror tilt vertical position";
CM_ BO_ 739 "Right body controller message: seat status2";
CM_ SG_ 739 VCRIGHT_seatStatus2Index "Right body controller: seat status2 index";
CM_ SG_ 739 VCRIGHT_frontSeatHeatCurrent "Right body controller: front seat heat current; raw 12 = signal not available (SNA)";
CM_ SG_ 739 VCRIGHT_frontSeatHeatDuty "Right body controller: front seat heat duty";
CM_ SG_ 739 VCRIGHT_frontSeatHeatTmp "Right body controller: front seat heat tmp";
CM_ SG_ 739 VCRIGHT_frontSeatHeatTmpTarget "Target temperature for front right seat heater";
CM_ SG_ 739 VCRIGHT_frontSeatHeatInhibited "Front right seat heater duty cycle";
CM_ SG_ 739 VCRIGHT_frontSeatHeatPowered "Right body controller: front seat heat powered";
CM_ SG_ 739 VC_AH_1RowRightSeatHeatVentHealt "Right body controller: AH 1 row right seat heat vent health";
CM_ SG_ 739 VCRIGHT_rearLSeatHeatCurrent "Current drawn by rear center seat heater";
CM_ SG_ 739 VCRIGHT_rearLSeatHeatDuty "Right body controller: rear l seat heat duty";
CM_ SG_ 739 VCRIGHT_rearLSeatHeatTmp "Right body controller: rear l seat heat tmp";
CM_ SG_ 739 VCRIGHT_rearLSeatHeatTmpTarget "Right body controller: rear l seat heat tmp target";
CM_ SG_ 739 VCRIGHT_rearLSeatHeatInhibited "Right body controller: rear l seat heat inhibited";
CM_ SG_ 739 VCRIGHT_rearLSeatHeatPowered "Right body controller: rear l seat heat powered";
CM_ SG_ 739 VCRIGHT_rearCSeatHeatCurrent "Right body controller: rear c seat heat current";
CM_ SG_ 739 VCRIGHT_rearCSeatHeatDuty "Right body controller: rear c seat heat duty";
CM_ SG_ 739 VCRIGHT_rearCSeatHeatTmp "Right body controller: rear c seat heat tmp";
CM_ SG_ 739 VCRIGHT_rearCSeatHeatTmpTarget "Right body controller: rear c seat heat tmp target";
CM_ SG_ 739 VCRIGHT_rearCSeatHeatInhibited "Right body controller: rear c seat heat inhibited";
CM_ SG_ 739 VCRIGHT_rearCSeatHeatPowered "Right body controller: rear c seat heat powered";
CM_ SG_ 739 VCRIGHT_rearRSeatHeatCurrent "Right body controller: rear r seat heat current";
CM_ SG_ 739 VCRIGHT_rearRSeatHeatDuty "Right body controller: rear r seat heat duty";
CM_ SG_ 739 VCRIGHT_rearRSeatHeatTmp "Right body controller: rear r seat heat tmp";
CM_ SG_ 739 VCRIGHT_rearRSeatHeatTmpTarget "Right body controller: rear r seat heat tmp target";
CM_ SG_ 739 VCRIGHT_rearRSeatHeatInhibited "Right body controller: rear r seat heat inhibited";
CM_ SG_ 739 VCRIGHT_rearRSeatHeatPowered "Right body controller: rear r seat heat powered";
CM_ SG_ 739 VCRIGHT_2RowSeatReclineState "Reports the active state of the 2nd row seat recliner; raw 15 = signal not available (SNA)";
CM_ SG_ 739 VCRIGHT_2RowSeatReclineDuty "Reports the 2nd row seat recliner motor duty cycle";
CM_ SG_ 739 VCRIGHT_2RowSeatReclineCurrent "Reports the 2nd row seat recliner motor current";
CM_ SG_ 739 VCRIGHT_2RowSeatReclineCalibrate "Reports calibration status of the 2nd row seat recliner";
CM_ SG_ 739 VCRIGHT_2RowSeatReclinePositionR "Reports the 2nd row seat recliner raw encoder count";
CM_ SG_ 739 VCRIGHT_2RowSeatReclineAngle "Reports the position of the 2nd row seat recliner in degrees";
CM_ SG_ 739 VCRIGHT_2RowSeatReclineAbsPosSwi "Reports the status of 2nd row seat recline absolute position (comfort zone) switch; raw 0 = signal not available (SNA)";
CM_ SG_ 739 VCRIGHT_2RowSeatReclinePositionS "Reports the active position state of the 2nd row seat recliner; raw 4 = signal not available (SNA)";
CM_ SG_ 739 VCRIGHT_2RowSeatReclineAdjustmen "Indicates whether adjustment requests are currently permitted for the rear seat recliner";
CM_ SG_ 739 VCRIGHT_2RowSeatReclineFoldAllow "Indicates whether auto-fold requests are currently permitted for the rear seat recliner";
CM_ SG_ 739 VCRIGHT_2RowSeatReclineUnfoldAll "Indicates whether auto-unfold requests are currently permitted for the rear seat recliner";
CM_ SG_ 739 VCRIGHT_2RowSeatReclineNextToggl "Right body controller: 2 row seat recline next toggle direction; raw 2 = signal not available (SNA)";
CM_ SG_ 739 VCRIGHT_2RowSeatReclineChoreoBlo "Right body controller: 2 row seat recline choreo blocked by occupancy";
CM_ SG_ 739 VCRIGHT_2RowSeat1RClashAvoidance "Right body controller: 2 row seat1 r clash avoidance blocked reason";
CM_ SG_ 739 VCRIGHT_2RowSeat1RClashAvoi_0001 "Right body controller: 2 row seat1 r clash avoidance state";
CM_ SG_ 739 VCRIGHT_2RowSeatReclineAbsP_0001 "Right body controller: 2 row seat recline abs pos switch trans point";
CM_ SG_ 739 VC_AH_2RowRightSeatMovementHealt "Right body controller: AH 2 row right seat movement health";
CM_ SG_ 739 VCRIGHT_3RowSeatReclineState "Reports active state of the rear seat recliner; raw 15 = signal not available (SNA)";
CM_ SG_ 739 VCRIGHT_3RowSeatReclineDuty "Reports the third row seat recliner motor duty cycle";
CM_ SG_ 739 VCRIGHT_3RowSeatReclineCurrent "Reports the third row seat recliner motor current";
CM_ SG_ 739 VCRIGHT_3RowSeatReclineCalibrate "Reports calibration status of the third row seat recliner";
CM_ SG_ 739 VCRIGHT_3RowSeatReclinePositionR "Reports the third row seat recliner raw encoder count";
CM_ SG_ 739 VCRIGHT_3RowSeatReclineAngle "Reports position of the 3rd row seat recliner in degrees";
CM_ SG_ 739 VCRIGHT_3RowSeatReclineNextToggl "Right body controller: 3 row seat recline next toggle direction; raw 2 = signal not available (SNA)";
CM_ SG_ 739 VCRIGHT_3RRightSeatHeatCurrent "Current drawn by 3rd row right seat heater";
CM_ SG_ 739 VCRIGHT_3RRightSeatHeatDuty "3rd row right seat heater duty cycle";
CM_ SG_ 739 VCRIGHT_3RRightSeatHeatTmp "Temperature of 3rd row right seat heater as reported by NTC";
CM_ SG_ 739 VCRIGHT_3RRightSeatHeatTmpTarget "Target temperature for 3rd row right seat heater";
CM_ SG_ 739 VCRIGHT_3RRightSeatHeatInhibited "Status describing whether 3rd row right seat heat is inhibited";
CM_ SG_ 739 VCRIGHT_3RowSeatReclinePositionS "Reports active position state of the rear seat recliner; raw 4 = signal not available (SNA)";
CM_ SG_ 739 VCRIGHT_3RowSeatReclineAdjustmen "Indicates whether adjustment requests are currently permitted for the rear seat recliner";
CM_ SG_ 739 VCRIGHT_3RowSeatReclineFoldAllow "Indicates whether auto-fold requests are currently permitted for the rear seat recliner";
CM_ SG_ 739 VCRIGHT_3RowSeatReclineUnfoldAll "Indicates whether auto-unfold requests are currently permitted for the rear seat recliner";
CM_ SG_ 739 VCRIGHT_3RowSeatReclineChoreoBlo "Right body controller: 3 row seat recline choreo blocked by occupancy";
CM_ SG_ 739 VCRIGHT_3RowSeatReclineAbsPosSwi "Reports status of 2R seat recline absolute position (comfort zone) switch; raw 0 = signal not available (SNA)";
CM_ BO_ 835 "Right body controller message: status";
CM_ SG_ 835 VCRIGHT_autonomyBehaviorStatus "Right body controller: autonomy behavior status";
CM_ SG_ 835 VCRIGHT_LVBatteryTypeDBG "Right body controller: LV battery type DBG";
CM_ SG_ 835 VCRIGHT_rearDefrostState "Right body controller: rear defrost state; raw 0 = signal not available (SNA)";
CM_ SG_ 835 VCRIGHT_mirrorHeatState "Right body controller: mirror heat state; raw 0 = signal not available (SNA)";
CM_ SG_ 835 VCRIGHT_OTAState "Right body controller: OTA state";
CM_ SG_ 835 VCRIGHT_5AVoltage "Right body controller: 5 a voltage";
CM_ SG_ 835 VCRIGHT_vbatProt "Input voltage monitor to controller";
CM_ SG_ 835 VCRIGHT_rationalityAggregateCurr "Right body controller: rationality aggregate current";
CM_ SG_ 835 VCRIGHT_eFuseMgmtVoltageMonitor "Right body controller: e fuse mgmt voltage monitor";
CM_ SG_ 835 VCRIGHT_isSteeringWheelHeaterReq "Right body controller: is steering wheel heater req";
CM_ SG_ 835 VCRIGHT_steeringWheelHeaterDCTgt "Right body controller: steering wheel heater DC tgt; raw 127 = signal not available (SNA)";
CM_ BO_ 899 "Right body controller message: ths status";
CM_ SG_ 899 VCRIGHT_thsActive "Right body controller: ths active";
CM_ SG_ 899 VCRIGHT_thsTemperature "Tesla HVAC sensor temperature; raw 255 = signal not available (SNA)";
CM_ SG_ 899 VCRIGHT_thsState "Right body controller: ths state";
CM_ SG_ 899 VCRIGHT_thsLINCurrentSchedule "Right body controller: ths LIN current schedule";
CM_ SG_ 899 VCRIGHT_thsDetected "Tesla HVAC sensor connection is detected";
CM_ SG_ 899 VCRIGHT_thsHumidity "Tesla HVAC sensor humidity; raw 127 = signal not available (SNA)";
CM_ SG_ 899 VCRIGHT_estimatedVehicleSituatio "Right body controller: estimated vehicle situation";
CM_ SG_ 899 VCRIGHT_thsSolarLoadInfrared "Solar power hitting the vehicle in the infrared spectrum.; raw 1023 = signal not available (SNA)";
CM_ SG_ 899 VCRIGHT_thsSolarLoadVisible "Solar power hitting the vehicle in the visible spectrum.; raw 1023 = signal not available (SNA)";
CM_ SG_ 899 VCRIGHT_estimatedThsSolarLoad "Right body controller: estimated ths solar load; raw 1023 = signal not available (SNA)";
CM_ SG_ 899 VCRIGHT_hvacFastLoggingEnabled "Right body controller: hvac fast logging enabled";
CM_ BO_ 1066 "Vehicle security controller message: TPMS connection data";
CM_ SG_ 1066 VCSEC_TPMSSensorState0 "Indicates the sensors pairing/connectivity status";
CM_ SG_ 1066 VCSEC_TPMSRSSI0 "Received Signal Strength Index reported by sensor.";
CM_ SG_ 1066 VCSEC_TPMSConnectionTypeCurrent0 "Vehicle security controller: TPMS connection type current0";
CM_ SG_ 1066 VCSEC_TPMSConnectionTypeDesired0 "Vehicle security controller: TPMS connection type desired0";
CM_ SG_ 1066 VCSEC_TPMSSensorState1 "Indicates the sensors pairing/connectivity status";
CM_ SG_ 1066 VCSEC_TPMSRSSI1 "Received Signal Strength Index reported by sensor.";
CM_ SG_ 1066 VCSEC_TPMSConnectionTypeCurrent1 "Vehicle security controller: TPMS connection type current1";
CM_ SG_ 1066 VCSEC_TPMSConnectionTypeDesired1 "Vehicle security controller: TPMS connection type desired1";
CM_ SG_ 1066 VCSEC_TPMSSensorState2 "Indicates the sensors pairing/connectivity status";
CM_ SG_ 1066 VCSEC_TPMSRSSI2 "Received Signal Strength Index reported by sensor.";
CM_ SG_ 1066 VCSEC_TPMSConnectionTypeCurrent2 "Vehicle security controller: TPMS connection type current2";
CM_ SG_ 1066 VCSEC_TPMSConnectionTypeDesired2 "Vehicle security controller: TPMS connection type desired2";
CM_ SG_ 1066 VCSEC_TPMSSensorState3 "Indicates the sensors pairing/connectivity status";
CM_ SG_ 1066 VCSEC_TPMSRSSI3 "Received Signal Strength Index reported by sensor.";
CM_ SG_ 1066 VCSEC_TPMSConnectionTypeCurrent3 "Vehicle security controller: TPMS connection type current3";
CM_ SG_ 1066 VCSEC_TPMSConnectionTypeDesired3 "Vehicle security controller: TPMS connection type desired3";
CM_ SG_ 1066 VCSEC_TPMSSensorPresence0 "Indicates the sensors detection status";
CM_ SG_ 1066 VCSEC_TPMSSensorPresence1 "Indicates the sensors detection status";
CM_ SG_ 1066 VCSEC_TPMSSensorPresence2 "Indicates the sensors detection status";
CM_ SG_ 1066 VCSEC_TPMSSensorPresence3 "Indicates the sensors detection status";
CM_ BO_ 1824 "Vehicle security controller message: ecu config";
CM_ SG_ 1824 VCSEC_ECUConfigCRC32 "Vehicle security controller: ECU config CRC32";
CM_ SG_ 1824 VCSEC_autoWriteConfig "Vehicle security controller: auto write config";
CM_ SG_ 1824 VCSEC_requestForConfig "Vehicle security controller: request for config";
CM_ BO_ 281 "Vehicle security controller message: requests2";
CM_ SG_ 281 VCSEC_activeImmobilizerAuthLevel "The level of auth VCSEC will respond with when the Drive Inverter asks for auth";
CM_ SG_ 281 VCSEC_smartTrunkLightRequest "Request to signal indication lights for the smart trunk feature";
CM_ SG_ 281 VCSEC_smartTrunkSoundRequest "Vehicle security controller: smart trunk sound request";
CM_ SG_ 281 VCSEC_hvacRunScreenProtectOnly "Vehicle security controller: hvac run screen protect only";
CM_ SG_ 281 VCSEC_chargeHandleRequestModel "Vehicle security controller: charge handle request model";
CM_ SG_ 281 VCSEC_recoveryModeRequested "Vehicle security controller: recovery mode requested";
CM_ SG_ 281 VCSEC_infotainmentResetRequested "Vehicle security controller: infotainment reset requested";
CM_ SG_ 281 VCSEC_mobileToAPRequest "Vehicle security controller: mobile to AP request";
CM_ SG_ 281 VCSEC_riderKeyPresent "Vehicle security controller: rider key present";
BA_DEF_ BO_ "GenMsgCycleTime" INT 0 3600000;
BA_DEF_ BO_ "GenMsgSendType" ENUM "Cyclic","NotUsed","NotUsed","NotUsed","NotUsed","NotUsed","NotUsed","IfActive","NoMsgSendType","NotUsed";
BA_DEF_ BO_ "VFrameFormat" ENUM "StandardCAN","ExtendedCAN","reserved","J1939PG","reserved","reserved","reserved","reserved","reserved","reserved","reserved","reserved","reserved","reserved","StandardCAN_FD","ExtendedCAN_FD";
BA_DEF_ BO_ "CANFD_BRS" ENUM "0","1";
BA_DEF_ SG_ "GenSigSNA" STRING;
BA_DEF_ SG_ "SystemSignalLongSymbol" STRING;
BA_DEF_ SG_ "Confidence" ENUM "validated","plausible","layout-only","contradicted";
BA_DEF_DEF_ "GenMsgCycleTime" 0;
BA_DEF_DEF_ "GenMsgSendType" "NoMsgSendType";
BA_DEF_DEF_ "VFrameFormat" "StandardCAN";
BA_DEF_DEF_ "CANFD_BRS" "1";
BA_DEF_DEF_ "GenSigSNA" "";
BA_DEF_DEF_ "SystemSignalLongSymbol" "";
BA_DEF_DEF_ "Confidence" "layout-only";
BA_ "GenMsgCycleTime" BO_ 1353 10000;
BA_ "GenMsgSendType" BO_ 1353 0;
BA_ "GenMsgCycleTime" BO_ 1801 294;
BA_ "GenMsgSendType" BO_ 1801 0;
BA_ "GenMsgCycleTime" BO_ 957 1000;
BA_ "GenMsgSendType" BO_ 957 0;
BA_ "GenMsgCycleTime" BO_ 737 16;
BA_ "GenMsgSendType" BO_ 737 0;
BA_ "GenMsgCycleTime" BO_ 507 5000;
BA_ "GenMsgSendType" BO_ 507 0;
BA_ "GenMsgCycleTime" BO_ 292 500;
BA_ "GenMsgSendType" BO_ 292 0;
BA_ "GenMsgCycleTime" BO_ 1802 10000;
BA_ "GenMsgSendType" BO_ 1802 0;
BA_ "GenMsgCycleTime" BO_ 930 33;
BA_ "GenMsgSendType" BO_ 930 0;
BA_ "GenMsgCycleTime" BO_ 962 50;
BA_ "GenMsgSendType" BO_ 962 0;
BA_ "GenMsgCycleTime" BO_ 1114 50;
BA_ "GenMsgSendType" BO_ 1114 0;
BA_ "GenMsgCycleTime" BO_ 1795 10;
BA_ "GenMsgSendType" BO_ 1795 0;
BA_ "GenMsgCycleTime" BO_ 291 100;
BA_ "GenMsgSendType" BO_ 291 0;
BA_ "GenMsgCycleTime" BO_ 739 200;
BA_ "GenMsgSendType" BO_ 739 0;
BA_ "GenMsgCycleTime" BO_ 835 100;
BA_ "GenMsgSendType" BO_ 835 0;
BA_ "GenMsgCycleTime" BO_ 899 100;
BA_ "GenMsgSendType" BO_ 899 0;
BA_ "GenMsgCycleTime" BO_ 1066 200;
BA_ "GenMsgSendType" BO_ 1066 0;
BA_ "GenMsgCycleTime" BO_ 1824 10000;
BA_ "GenMsgSendType" BO_ 1824 0;
BA_ "GenMsgCycleTime" BO_ 281 100;
BA_ "GenMsgSendType" BO_ 281 0;
BA_ "Confidence" SG_ 1353 VCFRONT_homelinkV2Response0 0;
BA_ "Confidence" SG_ 1353 VCFRONT_homelinkV2Response1 0;
BA_ "Confidence" SG_ 1353 VCFRONT_homelinkV2Response2 0;
BA_ "Confidence" SG_ 1353 VCFRONT_homelinkV2Response3 0;
BA_ "Confidence" SG_ 1353 VCFRONT_homelinkV2Response4 0;
BA_ "Confidence" SG_ 1353 VCFRONT_homelinkCommStatus 0;
BA_ "GenSigSNA" SG_ 1353 VCFRONT_homelinkCommStatus "0";
BA_ "Confidence" SG_ 1801 VCFRONT_logging0point1HzIndex 1;
BA_ "Confidence" SG_ 1801 VC_hcmlFactoryOfOrigin 0;
BA_ "Confidence" SG_ 1801 VC_hcmlHellaPartNumberStatus 0;
BA_ "Confidence" SG_ 1801 VC_hcmlHellaPartNumber 0;
BA_ "Confidence" SG_ 1801 VC_hcmlCurrentBinMappingType 0;
BA_ "Confidence" SG_ 1801 VC_hcmlCurrentBin0Value 0;
BA_ "GenSigSNA" SG_ 1801 VC_hcmlCurrentBin0Value "0";
BA_ "Confidence" SG_ 1801 VC_hcmlCurrentBin1Value 0;
BA_ "GenSigSNA" SG_ 1801 VC_hcmlCurrentBin1Value "0";
BA_ "Confidence" SG_ 1801 VC_hcmlCurrentBin2Value 0;
BA_ "GenSigSNA" SG_ 1801 VC_hcmlCurrentBin2Value "0";
BA_ "Confidence" SG_ 1801 VC_hcmlCurrentBin3Value 0;
BA_ "GenSigSNA" SG_ 1801 VC_hcmlCurrentBin3Value "0";
BA_ "Confidence" SG_ 1801 VC_hcmlCurrentBin4Value 0;
BA_ "GenSigSNA" SG_ 1801 VC_hcmlCurrentBin4Value "0";
BA_ "Confidence" SG_ 1801 VC_hcmlCurrentBin5Value 0;
BA_ "GenSigSNA" SG_ 1801 VC_hcmlCurrentBin5Value "0";
BA_ "Confidence" SG_ 1801 VC_hcmlRegionAndSide 0;
BA_ "GenSigSNA" SG_ 1801 VC_hcmlRegionAndSide "0";
BA_ "Confidence" SG_ 1801 VC_hcmrFactoryOfOrigin 0;
BA_ "Confidence" SG_ 1801 VC_hcmrHellaPartNumberStatus 0;
BA_ "Confidence" SG_ 1801 VC_hcmrHellaPartNumber 0;
BA_ "Confidence" SG_ 1801 VC_hcmrCurrentBinMappingType 0;
BA_ "Confidence" SG_ 1801 VC_hcmrCurrentBin0Value 0;
BA_ "GenSigSNA" SG_ 1801 VC_hcmrCurrentBin0Value "0";
BA_ "Confidence" SG_ 1801 VC_hcmrCurrentBin1Value 0;
BA_ "GenSigSNA" SG_ 1801 VC_hcmrCurrentBin1Value "0";
BA_ "Confidence" SG_ 1801 VC_hcmrCurrentBin2Value 0;
BA_ "GenSigSNA" SG_ 1801 VC_hcmrCurrentBin2Value "0";
BA_ "Confidence" SG_ 1801 VC_hcmrCurrentBin3Value 0;
BA_ "GenSigSNA" SG_ 1801 VC_hcmrCurrentBin3Value "0";
BA_ "Confidence" SG_ 1801 VC_hcmrCurrentBin4Value 0;
BA_ "GenSigSNA" SG_ 1801 VC_hcmrCurrentBin4Value "0";
BA_ "Confidence" SG_ 1801 VC_hcmrCurrentBin5Value 0;
BA_ "GenSigSNA" SG_ 1801 VC_hcmrCurrentBin5Value "0";
BA_ "Confidence" SG_ 1801 VC_hcmrRegionAndSide 0;
BA_ "GenSigSNA" SG_ 1801 VC_hcmrRegionAndSide "0";
BA_ "Confidence" SG_ 957 VCFRONT_energyLossIndex 1;
BA_ "Confidence" SG_ 957 VCFRONT_userEnergyLossSinceDrive 0;
BA_ "Confidence" SG_ 957 VCFRONT_preconditioningEner_0001 0;
BA_ "SystemSignalLongSymbol" SG_ 957 VCFRONT_preconditioningEner_0001 "VCFRONT_preconditioningEnergyLossSinceDrive";
BA_ "Confidence" SG_ 957 VCFRONT_cabinOverheatEnergy_0001 0;
BA_ "SystemSignalLongSymbol" SG_ 957 VCFRONT_cabinOverheatEnergy_0001 "VCFRONT_cabinOverheatEnergyLossSinceDrive";
BA_ "Confidence" SG_ 957 VCFRONT_mobileAppEnergyLoss_0001 0;
BA_ "SystemSignalLongSymbol" SG_ 957 VCFRONT_mobileAppEnergyLoss_0001 "VCFRONT_mobileAppEnergyLossSinceDrive";
BA_ "Confidence" SG_ 957 VCFRONT_summonStandbyEnergy_0001 0;
BA_ "SystemSignalLongSymbol" SG_ 957 VCFRONT_summonStandbyEnergy_0001 "VCFRONT_summonStandbyEnergyLossSinceDrive";
BA_ "Confidence" SG_ 957 VCFRONT_sentryModeEnergyLos_0001 0;
BA_ "SystemSignalLongSymbol" SG_ 957 VCFRONT_sentryModeEnergyLos_0001 "VCFRONT_sentryModeEnergyLossSinceDrive";
BA_ "Confidence" SG_ 957 VCFRONT_backgroundEnergyLos_0001 0;
BA_ "SystemSignalLongSymbol" SG_ 957 VCFRONT_backgroundEnergyLos_0001 "VCFRONT_backgroundEnergyLossSinceDrive";
BA_ "Confidence" SG_ 957 VCFRONT_evapDryingEnergyLos_0001 0;
BA_ "SystemSignalLongSymbol" SG_ 957 VCFRONT_evapDryingEnergyLos_0001 "VCFRONT_evapDryingEnergyLossSinceDrive";
BA_ "Confidence" SG_ 957 VCFRONT_userEnergyLossSinceCharg 0;
BA_ "SystemSignalLongSymbol" SG_ 957 VCFRONT_userEnergyLossSinceCharg "VCFRONT_userEnergyLossSinceCharge";
BA_ "Confidence" SG_ 957 VCFRONT_preconditioningEnergyLos 0;
BA_ "SystemSignalLongSymbol" SG_ 957 VCFRONT_preconditioningEnergyLos "VCFRONT_preconditioningEnergyLossSinceCharge";
BA_ "Confidence" SG_ 957 VCFRONT_cabinOverheatEnergyLossS 0;
BA_ "SystemSignalLongSymbol" SG_ 957 VCFRONT_cabinOverheatEnergyLossS "VCFRONT_cabinOverheatEnergyLossSinceCharge";
BA_ "Confidence" SG_ 957 VCFRONT_mobileAppEnergyLossSince 0;
BA_ "SystemSignalLongSymbol" SG_ 957 VCFRONT_mobileAppEnergyLossSince "VCFRONT_mobileAppEnergyLossSinceCharge";
BA_ "Confidence" SG_ 957 VCFRONT_summonStandbyEnergyLossS 0;
BA_ "SystemSignalLongSymbol" SG_ 957 VCFRONT_summonStandbyEnergyLossS "VCFRONT_summonStandbyEnergyLossSinceCharge";
BA_ "Confidence" SG_ 957 VCFRONT_sentryModeEnergyLossSinc 0;
BA_ "SystemSignalLongSymbol" SG_ 957 VCFRONT_sentryModeEnergyLossSinc "VCFRONT_sentryModeEnergyLossSinceCharge";
BA_ "Confidence" SG_ 957 VCFRONT_backgroundEnergyLossSinc 0;
BA_ "SystemSignalLongSymbol" SG_ 957 VCFRONT_backgroundEnergyLossSinc "VCFRONT_backgroundEnergyLossSinceCharge";
BA_ "Confidence" SG_ 957 VCFRONT_evapDryingEnergyLossSinc 0;
BA_ "SystemSignalLongSymbol" SG_ 957 VCFRONT_evapDryingEnergyLossSinc "VCFRONT_evapDryingEnergyLossSinceCharge";
BA_ "Confidence" SG_ 737 VCFRONT_statusIndex 1;
BA_ "Confidence" SG_ 737 VCFRONT_frunkLatchStatus 0;
BA_ "GenSigSNA" SG_ 737 VCFRONT_frunkLatchStatus "0";
BA_ "Confidence" SG_ 737 VCFRONT_wiperSpeed 0;
BA_ "GenSigSNA" SG_ 737 VCFRONT_wiperSpeed "0";
BA_ "Confidence" SG_ 737 VCFRONT_wiperPosition 0;
BA_ "GenSigSNA" SG_ 737 VCFRONT_wiperPosition "0";
BA_ "Confidence" SG_ 737 VCFRONT_wiperBlocked 0;
BA_ "Confidence" SG_ 737 VCFRONT_wiperState 0;
BA_ "GenSigSNA" SG_ 737 VCFRONT_wiperState "0";
BA_ "Confidence" SG_ 737 VCFRONT_crashDetectedType 0;
BA_ "Confidence" SG_ 737 VCFRONT_crashState 0;
BA_ "Confidence" SG_ 737 VCFRONT_crashUnlockOverrideSet 0;
BA_ "Confidence" SG_ 737 VCFRONT_washPumpState 0;
BA_ "GenSigSNA" SG_ 737 VCFRONT_washPumpState "1";
BA_ "Confidence" SG_ 737 VCFRONT_turnIndicatorControlType 0;
BA_ "Confidence" SG_ 737 VCFRONT_wiperHealth 0;
BA_ "Confidence" SG_ 737 VCFRONT_wiperLINHealth 0;
BA_ "Confidence" SG_ 737 VCFRONT_frunkLatchCurrent 0;
BA_ "Confidence" SG_ 737 VCFRONT_frunkInteriorRelSwitch 0;
BA_ "Confidence" SG_ 737 VCFRONT_anyClosureOpen 0;
BA_ "Confidence" SG_ 737 VCFRONT_anyDoorOpen 0;
BA_ "Confidence" SG_ 737 VCFRONT_hornOn 0;
BA_ "Confidence" SG_ 737 VCFRONT_radarHeaterState 0;
BA_ "GenSigSNA" SG_ 737 VCFRONT_radarHeaterState "0";
BA_ "Confidence" SG_ 737 VCFRONT_trunkExteriorWakeSwitch 0;
BA_ "Confidence" SG_ 737 VCFRONT_passengerBuckleStatus 0;
BA_ "Confidence" SG_ 737 VCFRONT_frunkLatchType 0;
BA_ "Confidence" SG_ 737 VCFRONT_headlampLeftFanStatus 0;
BA_ "Confidence" SG_ 737 VCFRONT_headlampRightFanStatus 0;
BA_ "Confidence" SG_ 737 VCFRONT_frunkAccessPost 0;
BA_ "Confidence" SG_ 737 VCFRONT_isActiveHeatingBattery 0;
BA_ "Confidence" SG_ 737 VCFRONT_iBoosterWakeLine 0;
BA_ "Confidence" SG_ 737 VCFRONT_epasWakeLine 0;
BA_ "Confidence" SG_ 737 VCFRONT_iBoosterStateDBG 0;
BA_ "Confidence" SG_ 737 VCFRONT_vehicleStatusDBG 0;
BA_ "GenSigSNA" SG_ 737 VCFRONT_vehicleStatusDBG "18";
BA_ "Confidence" SG_ 737 VCFRONT_timeSpentSleeping 0;
BA_ "Confidence" SG_ 737 VCFRONT_sleepCurrent 0;
BA_ "GenSigSNA" SG_ 737 VCFRONT_sleepCurrent "4095";
BA_ "Confidence" SG_ 737 VCFRONT_hibernationState 0;
BA_ "Confidence" SG_ 737 VCFRONT_wiperECUType 0;
BA_ "Confidence" SG_ 737 VCFRONT_wiperHeaterState 0;
BA_ "GenSigSNA" SG_ 737 VCFRONT_wiperHeaterState "0";
BA_ "Confidence" SG_ 737 VCFRONT_occupantCount 0;
BA_ "Confidence" SG_ 737 VCFRONT_closureEasterEggState 0;
BA_ "Confidence" SG_ 737 VCFRONT_espWakeLine 0;
BA_ "Confidence" SG_ 737 VCFRONT_allowEvapInLowAmbient 0;
BA_ "Confidence" SG_ 737 VCFRONT_potentialRadiatorSteam 0;
BA_ "Confidence" SG_ 737 VCFRONT_potentialRadiatorSteamUI 0;
BA_ "Confidence" SG_ 737 VCFRONT_hvacReqOffForFasterCharg 0;
BA_ "SystemSignalLongSymbol" SG_ 737 VCFRONT_hvacReqOffForFasterCharg "VCFRONT_hvacReqOffForFasterCharge";
BA_ "Confidence" SG_ 737 VCFRONT_limitedSplitTempDeltaEnf 0;
BA_ "SystemSignalLongSymbol" SG_ 737 VCFRONT_limitedSplitTempDeltaEnf "VCFRONT_limitedSplitTempDeltaEnforced";
BA_ "Confidence" SG_ 737 VCFRONT_batteryDischArbState 0;
BA_ "Confidence" SG_ 737 VCFRONT_maxEvapHeatRejection 0;
BA_ "Confidence" SG_ 737 VCFRONT_minEvapHeatRejection 0;
BA_ "Confidence" SG_ 737 VCFRONT_freezeEvapITerm 0;
BA_ "Confidence" SG_ 737 VCFRONT_isEvapOperationAllowed 0;
BA_ "Confidence" SG_ 737 VCFRONT_chillerDemandActive 0;
BA_ "Confidence" SG_ 737 VCFRONT_compPerfRecoveryLimited 0;
BA_ "Confidence" SG_ 737 VCFRONT_hvacModeNotAttainable 0;
BA_ "Confidence" SG_ 737 VCFRONT_hasLowRefrigerant 0;
BA_ "Confidence" SG_ 737 VCFRONT_isColdStartRunning 0;
BA_ "Confidence" SG_ 737 VCFRONT_isHeatPumpOilPurgeActive 0;
BA_ "Confidence" SG_ 737 VCFRONT_pressureRefrigSuction 0;
BA_ "GenSigSNA" SG_ 737 VCFRONT_pressureRefrigSuction "127";
BA_ "Confidence" SG_ 737 VCFRONT_pressureRefrigDischarge 0;
BA_ "GenSigSNA" SG_ 737 VCFRONT_pressureRefrigDischarge "511";
BA_ "Confidence" SG_ 737 VCFRONT_hvacPerfTestCommand 0;
BA_ "Confidence" SG_ 737 VCFRONT_coolantFillRoutineStatus 0;
BA_ "Confidence" SG_ 737 VCFRONT_refrigFillRoutineStatus 0;
BA_ "Confidence" SG_ 737 VCFRONT_isCOP1Running 0;
BA_ "Confidence" SG_ 737 VCFRONT_closeValvesRoutineStatus 0;
BA_ "Confidence" SG_ 737 VCFRONT_thermalPerfTestRunning 0;
BA_ "Confidence" SG_ 737 VCFRONT_extendedHvacPerfTestComm 0;
BA_ "SystemSignalLongSymbol" SG_ 737 VCFRONT_extendedHvacPerfTestComm "VCFRONT_extendedHvacPerfTestCommand";
BA_ "Confidence" SG_ 737 VCFRONT_5VARailStable 0;
BA_ "Confidence" SG_ 737 VCFRONT_5VBRailStable 0;
BA_ "Confidence" SG_ 737 VCFRONT_12VARailStable 0;
BA_ "Confidence" SG_ 737 VCFRONT_12VBRailStable 0;
BA_ "Confidence" SG_ 737 VCFRONT_railAState 0;
BA_ "Confidence" SG_ 737 VCFRONT_railBState 0;
BA_ "Confidence" SG_ 737 VCFRONT_ChargePumpVoltageStable 0;
BA_ "Confidence" SG_ 737 VCFRONT_PEResetLineState 0;
BA_ "Confidence" SG_ 737 VCFRONT_HSDInitCompleteU13 0;
BA_ "Confidence" SG_ 737 VCFRONT_HSDInitCompleteU16 0;
BA_ "Confidence" SG_ 737 VCFRONT_vbatMonitorVoltage 0;
BA_ "GenSigSNA" SG_ 737 VCFRONT_vbatMonitorVoltage "4095";
BA_ "Confidence" SG_ 737 VCFRONT_AS8510Voltage 0;
BA_ "GenSigSNA" SG_ 737 VCFRONT_AS8510Voltage "4095";
BA_ "Confidence" SG_ 737 VCFRONT_vbatProt 0;
BA_ "Confidence" SG_ 737 VCFRONT_logVerbosity 0;
BA_ "Confidence" SG_ 737 VCFRONT_cabinCoolingCapacityLimi 0;
BA_ "SystemSignalLongSymbol" SG_ 737 VCFRONT_cabinCoolingCapacityLimi "VCFRONT_cabinCoolingCapacityLimited";
BA_ "Confidence" SG_ 737 VCFRONT_cabinHeatingCapacityLimi 0;
BA_ "SystemSignalLongSymbol" SG_ 737 VCFRONT_cabinHeatingCapacityLimi "VCFRONT_cabinHeatingCapacityLimited";
BA_ "Confidence" SG_ 737 VCFRONT_compPowerSupportingHvac 0;
BA_ "Confidence" SG_ 737 VCFRONT_compPowerSupportingPT 0;
BA_ "Confidence" SG_ 737 VCFRONT_maxHeatingPowerLeftCC 0;
BA_ "Confidence" SG_ 737 VCFRONT_maxHeatingPowerRightCC 0;
BA_ "Confidence" SG_ 737 VCFRONT_activeLouverOpenPos 0;
BA_ "Confidence" SG_ 737 VCFRONT_activeLouverState 0;
BA_ "Confidence" SG_ 737 VCFRONT_windshieldCameraHeaterPo 0;
BA_ "GenSigSNA" SG_ 737 VCFRONT_windshieldCameraHeaterPo "63";
BA_ "SystemSignalLongSymbol" SG_ 737 VCFRONT_windshieldCameraHeaterPo "VCFRONT_windshieldCameraHeaterPower";
BA_ "Confidence" SG_ 507 VCLEFT_TLCStatusIndex 1;
BA_ "Confidence" SG_ 507 VCLEFT_TLCTemperature 0;
BA_ "GenSigSNA" SG_ 507 VCLEFT_TLCTemperature "128";
BA_ "Confidence" SG_ 507 VCLEFT_TLCLeftTurnVoltage 0;
BA_ "GenSigSNA" SG_ 507 VCLEFT_TLCLeftTurnVoltage "255";
BA_ "Confidence" SG_ 507 VCLEFT_TLCRightTurnVoltage 0;
BA_ "GenSigSNA" SG_ 507 VCLEFT_TLCRightTurnVoltage "255";
BA_ "Confidence" SG_ 507 VCLEFT_TLCState_LeftTurn 0;
BA_ "GenSigSNA" SG_ 507 VCLEFT_TLCState_LeftTurn "5";
BA_ "Confidence" SG_ 507 VCLEFT_TLCState_RightTurn 0;
BA_ "GenSigSNA" SG_ 507 VCLEFT_TLCState_RightTurn "5";
BA_ "Confidence" SG_ 507 VCLEFT_TLCState_Tail 0;
BA_ "GenSigSNA" SG_ 507 VCLEFT_TLCState_Tail "5";
BA_ "Confidence" SG_ 507 VCLEFT_TLCState_Stop 0;
BA_ "GenSigSNA" SG_ 507 VCLEFT_TLCState_Stop "5";
BA_ "Confidence" SG_ 507 VCLEFT_TLCState_Fog 0;
BA_ "GenSigSNA" SG_ 507 VCLEFT_TLCState_Fog "5";
BA_ "Confidence" SG_ 507 VCLEFT_TLCState_Reverse 0;
BA_ "GenSigSNA" SG_ 507 VCLEFT_TLCState_Reverse "5";
BA_ "Confidence" SG_ 292 VCLEFT_liftgateRequestAction 0;
BA_ "Confidence" SG_ 292 VCLEFT_liftgateRequestTargetDuty 0;
BA_ "Confidence" SG_ 292 VCLEFT_liftgateRequestTargetAngl 0;
BA_ "SystemSignalLongSymbol" SG_ 292 VCLEFT_liftgateRequestTargetAngl "VCLEFT_liftgateRequestTargetAngle";
BA_ "Confidence" SG_ 292 VCLEFT_liftgateRequestTargetPara 0;
BA_ "SystemSignalLongSymbol" SG_ 292 VCLEFT_liftgateRequestTargetPara "VCLEFT_liftgateRequestTargetParam";
BA_ "Confidence" SG_ 292 VCLEFT_adaptiveLiftgateControlMo 0;
BA_ "SystemSignalLongSymbol" SG_ 292 VCLEFT_adaptiveLiftgateControlMo "VCLEFT_adaptiveLiftgateControlModeActive";
BA_ "Confidence" SG_ 292 VCLEFT_liftgateReqObsDetMode 0;
BA_ "Confidence" SG_ 292 VCLEFT_liftgateReqResetStrutCoun 0;
BA_ "SystemSignalLongSymbol" SG_ 292 VCLEFT_liftgateReqResetStrutCoun "VCLEFT_liftgateReqResetStrutCount";
BA_ "Confidence" SG_ 292 VCLEFT_liftgateReqClearCal 0;
BA_ "Confidence" SG_ 292 VCLEFT_liftgateTargetTerminalSpe 0;
BA_ "SystemSignalLongSymbol" SG_ 292 VCLEFT_liftgateTargetTerminalSpe "VCLEFT_liftgateTargetTerminalSpeed";
BA_ "Confidence" SG_ 292 VCLEFT_liftgateReqCoastPercent 0;
BA_ "Confidence" SG_ 292 VCLEFT_liftgateReqDutyScale 0;
BA_ "Confidence" SG_ 1802 VCLEFT_logging0point1HzIndex 1;
BA_ "Confidence" SG_ 1802 VCLEFT_leftBrakeTailLightCurrent 0;
BA_ "GenSigSNA" SG_ 1802 VCLEFT_leftBrakeTailLightCurrent "511";
BA_ "Confidence" SG_ 1802 VCLEFT_leftBrakeTailLightCu_0001 0;
BA_ "GenSigSNA" SG_ 1802 VCLEFT_leftBrakeTailLightCu_0001 "0";
BA_ "SystemSignalLongSymbol" SG_ 1802 VCLEFT_leftBrakeTailLightCu_0001 "VCLEFT_leftBrakeTailLightCurrentSenseState";
BA_ "Confidence" SG_ 1802 VCLEFT_leftRearTurnLightCurrent 0;
BA_ "GenSigSNA" SG_ 1802 VCLEFT_leftRearTurnLightCurrent "511";
BA_ "Confidence" SG_ 1802 VCLEFT_leftRearTurnLightCurrentS 0;
BA_ "GenSigSNA" SG_ 1802 VCLEFT_leftRearTurnLightCurrentS "0";
BA_ "SystemSignalLongSymbol" SG_ 1802 VCLEFT_leftRearTurnLightCurrentS "VCLEFT_leftRearTurnLightCurrentSenseState";
BA_ "Confidence" SG_ 1802 VCLEFT_phoneTemperatureFL 0;
BA_ "GenSigSNA" SG_ 1802 VCLEFT_phoneTemperatureFL "128";
BA_ "Confidence" SG_ 1802 VCLEFT_phoneTemperatureFR 0;
BA_ "GenSigSNA" SG_ 1802 VCLEFT_phoneTemperatureFR "128";
BA_ "Confidence" SG_ 1802 VCLEFT_canAuthResyncDurationMs 0;
BA_ "Confidence" SG_ 930 VCLEFT_statusIndex 1;
BA_ "Confidence" SG_ 930 VCLEFT_securityControllerEnable 0;
BA_ "Confidence" SG_ 930 VCLEFT_securityControllerVoltage 0;
BA_ "Confidence" SG_ 930 VCLEFT_consoleDoorAssist 0;
BA_ "Confidence" SG_ 930 VCLEFT_OTAState 0;
BA_ "Confidence" SG_ 930 VCLEFT_5AVoltage 0;
BA_ "Confidence" SG_ 930 VCLEFT_vbatProt 0;
BA_ "Confidence" SG_ 930 VCLEFT_footwellLightCurrent 0;
BA_ "Confidence" SG_ 930 VCLEFT_swcInputVoltage 0;
BA_ "GenSigSNA" SG_ 930 VCLEFT_swcInputVoltage "255";
BA_ "Confidence" SG_ 930 VCLEFT_swcPCBATemperature 0;
BA_ "GenSigSNA" SG_ 930 VCLEFT_swcPCBATemperature "128";
BA_ "Confidence" SG_ 930 VCLEFT_obdEthernetActive 0;
BA_ "Confidence" SG_ 930 VCLEFT_rationalityAggregateCurre 0;
BA_ "SystemSignalLongSymbol" SG_ 930 VCLEFT_rationalityAggregateCurre "VCLEFT_rationalityAggregateCurrent";
BA_ "Confidence" SG_ 930 VCLEFT_LVBatteryTypeDBG 0;
BA_ "Confidence" SG_ 930 VCLEFT_DIeFuseFault 0;
BA_ "Confidence" SG_ 930 VCLEFT_eFuseMgmtVoltageMonitor 0;
BA_ "Confidence" SG_ 930 VCLEFT_trailerAuxCurrent 0;
BA_ "GenSigSNA" SG_ 930 VCLEFT_trailerAuxCurrent "4095";
BA_ "Confidence" SG_ 930 VCLEFT_swcHeatTmp 0;
BA_ "GenSigSNA" SG_ 930 VCLEFT_swcHeatTmp "1023";
BA_ "Confidence" SG_ 930 VCLEFT_swcHeatStatus 0;
BA_ "GenSigSNA" SG_ 930 VCLEFT_swcHeatStatus "0";
BA_ "Confidence" SG_ 930 VCLEFT_swcHeatInhibited 0;
BA_ "Confidence" SG_ 930 VCLEFT_obdDeviceDetected 0;
BA_ "Confidence" SG_ 930 VCLEFT_pcbaTemperature 0;
BA_ "Confidence" SG_ 930 VCLEFT_swcHeatPwr 0;
BA_ "GenSigSNA" SG_ 930 VCLEFT_swcHeatPwr "511";
BA_ "Confidence" SG_ 930 VCLEFT_swcHeatDutyCycle 0;
BA_ "GenSigSNA" SG_ 930 VCLEFT_swcHeatDutyCycle "127";
BA_ "Confidence" SG_ 930 VCLEFT_DIeFuseCurrent 0;
BA_ "Confidence" SG_ 930 VCLEFT_SWCpresent 0;
BA_ "Confidence" SG_ 930 VCLEFT_trailerBrakeControllerCur 0;
BA_ "SystemSignalLongSymbol" SG_ 930 VCLEFT_trailerBrakeControllerCur "VCLEFT_trailerBrakeControllerCurrent";
BA_ "Confidence" SG_ 930 VCLEFT_autonomyBehaviorStatus 0;
BA_ "Confidence" SG_ 930 VCLEFT_thirdRowLeftMapLightStatu 0;
BA_ "GenSigSNA" SG_ 930 VCLEFT_thirdRowLeftMapLightStatu "3";
BA_ "SystemSignalLongSymbol" SG_ 930 VCLEFT_thirdRowLeftMapLightStatu "VCLEFT_thirdRowLeftMapLightStatus";
BA_ "Confidence" SG_ 930 VCLEFT_thirdRowRightMapLightStat 0;
BA_ "GenSigSNA" SG_ 930 VCLEFT_thirdRowRightMapLightStat "3";
BA_ "SystemSignalLongSymbol" SG_ 930 VCLEFT_thirdRowRightMapLightStat "VCLEFT_thirdRowRightMapLightStatus";
BA_ "Confidence" SG_ 962 VCLEFT_switchStatusIndex 1;
BA_ "Confidence" SG_ 962 VCLEFT_hornSwitchPressed 0;
BA_ "Confidence" SG_ 962 VCLEFT_hazardButtonPressed 0;
BA_ "Confidence" SG_ 962 VCLEFT_brakeSwitchPressed 0;
BA_ "Confidence" SG_ 962 VCLEFT_rightMirrorTilt 0;
BA_ "Confidence" SG_ 962 VCLEFT_frontSeatTrackBack 0;
BA_ "GenSigSNA" SG_ 962 VCLEFT_frontSeatTrackBack "0";
BA_ "Confidence" SG_ 962 VCLEFT_frontSeatTrackForward 0;
BA_ "GenSigSNA" SG_ 962 VCLEFT_frontSeatTrackForward "0";
BA_ "Confidence" SG_ 962 VCLEFT_frontSeatTiltDown 0;
BA_ "GenSigSNA" SG_ 962 VCLEFT_frontSeatTiltDown "0";
BA_ "Confidence" SG_ 962 VCLEFT_frontSeatTiltUp 0;
BA_ "GenSigSNA" SG_ 962 VCLEFT_frontSeatTiltUp "0";
BA_ "Confidence" SG_ 962 VCLEFT_frontSeatLiftDown 0;
BA_ "GenSigSNA" SG_ 962 VCLEFT_frontSeatLiftDown "0";
BA_ "Confidence" SG_ 962 VCLEFT_frontSeatLiftUp 0;
BA_ "GenSigSNA" SG_ 962 VCLEFT_frontSeatLiftUp "0";
BA_ "Confidence" SG_ 962 VCLEFT_frontSeatBackrestBack 0;
BA_ "GenSigSNA" SG_ 962 VCLEFT_frontSeatBackrestBack "0";
BA_ "Confidence" SG_ 962 VCLEFT_frontSeatBackrestForward 0;
BA_ "GenSigSNA" SG_ 962 VCLEFT_frontSeatBackrestForward "0";
BA_ "Confidence" SG_ 962 VCLEFT_frontSeatLumbarDown 0;
BA_ "GenSigSNA" SG_ 962 VCLEFT_frontSeatLumbarDown "0";
BA_ "Confidence" SG_ 962 VCLEFT_frontSeatLumbarUp 0;
BA_ "GenSigSNA" SG_ 962 VCLEFT_frontSeatLumbarUp "0";
BA_ "Confidence" SG_ 962 VCLEFT_frontSeatLumbarIn 0;
BA_ "GenSigSNA" SG_ 962 VCLEFT_frontSeatLumbarIn "0";
BA_ "Confidence" SG_ 962 VCLEFT_frontSeatLumbarOut 0;
BA_ "GenSigSNA" SG_ 962 VCLEFT_frontSeatLumbarOut "0";
BA_ "Confidence" SG_ 962 VCLEFT_btnWindowSwPackUpLF 0;
BA_ "Confidence" SG_ 962 VCLEFT_btnWindowSwPackAutoUpLF 0;
BA_ "Confidence" SG_ 962 VCLEFT_btnWindowSwPackDownLF 0;
BA_ "Confidence" SG_ 962 VCLEFT_btnWindowSwPackAutoDownLF 0;
BA_ "Confidence" SG_ 962 VCLEFT_btnWindowSwPackUpLR 0;
BA_ "Confidence" SG_ 962 VCLEFT_btnWindowSwPackAutoUpLR 0;
BA_ "Confidence" SG_ 962 VCLEFT_btnWindowSwPackDownLR 0;
BA_ "Confidence" SG_ 962 VCLEFT_btnWindowSwPackAutoDownLR 0;
BA_ "Confidence" SG_ 962 VCLEFT_btnWindowSwPackUpRF 0;
BA_ "Confidence" SG_ 962 VCLEFT_btnWindowSwPackAutoUpRF 0;
BA_ "Confidence" SG_ 962 VCLEFT_btnWindowSwPackDownRF 0;
BA_ "Confidence" SG_ 962 VCLEFT_btnWindowSwPackAutoDownRF 0;
BA_ "Confidence" SG_ 962 VCLEFT_btnWindowSwPackUpRR 0;
BA_ "Confidence" SG_ 962 VCLEFT_btnWindowSwPackAutoUpRR 0;
BA_ "Confidence" SG_ 962 VCLEFT_btnWindowSwPackDownRR 0;
BA_ "Confidence" SG_ 962 VCLEFT_btnWindowSwPackAutoDownRR 0;
BA_ "Confidence" SG_ 962 VCLEFT_frontBuckleSwitch 0;
BA_ "GenSigSNA" SG_ 962 VCLEFT_frontBuckleSwitch "0";
BA_ "Confidence" SG_ 962 VCLEFT_frontOccupancySwitch 0;
BA_ "GenSigSNA" SG_ 962 VCLEFT_frontOccupancySwitch "0";
BA_ "Confidence" SG_ 962 VCLEFT_rearLeftBuckleSwitch 0;
BA_ "GenSigSNA" SG_ 962 VCLEFT_rearLeftBuckleSwitch "0";
BA_ "Confidence" SG_ 962 VCLEFT_rearCenterOccupancySwitch 0;
BA_ "GenSigSNA" SG_ 962 VCLEFT_rearCenterOccupancySwitch "0";
BA_ "Confidence" SG_ 962 VCLEFT_rearLeftOccupancySwitch 0;
BA_ "GenSigSNA" SG_ 962 VCLEFT_rearLeftOccupancySwitch "0";
BA_ "Confidence" SG_ 962 VCLEFT_rearRightOccupancySwitch 0;
BA_ "GenSigSNA" SG_ 962 VCLEFT_rearRightOccupancySwitch "0";
BA_ "Confidence" SG_ 962 VCLEFT_brakePressed 0;
BA_ "Confidence" SG_ 962 VCLEFT_rearHVACButtonPressed 0;
BA_ "Confidence" SG_ 962 VCLEFT_rearCenterBuckleSwitch 0;
BA_ "GenSigSNA" SG_ 962 VCLEFT_rearCenterBuckleSwitch "0";
BA_ "Confidence" SG_ 962 VCLEFT_isAlcoholInterlockSet 0;
BA_ "Confidence" SG_ 962 VCLEFT_swcLeftTiltRight 0;
BA_ "GenSigSNA" SG_ 962 VCLEFT_swcLeftTiltRight "0";
BA_ "Confidence" SG_ 962 VCLEFT_swcLeftPressed 0;
BA_ "GenSigSNA" SG_ 962 VCLEFT_swcLeftPressed "0";
BA_ "Confidence" SG_ 962 VCLEFT_swcRightTiltLeft 0;
BA_ "GenSigSNA" SG_ 962 VCLEFT_swcRightTiltLeft "0";
BA_ "Confidence" SG_ 962 VCLEFT_swcRightTiltRight 0;
BA_ "GenSigSNA" SG_ 962 VCLEFT_swcRightTiltRight "0";
BA_ "Confidence" SG_ 962 VCLEFT_swcRightPressed 0;
BA_ "GenSigSNA" SG_ 962 VCLEFT_swcRightPressed "0";
BA_ "Confidence" SG_ 962 VCLEFT_swcLeftTiltLeft 0;
BA_ "GenSigSNA" SG_ 962 VCLEFT_swcLeftTiltLeft "0";
BA_ "Confidence" SG_ 962 VCLEFT_swcLeftScrollTicks 0;
BA_ "Confidence" SG_ 962 VCLEFT_swcWiperButtonState 0;
BA_ "Confidence" SG_ 962 VCLEFT_swcRightScrollTicks 0;
BA_ "Confidence" SG_ 962 VCLEFT_swcTurnSignalLeftButtonSt 0;
BA_ "SystemSignalLongSymbol" SG_ 962 VCLEFT_swcTurnSignalLeftButtonSt "VCLEFT_swcTurnSignalLeftButtonState";
BA_ "Confidence" SG_ 962 VCLEFT_btnWindowUpLR 0;
BA_ "Confidence" SG_ 962 VCLEFT_btnWindowAutoUpLR 0;
BA_ "Confidence" SG_ 962 VCLEFT_btnWindowDownLR 0;
BA_ "Confidence" SG_ 962 VCLEFT_btnWindowAutoDownLR 0;
BA_ "Confidence" SG_ 962 VCLEFT_2RowSeatLeftFoldFlatSwitc 0;
BA_ "SystemSignalLongSymbol" SG_ 962 VCLEFT_2RowSeatLeftFoldFlatSwitc "VCLEFT_2RowSeatLeftFoldFlatSwitch";
BA_ "Confidence" SG_ 962 VCLEFT_2RowSeatRightFoldFlatSwit 0;
BA_ "SystemSignalLongSymbol" SG_ 962 VCLEFT_2RowSeatRightFoldFlatSwit "VCLEFT_2RowSeatRightFoldFlatSwitch";
BA_ "Confidence" SG_ 962 VCLEFT_2RowSeatBothFoldFlatSwitc 0;
BA_ "SystemSignalLongSymbol" SG_ 962 VCLEFT_2RowSeatBothFoldFlatSwitc "VCLEFT_2RowSeatBothFoldFlatSwitch";
BA_ "Confidence" SG_ 962 VCLEFT_swcLeftDoublePress 0;
BA_ "Confidence" SG_ 962 VCLEFT_swcRightDoublePress 0;
BA_ "Confidence" SG_ 962 VCLEFT_swcTurnSignalRightButtonS 0;
BA_ "SystemSignalLongSymbol" SG_ 962 VCLEFT_swcTurnSignalRightButtonS "VCLEFT_swcTurnSignalRightButtonState";
BA_ "Confidence" SG_ 962 VCLEFT_swcHighBeamButtonState 0;
BA_ "Confidence" SG_ 962 VCLEFT_swcVoiceControlPress 0;
BA_ "GenSigSNA" SG_ 962 VCLEFT_swcVoiceControlPress "0";
BA_ "Confidence" SG_ 962 VCLEFT_swcCameraButtonState 0;
BA_ "Confidence" SG_ 962 VCLEFT_swcRightPressedQF 0;
BA_ "Confidence" SG_ 962 VCLEFT_2RowSeatReclineSwitchpack 0;
BA_ "SystemSignalLongSymbol" SG_ 962 VCLEFT_2RowSeatReclineSwitchpack "VCLEFT_2RowSeatReclineSwitchpackState";
BA_ "Confidence" SG_ 962 VCLEFT_3RowLeftBuckleSwitch 0;
BA_ "GenSigSNA" SG_ 962 VCLEFT_3RowLeftBuckleSwitch "0";
BA_ "Confidence" SG_ 962 VCLEFT_frontSeatThighSupportExte 0;
BA_ "GenSigSNA" SG_ 962 VCLEFT_frontSeatThighSupportExte "0";
BA_ "SystemSignalLongSymbol" SG_ 962 VCLEFT_frontSeatThighSupportExte "VCLEFT_frontSeatThighSupportExtendSwitch";
BA_ "Confidence" SG_ 962 VCLEFT_frontSeatThighSupportRetr 0;
BA_ "GenSigSNA" SG_ 962 VCLEFT_frontSeatThighSupportRetr "0";
BA_ "SystemSignalLongSymbol" SG_ 962 VCLEFT_frontSeatThighSupportRetr "VCLEFT_frontSeatThighSupportRetractSwitch";
BA_ "Confidence" SG_ 962 VCLEFT_frontSeatResistiveOccupan 0;
BA_ "GenSigSNA" SG_ 962 VCLEFT_frontSeatResistiveOccupan "0";
BA_ "SystemSignalLongSymbol" SG_ 962 VCLEFT_frontSeatResistiveOccupan "VCLEFT_frontSeatResistiveOccupancy";
BA_ "Confidence" SG_ 1114 VCRIGHT_AP_hvacState10HzIndex 1;
BA_ "Confidence" SG_ 1114 VCRIGHT_AP_autoDefogAvailable 0;
BA_ "Confidence" SG_ 1114 VCRIGHT_AP_hvacFlashFoggingDetec 0;
BA_ "SystemSignalLongSymbol" SG_ 1114 VCRIGHT_AP_hvacFlashFoggingDetec "VCRIGHT_AP_hvacFlashFoggingDetected";
BA_ "Confidence" SG_ 1114 VCRIGHT_AP_hvacModelInitStatus 0;
BA_ "Confidence" SG_ 1114 VCRIGHT_AP_cabinTempWindshield 0;
BA_ "GenSigSNA" SG_ 1114 VCRIGHT_AP_cabinTempWindshield "255";
BA_ "Confidence" SG_ 1114 VCRIGHT_AP_cabinTempSideGlassRig 0;
BA_ "GenSigSNA" SG_ 1114 VCRIGHT_AP_cabinTempSideGlassRig "255";
BA_ "SystemSignalLongSymbol" SG_ 1114 VCRIGHT_AP_cabinTempSideGlassRig "VCRIGHT_AP_cabinTempSideGlassRight";
BA_ "Confidence" SG_ 1114 VCRIGHT_AP_cabinTempSideGlassLef 0;
BA_ "GenSigSNA" SG_ 1114 VCRIGHT_AP_cabinTempSideGlassLef "255";
BA_ "SystemSignalLongSymbol" SG_ 1114 VCRIGHT_AP_cabinTempSideGlassLef "VCRIGHT_AP_cabinTempSideGlassLeft";
BA_ "Confidence" SG_ 1114 VCRIGHT_AP_hvacRecircDoorPercent 0;
BA_ "Confidence" SG_ 1114 VCRIGHT_AP_hvacAirDistributionMo 0;
BA_ "SystemSignalLongSymbol" SG_ 1114 VCRIGHT_AP_hvacAirDistributionMo "VCRIGHT_AP_hvacAirDistributionMode";
BA_ "Confidence" SG_ 1114 VCRIGHT_AP_hvacEstimateWindshiel 0;
BA_ "SystemSignalLongSymbol" SG_ 1114 VCRIGHT_AP_hvacEstimateWindshiel "VCRIGHT_AP_hvacEstimateWindshieldRH";
BA_ "Confidence" SG_ 1114 VCRIGHT_AP_hvacMassflowTarget 0;
BA_ "Confidence" SG_ 1114 VCRIGHT_AP_tempDuctDefrost 0;
BA_ "GenSigSNA" SG_ 1114 VCRIGHT_AP_tempDuctDefrost "255";
BA_ "Confidence" SG_ 1114 VCRIGHT_AP_cameraTurnOnTime 0;
BA_ "GenSigSNA" SG_ 1114 VCRIGHT_AP_cameraTurnOnTime "511";
BA_ "Confidence" SG_ 1114 VCRIGHT_AP_cameraDefogType 0;
BA_ "Confidence" SG_ 1114 VCRIGHT_ah_hvacFaultSurvivabilit 0;
BA_ "GenSigSNA" SG_ 1114 VCRIGHT_ah_hvacFaultSurvivabilit "31";
BA_ "SystemSignalLongSymbol" SG_ 1114 VCRIGHT_ah_hvacFaultSurvivabilit "VCRIGHT_ah_hvacFaultSurvivabilityTime";
BA_ "Confidence" SG_ 1114 VCRIGHT_ah_defoggingTimeNeeded 0;
BA_ "GenSigSNA" SG_ 1114 VCRIGHT_ah_defoggingTimeNeeded "31";
BA_ "Confidence" SG_ 1114 VCRIGHT_AP_cameraFanDutyRequest 0;
BA_ "GenSigSNA" SG_ 1114 VCRIGHT_AP_cameraFanDutyRequest "127";
BA_ "Confidence" SG_ 1114 VCRIGHT_ah_defogSystemState 0;
BA_ "GenSigSNA" SG_ 1114 VCRIGHT_ah_defogSystemState "7";
BA_ "Confidence" SG_ 1114 VCRIGHT_AP_turnForwardCameraHeat 0;
BA_ "SystemSignalLongSymbol" SG_ 1114 VCRIGHT_AP_turnForwardCameraHeat "VCRIGHT_AP_turnForwardCameraHeaterOnReason";
BA_ "Confidence" SG_ 1114 VCRIGHT_AP_turnCameraFanOffReaso 0;
BA_ "SystemSignalLongSymbol" SG_ 1114 VCRIGHT_AP_turnCameraFanOffReaso "VCRIGHT_AP_turnCameraFanOffReason";
BA_ "Confidence" SG_ 1114 VCRIGHT_AP_forwardCameraIntegrat 0;
BA_ "SystemSignalLongSymbol" SG_ 1114 VCRIGHT_AP_forwardCameraIntegrat "VCRIGHT_AP_forwardCameraIntegratedHeaterRequest";
BA_ "Confidence" SG_ 1114 VCRIGHT_AP_solarFluxOnRightWindo 0;
BA_ "GenSigSNA" SG_ 1114 VCRIGHT_AP_solarFluxOnRightWindo "255";
BA_ "SystemSignalLongSymbol" SG_ 1114 VCRIGHT_AP_solarFluxOnRightWindo "VCRIGHT_AP_solarFluxOnRightWindow";
BA_ "Confidence" SG_ 1114 VCRIGHT_AP_solarFluxOnLeftWindow 0;
BA_ "GenSigSNA" SG_ 1114 VCRIGHT_AP_solarFluxOnLeftWindow "255";
BA_ "Confidence" SG_ 1795 VCRIGHT_debugThermal10HzIndex 1;
BA_ "Confidence" SG_ 1795 VCRIGHT_hvacPanelFloorSplitRow1 0;
BA_ "Confidence" SG_ 1795 VCRIGHT_hvacDefrostPercent 0;
BA_ "Confidence" SG_ 1795 VCRIGHT_hvacRow2Percent 0;
BA_ "Confidence" SG_ 1795 VCRIGHT_hvacPanelFloorSplitRow2 0;
BA_ "Confidence" SG_ 1795 VCRIGHT_hvacFreshMassCounter 0;
BA_ "Confidence" SG_ 1795 VCRIGHT_hvacRecircMassCounter 0;
BA_ "Confidence" SG_ 1795 VCRIGHT_setTempAdjustmentLeft 0;
BA_ "GenSigSNA" SG_ 1795 VCRIGHT_setTempAdjustmentLeft "127";
BA_ "Confidence" SG_ 1795 VCRIGHT_setTempAdjustmentRight 0;
BA_ "GenSigSNA" SG_ 1795 VCRIGHT_setTempAdjustmentRight "127";
BA_ "Confidence" SG_ 1795 VCRIGHT_hvacLHVaneVelocity 0;
BA_ "Confidence" SG_ 1795 VCRIGHT_hvacRHVaneVelocity 0;
BA_ "Confidence" SG_ 1795 VCRIGHT_hvacVehicleSpeed 0;
BA_ "Confidence" SG_ 1795 VCRIGHT_hvacMassflowCompensated 0;
BA_ "Confidence" SG_ 1795 VCRIGHT_PTCcenterPowerLeft 0;
BA_ "GenSigSNA" SG_ 1795 VCRIGHT_PTCcenterPowerLeft "63";
BA_ "Confidence" SG_ 1795 VCRIGHT_PTCouterPowerLeft 0;
BA_ "GenSigSNA" SG_ 1795 VCRIGHT_PTCouterPowerLeft "63";
BA_ "Confidence" SG_ 1795 VCRIGHT_PTCinnerPowerLeft 0;
BA_ "GenSigSNA" SG_ 1795 VCRIGHT_PTCinnerPowerLeft "63";
BA_ "Confidence" SG_ 1795 VCRIGHT_PTCcenterPowerRight 0;
BA_ "GenSigSNA" SG_ 1795 VCRIGHT_PTCcenterPowerRight "63";
BA_ "Confidence" SG_ 1795 VCRIGHT_PTCouterPowerRight 0;
BA_ "GenSigSNA" SG_ 1795 VCRIGHT_PTCouterPowerRight "63";
BA_ "Confidence" SG_ 1795 VCRIGHT_PTCinnerPowerRight 0;
BA_ "GenSigSNA" SG_ 1795 VCRIGHT_PTCinnerPowerRight "63";
BA_ "Confidence" SG_ 1795 VCRIGHT_PTCcenterStoneTempLeft 0;
BA_ "GenSigSNA" SG_ 1795 VCRIGHT_PTCcenterStoneTempLeft "255";
BA_ "Confidence" SG_ 1795 VCRIGHT_PTCcenterStoneTempRight 0;
BA_ "GenSigSNA" SG_ 1795 VCRIGHT_PTCcenterStoneTempRight "255";
BA_ "Confidence" SG_ 1795 VCRIGHT_PTCinnerStoneTempLeft 0;
BA_ "GenSigSNA" SG_ 1795 VCRIGHT_PTCinnerStoneTempLeft "255";
BA_ "Confidence" SG_ 1795 VCRIGHT_PTCinnerStoneTempRight 0;
BA_ "GenSigSNA" SG_ 1795 VCRIGHT_PTCinnerStoneTempRight "255";
BA_ "Confidence" SG_ 1795 VCRIGHT_PTCouterStoneTempLeft 0;
BA_ "GenSigSNA" SG_ 1795 VCRIGHT_PTCouterStoneTempLeft "255";
BA_ "Confidence" SG_ 1795 VCRIGHT_PTCouterRodTempLeft 0;
BA_ "GenSigSNA" SG_ 1795 VCRIGHT_PTCouterRodTempLeft "255";
BA_ "Confidence" SG_ 1795 VCRIGHT_PTCouterAirTempLeft 0;
BA_ "GenSigSNA" SG_ 1795 VCRIGHT_PTCouterAirTempLeft "255";
BA_ "Confidence" SG_ 1795 VCRIGHT_PTCcenterRodTempLeft 0;
BA_ "GenSigSNA" SG_ 1795 VCRIGHT_PTCcenterRodTempLeft "255";
BA_ "Confidence" SG_ 1795 VCRIGHT_PTCinnerRodTempLeft 0;
BA_ "GenSigSNA" SG_ 1795 VCRIGHT_PTCinnerRodTempLeft "255";
BA_ "Confidence" SG_ 1795 VCRIGHT_PTCcenterAirTempLeft 0;
BA_ "GenSigSNA" SG_ 1795 VCRIGHT_PTCcenterAirTempLeft "255";
BA_ "Confidence" SG_ 1795 VCRIGHT_PTCinnerAirTempLeft 0;
BA_ "GenSigSNA" SG_ 1795 VCRIGHT_PTCinnerAirTempLeft "255";
BA_ "Confidence" SG_ 1795 VCRIGHT_PTCouterStoneTempRight 0;
BA_ "GenSigSNA" SG_ 1795 VCRIGHT_PTCouterStoneTempRight "255";
BA_ "Confidence" SG_ 1795 VCRIGHT_PTCouterRodTempRight 0;
BA_ "GenSigSNA" SG_ 1795 VCRIGHT_PTCouterRodTempRight "255";
BA_ "Confidence" SG_ 1795 VCRIGHT_PTCouterAirTempRight 0;
BA_ "GenSigSNA" SG_ 1795 VCRIGHT_PTCouterAirTempRight "255";
BA_ "Confidence" SG_ 1795 VCRIGHT_PTCcenterRodTempRight 0;
BA_ "GenSigSNA" SG_ 1795 VCRIGHT_PTCcenterRodTempRight "255";
BA_ "Confidence" SG_ 1795 VCRIGHT_PTCinnerRodTempRight 0;
BA_ "GenSigSNA" SG_ 1795 VCRIGHT_PTCinnerRodTempRight "255";
BA_ "Confidence" SG_ 1795 VCRIGHT_PTCcenterAirTempRight 0;
BA_ "GenSigSNA" SG_ 1795 VCRIGHT_PTCcenterAirTempRight "255";
BA_ "Confidence" SG_ 1795 VCRIGHT_PTCinnerAirTempRight 0;
BA_ "GenSigSNA" SG_ 1795 VCRIGHT_PTCinnerAirTempRight "255";
BA_ "Confidence" SG_ 291 VCRIGHT_doorStatus2Index 1;
BA_ "Confidence" SG_ 291 VCRIGHT_frontLatchRelDuty 0;
BA_ "Confidence" SG_ 291 VCRIGHT_BPillarCameraHeaterState 0;
BA_ "GenSigSNA" SG_ 291 VCRIGHT_BPillarCameraHeaterState "0";
BA_ "Confidence" SG_ 291 VCRIGHT_doorLatchAjarSwitchVolta 0;
BA_ "SystemSignalLongSymbol" SG_ 291 VCRIGHT_doorLatchAjarSwitchVolta "VCRIGHT_doorLatchAjarSwitchVoltageF";
BA_ "Confidence" SG_ 291 VCRIGHT_doorLatchAjarSwitch_0001 0;
BA_ "SystemSignalLongSymbol" SG_ 291 VCRIGHT_doorLatchAjarSwitch_0001 "VCRIGHT_doorLatchAjarSwitchVoltageR";
BA_ "Confidence" SG_ 291 VCRIGHT_BPillarCameraHeaterCurre 0;
BA_ "GenSigSNA" SG_ 291 VCRIGHT_BPillarCameraHeaterCurre "63";
BA_ "SystemSignalLongSymbol" SG_ 291 VCRIGHT_BPillarCameraHeaterCurre "VCRIGHT_BPillarCameraHeaterCurrent";
BA_ "Confidence" SG_ 291 VCRIGHT_mirrorTiltXOffset 0;
BA_ "Confidence" SG_ 291 VCRIGHT_mirrorTiltYOffset 0;
BA_ "Confidence" SG_ 739 VCRIGHT_seatStatus2Index 1;
BA_ "Confidence" SG_ 739 VCRIGHT_frontSeatHeatCurrent 0;
BA_ "GenSigSNA" SG_ 739 VCRIGHT_frontSeatHeatCurrent "12";
BA_ "Confidence" SG_ 739 VCRIGHT_frontSeatHeatDuty 0;
BA_ "Confidence" SG_ 739 VCRIGHT_frontSeatHeatTmp 0;
BA_ "Confidence" SG_ 739 VCRIGHT_frontSeatHeatTmpTarget 0;
BA_ "Confidence" SG_ 739 VCRIGHT_frontSeatHeatInhibited 0;
BA_ "Confidence" SG_ 739 VCRIGHT_frontSeatHeatPowered 0;
BA_ "Confidence" SG_ 739 VC_AH_1RowRightSeatHeatVentHealt 0;
BA_ "SystemSignalLongSymbol" SG_ 739 VC_AH_1RowRightSeatHeatVentHealt "VC_AH_1RowRightSeatHeatVentHealth";
BA_ "Confidence" SG_ 739 VCRIGHT_rearLSeatHeatCurrent 0;
BA_ "Confidence" SG_ 739 VCRIGHT_rearLSeatHeatDuty 0;
BA_ "Confidence" SG_ 739 VCRIGHT_rearLSeatHeatTmp 0;
BA_ "Confidence" SG_ 739 VCRIGHT_rearLSeatHeatTmpTarget 0;
BA_ "Confidence" SG_ 739 VCRIGHT_rearLSeatHeatInhibited 0;
BA_ "Confidence" SG_ 739 VCRIGHT_rearLSeatHeatPowered 0;
BA_ "Confidence" SG_ 739 VCRIGHT_rearCSeatHeatCurrent 0;
BA_ "Confidence" SG_ 739 VCRIGHT_rearCSeatHeatDuty 0;
BA_ "Confidence" SG_ 739 VCRIGHT_rearCSeatHeatTmp 0;
BA_ "Confidence" SG_ 739 VCRIGHT_rearCSeatHeatTmpTarget 0;
BA_ "Confidence" SG_ 739 VCRIGHT_rearCSeatHeatInhibited 0;
BA_ "Confidence" SG_ 739 VCRIGHT_rearCSeatHeatPowered 0;
BA_ "Confidence" SG_ 739 VCRIGHT_rearRSeatHeatCurrent 0;
BA_ "Confidence" SG_ 739 VCRIGHT_rearRSeatHeatDuty 0;
BA_ "Confidence" SG_ 739 VCRIGHT_rearRSeatHeatTmp 0;
BA_ "Confidence" SG_ 739 VCRIGHT_rearRSeatHeatTmpTarget 0;
BA_ "Confidence" SG_ 739 VCRIGHT_rearRSeatHeatInhibited 0;
BA_ "Confidence" SG_ 739 VCRIGHT_rearRSeatHeatPowered 0;
BA_ "Confidence" SG_ 739 VCRIGHT_2RowSeatReclineState 0;
BA_ "GenSigSNA" SG_ 739 VCRIGHT_2RowSeatReclineState "15";
BA_ "Confidence" SG_ 739 VCRIGHT_2RowSeatReclineDuty 0;
BA_ "Confidence" SG_ 739 VCRIGHT_2RowSeatReclineCurrent 0;
BA_ "Confidence" SG_ 739 VCRIGHT_2RowSeatReclineCalibrate 0;
BA_ "SystemSignalLongSymbol" SG_ 739 VCRIGHT_2RowSeatReclineCalibrate "VCRIGHT_2RowSeatReclineCalibrated";
BA_ "Confidence" SG_ 739 VCRIGHT_2RowSeatReclinePositionR 0;
BA_ "SystemSignalLongSymbol" SG_ 739 VCRIGHT_2RowSeatReclinePositionR "VCRIGHT_2RowSeatReclinePositionRaw";
BA_ "Confidence" SG_ 739 VCRIGHT_2RowSeatReclineAngle 0;
BA_ "Confidence" SG_ 739 VCRIGHT_2RowSeatReclineAbsPosSwi 0;
BA_ "GenSigSNA" SG_ 739 VCRIGHT_2RowSeatReclineAbsPosSwi "0";
BA_ "SystemSignalLongSymbol" SG_ 739 VCRIGHT_2RowSeatReclineAbsPosSwi "VCRIGHT_2RowSeatReclineAbsPosSwitchState";
BA_ "Confidence" SG_ 739 VCRIGHT_2RowSeatReclinePositionS 0;
BA_ "GenSigSNA" SG_ 739 VCRIGHT_2RowSeatReclinePositionS "4";
BA_ "SystemSignalLongSymbol" SG_ 739 VCRIGHT_2RowSeatReclinePositionS "VCRIGHT_2RowSeatReclinePositionState";
BA_ "Confidence" SG_ 739 VCRIGHT_2RowSeatReclineAdjustmen 0;
BA_ "SystemSignalLongSymbol" SG_ 739 VCRIGHT_2RowSeatReclineAdjustmen "VCRIGHT_2RowSeatReclineAdjustmentAllowed";
BA_ "Confidence" SG_ 739 VCRIGHT_2RowSeatReclineFoldAllow 0;
BA_ "SystemSignalLongSymbol" SG_ 739 VCRIGHT_2RowSeatReclineFoldAllow "VCRIGHT_2RowSeatReclineFoldAllowed";
BA_ "Confidence" SG_ 739 VCRIGHT_2RowSeatReclineUnfoldAll 0;
BA_ "SystemSignalLongSymbol" SG_ 739 VCRIGHT_2RowSeatReclineUnfoldAll "VCRIGHT_2RowSeatReclineUnfoldAllowed";
BA_ "Confidence" SG_ 739 VCRIGHT_2RowSeatReclineNextToggl 0;
BA_ "GenSigSNA" SG_ 739 VCRIGHT_2RowSeatReclineNextToggl "2";
BA_ "SystemSignalLongSymbol" SG_ 739 VCRIGHT_2RowSeatReclineNextToggl "VCRIGHT_2RowSeatReclineNextToggleDirection";
BA_ "Confidence" SG_ 739 VCRIGHT_2RowSeatReclineChoreoBlo 0;
BA_ "SystemSignalLongSymbol" SG_ 739 VCRIGHT_2RowSeatReclineChoreoBlo "VCRIGHT_2RowSeatReclineChoreoBlockedByOccupancy";
BA_ "Confidence" SG_ 739 VCRIGHT_2RowSeat1RClashAvoidance 0;
BA_ "SystemSignalLongSymbol" SG_ 739 VCRIGHT_2RowSeat1RClashAvoidance "VCRIGHT_2RowSeat1RClashAvoidanceBlockedReason";
BA_ "Confidence" SG_ 739 VCRIGHT_2RowSeat1RClashAvoi_0001 0;
BA_ "SystemSignalLongSymbol" SG_ 739 VCRIGHT_2RowSeat1RClashAvoi_0001 "VCRIGHT_2RowSeat1RClashAvoidanceState";
BA_ "Confidence" SG_ 739 VCRIGHT_2RowSeatReclineAbsP_0001 0;
BA_ "SystemSignalLongSymbol" SG_ 739 VCRIGHT_2RowSeatReclineAbsP_0001 "VCRIGHT_2RowSeatReclineAbsPosSwitchTransPoint";
BA_ "Confidence" SG_ 739 VC_AH_2RowRightSeatMovementHealt 0;
BA_ "SystemSignalLongSymbol" SG_ 739 VC_AH_2RowRightSeatMovementHealt "VC_AH_2RowRightSeatMovementHealth";
BA_ "Confidence" SG_ 739 VCRIGHT_3RowSeatReclineState 0;
BA_ "GenSigSNA" SG_ 739 VCRIGHT_3RowSeatReclineState "15";
BA_ "Confidence" SG_ 739 VCRIGHT_3RowSeatReclineDuty 0;
BA_ "Confidence" SG_ 739 VCRIGHT_3RowSeatReclineCurrent 0;
BA_ "Confidence" SG_ 739 VCRIGHT_3RowSeatReclineCalibrate 0;
BA_ "SystemSignalLongSymbol" SG_ 739 VCRIGHT_3RowSeatReclineCalibrate "VCRIGHT_3RowSeatReclineCalibrated";
BA_ "Confidence" SG_ 739 VCRIGHT_3RowSeatReclinePositionR 0;
BA_ "SystemSignalLongSymbol" SG_ 739 VCRIGHT_3RowSeatReclinePositionR "VCRIGHT_3RowSeatReclinePositionRaw";
BA_ "Confidence" SG_ 739 VCRIGHT_3RowSeatReclineAngle 0;
BA_ "Confidence" SG_ 739 VCRIGHT_3RowSeatReclineNextToggl 0;
BA_ "GenSigSNA" SG_ 739 VCRIGHT_3RowSeatReclineNextToggl "2";
BA_ "SystemSignalLongSymbol" SG_ 739 VCRIGHT_3RowSeatReclineNextToggl "VCRIGHT_3RowSeatReclineNextToggleDirection";
BA_ "Confidence" SG_ 739 VCRIGHT_3RRightSeatHeatCurrent 0;
BA_ "Confidence" SG_ 739 VCRIGHT_3RRightSeatHeatDuty 0;
BA_ "Confidence" SG_ 739 VCRIGHT_3RRightSeatHeatTmp 0;
BA_ "Confidence" SG_ 739 VCRIGHT_3RRightSeatHeatTmpTarget 0;
BA_ "Confidence" SG_ 739 VCRIGHT_3RRightSeatHeatInhibited 0;
BA_ "Confidence" SG_ 739 VCRIGHT_3RowSeatReclinePositionS 0;
BA_ "GenSigSNA" SG_ 739 VCRIGHT_3RowSeatReclinePositionS "4";
BA_ "SystemSignalLongSymbol" SG_ 739 VCRIGHT_3RowSeatReclinePositionS "VCRIGHT_3RowSeatReclinePositionState";
BA_ "Confidence" SG_ 739 VCRIGHT_3RowSeatReclineAdjustmen 0;
BA_ "SystemSignalLongSymbol" SG_ 739 VCRIGHT_3RowSeatReclineAdjustmen "VCRIGHT_3RowSeatReclineAdjustmentAllowed";
BA_ "Confidence" SG_ 739 VCRIGHT_3RowSeatReclineFoldAllow 0;
BA_ "SystemSignalLongSymbol" SG_ 739 VCRIGHT_3RowSeatReclineFoldAllow "VCRIGHT_3RowSeatReclineFoldAllowed";
BA_ "Confidence" SG_ 739 VCRIGHT_3RowSeatReclineUnfoldAll 0;
BA_ "SystemSignalLongSymbol" SG_ 739 VCRIGHT_3RowSeatReclineUnfoldAll "VCRIGHT_3RowSeatReclineUnfoldAllowed";
BA_ "Confidence" SG_ 739 VCRIGHT_3RowSeatReclineChoreoBlo 0;
BA_ "SystemSignalLongSymbol" SG_ 739 VCRIGHT_3RowSeatReclineChoreoBlo "VCRIGHT_3RowSeatReclineChoreoBlockedByOccupancy";
BA_ "Confidence" SG_ 739 VCRIGHT_3RowSeatReclineAbsPosSwi 0;
BA_ "GenSigSNA" SG_ 739 VCRIGHT_3RowSeatReclineAbsPosSwi "0";
BA_ "SystemSignalLongSymbol" SG_ 739 VCRIGHT_3RowSeatReclineAbsPosSwi "VCRIGHT_3RowSeatReclineAbsPosSwitchState";
BA_ "Confidence" SG_ 835 VCRIGHT_autonomyBehaviorStatus 0;
BA_ "Confidence" SG_ 835 VCRIGHT_LVBatteryTypeDBG 0;
BA_ "Confidence" SG_ 835 VCRIGHT_rearDefrostState 0;
BA_ "GenSigSNA" SG_ 835 VCRIGHT_rearDefrostState "0";
BA_ "Confidence" SG_ 835 VCRIGHT_mirrorHeatState 0;
BA_ "GenSigSNA" SG_ 835 VCRIGHT_mirrorHeatState "0";
BA_ "Confidence" SG_ 835 VCRIGHT_OTAState 0;
BA_ "Confidence" SG_ 835 VCRIGHT_5AVoltage 0;
BA_ "Confidence" SG_ 835 VCRIGHT_vbatProt 0;
BA_ "Confidence" SG_ 835 VCRIGHT_rationalityAggregateCurr 0;
BA_ "SystemSignalLongSymbol" SG_ 835 VCRIGHT_rationalityAggregateCurr "VCRIGHT_rationalityAggregateCurrent";
BA_ "Confidence" SG_ 835 VCRIGHT_eFuseMgmtVoltageMonitor 0;
BA_ "Confidence" SG_ 835 VCRIGHT_isSteeringWheelHeaterReq 0;
BA_ "Confidence" SG_ 835 VCRIGHT_steeringWheelHeaterDCTgt 0;
BA_ "GenSigSNA" SG_ 835 VCRIGHT_steeringWheelHeaterDCTgt "127";
BA_ "Confidence" SG_ 899 VCRIGHT_thsActive 0;
BA_ "Confidence" SG_ 899 VCRIGHT_thsTemperature 0;
BA_ "GenSigSNA" SG_ 899 VCRIGHT_thsTemperature "255";
BA_ "Confidence" SG_ 899 VCRIGHT_thsState 0;
BA_ "Confidence" SG_ 899 VCRIGHT_thsLINCurrentSchedule 0;
BA_ "Confidence" SG_ 899 VCRIGHT_thsDetected 0;
BA_ "Confidence" SG_ 899 VCRIGHT_thsHumidity 0;
BA_ "GenSigSNA" SG_ 899 VCRIGHT_thsHumidity "127";
BA_ "Confidence" SG_ 899 VCRIGHT_estimatedVehicleSituatio 0;
BA_ "SystemSignalLongSymbol" SG_ 899 VCRIGHT_estimatedVehicleSituatio "VCRIGHT_estimatedVehicleSituation";
BA_ "Confidence" SG_ 899 VCRIGHT_thsSolarLoadInfrared 0;
BA_ "GenSigSNA" SG_ 899 VCRIGHT_thsSolarLoadInfrared "1023";
BA_ "Confidence" SG_ 899 VCRIGHT_thsSolarLoadVisible 0;
BA_ "GenSigSNA" SG_ 899 VCRIGHT_thsSolarLoadVisible "1023";
BA_ "Confidence" SG_ 899 VCRIGHT_estimatedThsSolarLoad 0;
BA_ "GenSigSNA" SG_ 899 VCRIGHT_estimatedThsSolarLoad "1023";
BA_ "Confidence" SG_ 899 VCRIGHT_hvacFastLoggingEnabled 0;
BA_ "Confidence" SG_ 1066 VCSEC_TPMSSensorState0 0;
BA_ "Confidence" SG_ 1066 VCSEC_TPMSRSSI0 0;
BA_ "Confidence" SG_ 1066 VCSEC_TPMSConnectionTypeCurrent0 0;
BA_ "Confidence" SG_ 1066 VCSEC_TPMSConnectionTypeDesired0 0;
BA_ "Confidence" SG_ 1066 VCSEC_TPMSSensorState1 0;
BA_ "Confidence" SG_ 1066 VCSEC_TPMSRSSI1 0;
BA_ "Confidence" SG_ 1066 VCSEC_TPMSConnectionTypeCurrent1 0;
BA_ "Confidence" SG_ 1066 VCSEC_TPMSConnectionTypeDesired1 0;
BA_ "Confidence" SG_ 1066 VCSEC_TPMSSensorState2 0;
BA_ "Confidence" SG_ 1066 VCSEC_TPMSRSSI2 0;
BA_ "Confidence" SG_ 1066 VCSEC_TPMSConnectionTypeCurrent2 0;
BA_ "Confidence" SG_ 1066 VCSEC_TPMSConnectionTypeDesired2 0;
BA_ "Confidence" SG_ 1066 VCSEC_TPMSSensorState3 0;
BA_ "Confidence" SG_ 1066 VCSEC_TPMSRSSI3 0;
BA_ "Confidence" SG_ 1066 VCSEC_TPMSConnectionTypeCurrent3 0;
BA_ "Confidence" SG_ 1066 VCSEC_TPMSConnectionTypeDesired3 0;
BA_ "Confidence" SG_ 1066 VCSEC_TPMSSensorPresence0 0;
BA_ "Confidence" SG_ 1066 VCSEC_TPMSSensorPresence1 0;
BA_ "Confidence" SG_ 1066 VCSEC_TPMSSensorPresence2 0;
BA_ "Confidence" SG_ 1066 VCSEC_TPMSSensorPresence3 0;
BA_ "Confidence" SG_ 1824 VCSEC_ECUConfigCRC32 0;
BA_ "Confidence" SG_ 1824 VCSEC_autoWriteConfig 0;
BA_ "Confidence" SG_ 1824 VCSEC_requestForConfig 0;
BA_ "Confidence" SG_ 281 VCSEC_activeImmobilizerAuthLevel 0;
BA_ "Confidence" SG_ 281 VCSEC_smartTrunkLightRequest 0;
BA_ "Confidence" SG_ 281 VCSEC_smartTrunkSoundRequest 0;
BA_ "Confidence" SG_ 281 VCSEC_hvacRunScreenProtectOnly 0;
BA_ "Confidence" SG_ 281 VCSEC_chargeHandleRequestModel 0;
BA_ "Confidence" SG_ 281 VCSEC_recoveryModeRequested 0;
BA_ "Confidence" SG_ 281 VCSEC_infotainmentResetRequested 0;
BA_ "Confidence" SG_ 281 VCSEC_mobileToAPRequest 0;
BA_ "Confidence" SG_ 281 VCSEC_riderKeyPresent 0;
VAL_ 1353 VCFRONT_homelinkCommStatus 3 "HOMELINK_COMM_STATUS_FAULT" 2 "HOMELINK_COMM_STATUS_ON" 1 "HOMELINK_COMM_STATUS_OFF" 0 "HOMELINK_COMM_STATUS_SNA" ;
VAL_ 1801 VCFRONT_logging0point1HzIndex 35 "END" 34 "DYNAMIC_LEVELING_CONTRIBUTORS" 33 "HEADLAMP_OFFSETS_AND_STATUS" 32 "HEADLAMP_LEFT_ECULESS_IO_DIAGNOSTIC_2" 31 "HEADLAMP_RIGHT_ECULESS_IO_DIAGNOSTIC_2" 30 "HEADLAMP_LEFT_ECULESS_IO_DIAGNOSTIC" 29 "HEADLAMP_RIGHT_ECULESS_IO_DIAGNOSTIC" 28 "COMPRESSOR_WEAR_COUNTERS" 27 "HEADLAMP_RIGHT_EEPROM_INFO" 26 "HEADLAMP_LEFT_EEPROM_INFO" 25 "EXV_VALVE_TYPES" 24 "PART_FAILURE_CONFIDENCE_CONTINUED" 23 "PART_FAILURE_CONFIDENCE" 22 "LIGHT_DEBUG" 21 "HEADLAMP_COMM_FAULT_COUNTERS" 20 "HEADLAMP_MIGRATION" 19 "EXV_TOTAL_DISTANCE_COUNTERS_3" 18 "EXV_TOTAL_DISTANCE_COUNTERS_2" 17 "EXV_TOTAL_DISTANCE_COUNTERS_1" 16 "EXV_CCR_COUNTERS_2" 15 "EXV_CCR_COUNTERS_1" 14 "EXV_CCL_COUNTERS_2" 13 "EXV_CCL_COUNTERS_1" 12 "EXV_LCC_COUNTERS_2" 11 "EXV_LCC_COUNTERS_1" 10 "EXV_RECIRC_COUNTERS_2" 9 "EXV_RECIRC_COUNTERS_1" 8 "EXV_EVAPORATOR_COUNTERS_2" 7 "EXV_EVAPORATOR_COUNTERS_1" 6 "EXV_CHILLER_COUNTERS_2" 5 "EXV_CHILLER_COUNTERS_1" 4 "HEADLAMP_AIMED_POSITION" 3 "HEADLAMP_CURRENT_POSITION" 2 "HCMR_LED_TEMPS" 1 "HCML_LED_TEMPS" 0 "LIGHT_CURRENTS" ;
VAL_ 1801 VC_hcmlFactoryOfOrigin 3 "HELLA_MEXICO" 2 "HELLA_SLOVAKIA" 1 "HELLA_CHINA" 0 "UNKNOWN" ;
VAL_ 1801 VC_hcmlHellaPartNumberStatus 1 "FAULT" 0 "OK" ;
VAL_ 1801 VC_hcmlCurrentBinMappingType 2 "BIN_MAP_TYPE_2" 1 "BIN_MAP_TYPE_1" 0 "BIN_MAP_TYPE_UNKNOWN" ;
VAL_ 1801 VC_hcmlCurrentBin0Value 7 "INVALID_LIGHTCLASS" 4 "LIGHTCLASS_4" 3 "LIGHTCLASS_3" 2 "LIGHTCLASS_2" 1 "LIGHTCLASS_1" 0 "LIGHTCLASS_SNA" ;
VAL_ 1801 VC_hcmlCurrentBin1Value 7 "INVALID_LIGHTCLASS" 4 "LIGHTCLASS_4" 3 "LIGHTCLASS_3" 2 "LIGHTCLASS_2" 1 "LIGHTCLASS_1" 0 "LIGHTCLASS_SNA" ;
VAL_ 1801 VC_hcmlCurrentBin2Value 7 "INVALID_LIGHTCLASS" 4 "LIGHTCLASS_4" 3 "LIGHTCLASS_3" 2 "LIGHTCLASS_2" 1 "LIGHTCLASS_1" 0 "LIGHTCLASS_SNA" ;
VAL_ 1801 VC_hcmlCurrentBin3Value 7 "INVALID_LIGHTCLASS" 4 "LIGHTCLASS_4" 3 "LIGHTCLASS_3" 2 "LIGHTCLASS_2" 1 "LIGHTCLASS_1" 0 "LIGHTCLASS_SNA" ;
VAL_ 1801 VC_hcmlCurrentBin4Value 7 "INVALID_LIGHTCLASS" 4 "LIGHTCLASS_4" 3 "LIGHTCLASS_3" 2 "LIGHTCLASS_2" 1 "LIGHTCLASS_1" 0 "LIGHTCLASS_SNA" ;
VAL_ 1801 VC_hcmlCurrentBin5Value 7 "INVALID_LIGHTCLASS" 4 "LIGHTCLASS_4" 3 "LIGHTCLASS_3" 2 "LIGHTCLASS_2" 1 "LIGHTCLASS_1" 0 "LIGHTCLASS_SNA" ;
VAL_ 1801 VC_hcmlRegionAndSide 6 "HEADLAMP_REGION_AND_SIDE_ECE_RHD_RIGHT" 5 "HEADLAMP_REGION_AND_SIDE_ECE_RHD_LEFT" 4 "HEADLAMP_REGION_AND_SIDE_ECE_LHD_RIGHT" 3 "HEADLAMP_REGION_AND_SIDE_ECE_LHD_LEFT" 2 "HEADLAMP_REGION_AND_SIDE_SAE_RIGHT" 1 "HEADLAMP_REGION_AND_SIDE_SAE_LEFT" 0 "HEADLAMP_REGION_AND_SIDE_SNA" ;
VAL_ 1801 VC_hcmrFactoryOfOrigin 3 "HELLA_MEXICO" 2 "HELLA_SLOVAKIA" 1 "HELLA_CHINA" 0 "UNKNOWN" ;
VAL_ 1801 VC_hcmrHellaPartNumberStatus 1 "FAULT" 0 "OK" ;
VAL_ 1801 VC_hcmrCurrentBinMappingType 2 "BIN_MAP_TYPE_2" 1 "BIN_MAP_TYPE_1" 0 "BIN_MAP_TYPE_UNKNOWN" ;
VAL_ 1801 VC_hcmrCurrentBin0Value 7 "INVALID_LIGHTCLASS" 4 "LIGHTCLASS_4" 3 "LIGHTCLASS_3" 2 "LIGHTCLASS_2" 1 "LIGHTCLASS_1" 0 "LIGHTCLASS_SNA" ;
VAL_ 1801 VC_hcmrCurrentBin1Value 7 "INVALID_LIGHTCLASS" 4 "LIGHTCLASS_4" 3 "LIGHTCLASS_3" 2 "LIGHTCLASS_2" 1 "LIGHTCLASS_1" 0 "LIGHTCLASS_SNA" ;
VAL_ 1801 VC_hcmrCurrentBin2Value 7 "INVALID_LIGHTCLASS" 4 "LIGHTCLASS_4" 3 "LIGHTCLASS_3" 2 "LIGHTCLASS_2" 1 "LIGHTCLASS_1" 0 "LIGHTCLASS_SNA" ;
VAL_ 1801 VC_hcmrCurrentBin3Value 7 "INVALID_LIGHTCLASS" 4 "LIGHTCLASS_4" 3 "LIGHTCLASS_3" 2 "LIGHTCLASS_2" 1 "LIGHTCLASS_1" 0 "LIGHTCLASS_SNA" ;
VAL_ 1801 VC_hcmrCurrentBin4Value 7 "INVALID_LIGHTCLASS" 4 "LIGHTCLASS_4" 3 "LIGHTCLASS_3" 2 "LIGHTCLASS_2" 1 "LIGHTCLASS_1" 0 "LIGHTCLASS_SNA" ;
VAL_ 1801 VC_hcmrCurrentBin5Value 7 "INVALID_LIGHTCLASS" 4 "LIGHTCLASS_4" 3 "LIGHTCLASS_3" 2 "LIGHTCLASS_2" 1 "LIGHTCLASS_1" 0 "LIGHTCLASS_SNA" ;
VAL_ 1801 VC_hcmrRegionAndSide 6 "HEADLAMP_REGION_AND_SIDE_ECE_RHD_RIGHT" 5 "HEADLAMP_REGION_AND_SIDE_ECE_RHD_LEFT" 4 "HEADLAMP_REGION_AND_SIDE_ECE_LHD_RIGHT" 3 "HEADLAMP_REGION_AND_SIDE_ECE_LHD_LEFT" 2 "HEADLAMP_REGION_AND_SIDE_SAE_RIGHT" 1 "HEADLAMP_REGION_AND_SIDE_SAE_LEFT" 0 "HEADLAMP_REGION_AND_SIDE_SNA" ;
VAL_ 957 VCFRONT_energyLossIndex 4 "SINCE_LAST_CHARGE2" 3 "SINCE_LAST_CHARGE" 2 "SINCE_LAST_DRIVE2" 1 "SINCE_LAST_DRIVE" 0 "STATUS" ;
VAL_ 737 VCFRONT_statusIndex 6 "INVALID" 5 "USER_PRESENCE" 4 "THERMAL" 3 "SYSTEM_HEALTH" 2 "REFRIGERANT_SYSTEM" 1 "VEHICLE_STATE" 0 "BODY_CONTROLS" ;
VAL_ 737 VCFRONT_frunkLatchStatus 8 "LATCH_FAULT" 7 "LATCH_DEFAULT" 6 "LATCH_TIMEOUT" 5 "LATCH_AJAR" 4 "LATCH_OPENING" 3 "LATCH_CLOSING" 2 "LATCH_CLOSED" 1 "LATCH_OPENED" 0 "LATCH_SNA" ;
VAL_ 737 VCFRONT_wiperSpeed 9 "WIPER_SPEED_NARROW" 8 "WIPER_SPEED_HIGH" 7 "WIPER_SPEED_LOW" 6 "WIPER_SPEED_5" 5 "WIPER_SPEED_4" 4 "WIPER_SPEED_3" 3 "WIPER_SPEED_2" 2 "WIPER_SPEED_1" 1 "WIPER_SPEED_OFF" 0 "WIPER_SPEED_SNA" ;
VAL_ 737 VCFRONT_wiperPosition 4 "WIPER_POSITION_WIPING" 3 "WIPER_POSITION_DELAYED_REST" 2 "WIPER_POSITION_DEPRESSED_PARK" 1 "WIPER_POSITION_SERVICE" 0 "WIPER_POSITION_SNA" ;
VAL_ 737 VCFRONT_wiperState 14 "WIPER_STATE_NARROW_WASH" 13 "WIPER_STATE_NARROW_WIPE" 12 "WIPER_STATE_INT_AUTO_HIGH" 11 "WIPER_STATE_INT_AUTO_LOW" 10 "WIPER_STATE_CONT_SLOW" 9 "WIPER_STATE_CONT_FAST" 8 "WIPER_STATE_INTERMITTENT_LOW" 7 "WIPER_STATE_INTERMITTENT_HIGH" 6 "WIPER_STATE_MOMENTARY_WIPE" 5 "WIPER_STATE_WASH" 4 "WIPER_STATE_PARK" 3 "WIPER_STATE_DELAYED_REST" 2 "WIPER_STATE_FAULT" 1 "WIPER_STATE_SERVICE" 0 "WIPER_STATE_SNA" ;
VAL_ 737 VCFRONT_crashDetectedType 3 "CRASH_DETECTED_TYPE_SEVERE" 2 "CRASH_DETECTED_TYPE_MINOR_2" 1 "CRASH_DETECTED_TYPE_MINOR_1" 0 "CRASH_DETECTED_TYPE_NONE" ;
VAL_ 737 VCFRONT_crashState 3 "CRASH_STATE_SEVERE" 2 "CRASH_STATE_MINOR_2" 1 "CRASH_STATE_MINOR_1" 0 "CRASH_STATE_IDLE" ;
VAL_ 737 VCFRONT_washPumpState 3 "WASH_PUMP_BIDIRECTIONAL_STATE_SNA" 2 "WASH_PUMP_BIDIRECTIONAL_STATE_DRIVING_SECONDARY" 1 "WASH_PUMP_BIDIRECTIONAL_STATE_DRIVING_PRIMARY" 0 "WASH_PUMP_BIDIRECTIONAL_STATE_OFF" ;
VAL_ 737 VCFRONT_turnIndicatorControlType 2 "TURN_INDICATOR_CONTROL_TYPE_SWS_BUTTON" 1 "TURN_INDICATOR_CONTROL_TYPE_SINGLE_DETENT_STALK" 0 "TURN_INDICATOR_CONTROL_TYPE_UNKNOWN" ;
VAL_ 737 VCFRONT_wiperHealth 7 "WIPER_HEALTH_RESERVED" 5 "WIPER_HEALTH_FAULT" 4 "WIPER_HEALTH_UPDATING" 3 "WIPER_HEALTH_TIMEOUT" 2 "WIPER_HEALTH_OK" 1 "WIPER_HEALTH_WAIT" 0 "WIPER_HEALTH_OFF" ;
VAL_ 737 VCFRONT_wiperLINHealth 7 "WIPER_HEALTH_RESERVED" 5 "WIPER_HEALTH_FAULT" 4 "WIPER_HEALTH_UPDATING" 3 "WIPER_HEALTH_TIMEOUT" 2 "WIPER_HEALTH_OK" 1 "WIPER_HEALTH_WAIT" 0 "WIPER_HEALTH_OFF" ;
VAL_ 737 VCFRONT_radarHeaterState 4 "HEATER_STATE_FAULT" 3 "HEATER_STATE_OFF_UNAVAILABLE" 2 "HEATER_STATE_OFF" 1 "HEATER_STATE_ON" 0 "HEATER_STATE_SNA" ;
VAL_ 737 VCFRONT_passengerBuckleStatus 1 "BUCKLED" 0 "UNBUCKLED" ;
VAL_ 737 VCFRONT_frunkLatchType 2 "FRUNK_LATCH_TYPE_DOUBLE_PULL" 1 "FRUNK_LATCH_TYPE_DOUBLE_ACTUATOR" 0 "FRUNK_LATCH_TYPE_UNKNOWN" ;
VAL_ 737 VCFRONT_iBoosterStateDBG 4 "IBOOSTER_FORCE_OFF" 3 "IBOOSTER_WRITING_DATA_SHUTDOWN" 2 "IBOOSTER_GOING_DOWN" 1 "IBOOSTER_ON" 0 "IBOOSTER_OFF" ;
VAL_ 737 VCFRONT_vehicleStatusDBG 18 "VEHICLE_STATUS_SNA" 17 "VEHICLE_STATUS_RESET" 16 "VEHICLE_STATUS_TURN_ON_RAILS" 15 "VEHICLE_STATUS_OTA" 14 "VEHICLE_STATUS_CRASH" 13 "VEHICLE_STATUS_DRIVE" 12 "VEHICLE_STATUS_CONDITIONING" 11 "VEHICLE_STATUS_ACCESSORY_PLUS" 10 "VEHICLE_STATUS_ACCESSORY" 9 "VEHICLE_STATUS_HV_UP_STANDBY" 8 "VEHICLE_STATUS_LV_AWAKE" 7 "VEHICLE_STATUS_LV_SHUTDOWN" 6 "VEHICLE_STATUS_SLEEP_STANDBY" 5 "VEHICLE_STATUS_SLEEP_SHUTDOWN" 4 "VEHICLE_STATUS_SYSTEM_CHECKS" 3 "VEHICLE_STATUS_BATTERY_POST_WAKE" 2 "VEHICLE_STATUS_SILENT_WAKE" 1 "VEHICLE_STATUS_LOW_POWER_STANDBY" 0 "VEHICLE_STATUS_INIT" ;
VAL_ 737 VCFRONT_sleepCurrent 4095 "SNA" ;
VAL_ 737 VCFRONT_hibernationState 5 "VC_HIBERNATION_STATE_PREP" 4 "VC_HIBERNATION_STATE_EXIT" 3 "VC_HIBERNATION_STATE_RECOVERY" 2 "VC_HIBERNATION_STATE_ACTIVE" 1 "VC_HIBERNATION_STATE_NOT_ACTIVE" 0 "VC_HIBERNATION_STATE_INIT" ;
VAL_ 737 VCFRONT_wiperECUType 3 "WIPER_ECU_TYPE_VALEO" 2 "WIPER_ECU_TYPE_SHB" 1 "WIPER_ECU_TYPE_BOSCH" 0 "WIPER_ECU_TYPE_UNKNOWN" ;
VAL_ 737 VCFRONT_wiperHeaterState 4 "HEATER_STATE_FAULT" 3 "HEATER_STATE_OFF_UNAVAILABLE" 2 "HEATER_STATE_OFF" 1 "HEATER_STATE_ON" 0 "HEATER_STATE_SNA" ;
VAL_ 737 VCFRONT_closureEasterEggState 5 "CLOSURE_EASTEREGG_STATE_SHOW_CLEANUP" 4 "CLOSURE_EASTEREGG_STATE_PLAY" 3 "CLOSURE_EASTEREGG_STATE_WAITING_FOR_SYNC_PULSE" 2 "CLOSURE_EASTEREGG_STATE_WAITING_FOR_PLAY" 1 "CLOSURE_EASTEREGG_STATE_WAITING_FOR_START_CONDITIONS" 0 "CLOSURE_EASTEREGG_STATE_IDLE" ;
VAL_ 737 VCFRONT_batteryDischArbState 5 "FAULTED" 4 "INHIBIT_FOR_REST" 3 "BATTERY_DISCHARGE" 2 "BATTERY_HEATING" 1 "READY" 0 "NOT_READY" ;
VAL_ 737 VCFRONT_pressureRefrigSuction 127 "SNA" ;
VAL_ 737 VCFRONT_pressureRefrigDischarge 511 "SNA" ;
VAL_ 737 VCFRONT_hvacPerfTestCommand 5 "PRECONDITION" 4 "STOP" 3 "BLOW_BILEVEL" 2 "BLOW" 1 "INIT" 0 "NOT_STARTED" ;
VAL_ 737 VCFRONT_coolantFillRoutineStatus 3 "FAULTED" 2 "READY_TO_FILL" 1 "MOVING_TO_FILL_POSITION" 0 "NOT_READY" ;
VAL_ 737 VCFRONT_refrigFillRoutineStatus 3 "FAULTED" 2 "READY_TO_FILL" 1 "MOVING_TO_FILL_POSITION" 0 "NOT_READY" ;
VAL_ 737 VCFRONT_closeValvesRoutineStatus 3 "FAULTED" 2 "READY_TO_FILL" 1 "MOVING_TO_FILL_POSITION" 0 "NOT_READY" ;
VAL_ 737 VCFRONT_extendedHvacPerfTestComm 10 "STOP" 9 "COUNT" 8 "8_CABIN_PURGE" 7 "7_BATTERY_COOL" 6 "6_BATTERY_HEAT_COP1" 5 "5_CABIN_HEAT_COP1" 4 "4_CABIN_COOL" 3 "3_SPLIT_REHEAT_COOL_DOMINANT" 2 "2_BATT_HEAT_CABIN_REHEAT_AS" 1 "1_CABIN_HEAT_AS" 0 "INIT" ;
VAL_ 737 VCFRONT_vbatMonitorVoltage 4095 "SNA" ;
VAL_ 737 VCFRONT_AS8510Voltage 4095 "SNA" ;
VAL_ 737 VCFRONT_activeLouverState 17 "AUTO_DETECT_MEASURE_3" 16 "AUTO_DETECT_WAIT_3" 15 "AUTO_DETECT_PAUSE_3" 14 "AUTO_DETECT_MEASURE_2" 13 "AUTO_DETECT_WAIT_2" 12 "AUTO_DETECT_PAUSE_2" 11 "AUTO_DETECT_MEASURE_1" 10 "AUTO_DETECT_WAIT_1" 9 "AUTO_DETECT_PAUSE_1" 8 "AUTO_DETECT_BACKOFF" 7 "FAILSAFE_LOCKED" 6 "FAILSAFE_OPEN" 5 "FAULTED" 4 "READY" 3 "CALIB_OPEN" 2 "CALIB_CLOSE" 1 "UNCALIBRATED" 0 "NOT_READY" ;
VAL_ 737 VCFRONT_windshieldCameraHeaterPo 63 "SNA" ;
VAL_ 507 VCLEFT_TLCStatusIndex 2 "INVALID" 1 "1" 0 "0" ;
VAL_ 507 VCLEFT_TLCTemperature -128 "SNA" ;
VAL_ 507 VCLEFT_TLCLeftTurnVoltage 255 "SNA" ;
VAL_ 507 VCLEFT_TLCRightTurnVoltage 255 "SNA" ;
VAL_ 507 VCLEFT_TLCState_LeftTurn 5 "VCLEFT_TLC_LIGHT_STATE_SNA" 4 "VCLEFT_TLC_LIGHT_STATE_FAULT" 3 "VCLEFT_TLC_LIGHT_STATE_ON_WITH_LOAD" 2 "VCLEFT_TLC_LIGHT_STATE_ON_WITHOUT_LOAD" 1 "VCLEFT_TLC_LIGHT_STATE_OFF_WITH_LOAD" 0 "VCLEFT_TLC_LIGHT_STATE_OFF_WITHOUT_LOAD" ;
VAL_ 507 VCLEFT_TLCState_RightTurn 5 "VCLEFT_TLC_LIGHT_STATE_SNA" 4 "VCLEFT_TLC_LIGHT_STATE_FAULT" 3 "VCLEFT_TLC_LIGHT_STATE_ON_WITH_LOAD" 2 "VCLEFT_TLC_LIGHT_STATE_ON_WITHOUT_LOAD" 1 "VCLEFT_TLC_LIGHT_STATE_OFF_WITH_LOAD" 0 "VCLEFT_TLC_LIGHT_STATE_OFF_WITHOUT_LOAD" ;
VAL_ 507 VCLEFT_TLCState_Tail 5 "VCLEFT_TLC_LIGHT_STATE_SNA" 4 "VCLEFT_TLC_LIGHT_STATE_FAULT" 3 "VCLEFT_TLC_LIGHT_STATE_ON_WITH_LOAD" 2 "VCLEFT_TLC_LIGHT_STATE_ON_WITHOUT_LOAD" 1 "VCLEFT_TLC_LIGHT_STATE_OFF_WITH_LOAD" 0 "VCLEFT_TLC_LIGHT_STATE_OFF_WITHOUT_LOAD" ;
VAL_ 507 VCLEFT_TLCState_Stop 5 "VCLEFT_TLC_LIGHT_STATE_SNA" 4 "VCLEFT_TLC_LIGHT_STATE_FAULT" 3 "VCLEFT_TLC_LIGHT_STATE_ON_WITH_LOAD" 2 "VCLEFT_TLC_LIGHT_STATE_ON_WITHOUT_LOAD" 1 "VCLEFT_TLC_LIGHT_STATE_OFF_WITH_LOAD" 0 "VCLEFT_TLC_LIGHT_STATE_OFF_WITHOUT_LOAD" ;
VAL_ 507 VCLEFT_TLCState_Fog 5 "VCLEFT_TLC_LIGHT_STATE_SNA" 4 "VCLEFT_TLC_LIGHT_STATE_FAULT" 3 "VCLEFT_TLC_LIGHT_STATE_ON_WITH_LOAD" 2 "VCLEFT_TLC_LIGHT_STATE_ON_WITHOUT_LOAD" 1 "VCLEFT_TLC_LIGHT_STATE_OFF_WITH_LOAD" 0 "VCLEFT_TLC_LIGHT_STATE_OFF_WITHOUT_LOAD" ;
VAL_ 507 VCLEFT_TLCState_Reverse 5 "VCLEFT_TLC_LIGHT_STATE_SNA" 4 "VCLEFT_TLC_LIGHT_STATE_FAULT" 3 "VCLEFT_TLC_LIGHT_STATE_ON_WITH_LOAD" 2 "VCLEFT_TLC_LIGHT_STATE_ON_WITHOUT_LOAD" 1 "VCLEFT_TLC_LIGHT_STATE_OFF_WITH_LOAD" 0 "VCLEFT_TLC_LIGHT_STATE_OFF_WITHOUT_LOAD" ;
VAL_ 292 VCLEFT_liftgateRequestAction 18 "LIFTGATE_POSITION_ACTION_COUNT" 17 "LIFTGATE_POSITION_ACTION_FIXED_DUTY_LATCH_CURRENT_SCALED" 16 "LIFTGATE_POSITION_ACTION_FIXED_DUTY_LATCH_CURRENT" 15 "LIFTGATE_POSITION_ACTION_OPENING_BACKOFF" 14 "LIFTGATE_POSITION_ACTION_UPDATE_PARAM_CLOSING_SPEED" 13 "LIFTGATE_POSITION_ACTION_FACTORY_CLOSE" 12 "LIFTGATE_POSITION_ACTION_UNCAL_CLOSE" 11 "LIFTGATE_POSITION_ACTION_CLOSING_WHOOSH" 10 "LIFTGATE_POSITION_ACTION_CLOSING" 9 "LIFTGATE_POSITION_ACTION_PARTY_OPENING" 8 "LIFTGATE_POSITION_ACTION_OPENING_WHOOSH" 7 "LIFTGATE_POSITION_ACTION_OPENING_INIT_VEL" 6 "LIFTGATE_POSITION_ACTION_OPENING" 5 "LIFTGATE_POSITION_ACTION_RAMPED_DUTY_OFF" 4 "LIFTGATE_POSITION_ACTION_RAMPED_DUTY_LATCH_EXIT" 3 "LIFTGATE_POSITION_ACTION_RAMPED_DUTY_EOT" 2 "LIFTGATE_POSITION_ACTION_FIXED_DUTY_CLOSE" 1 "LIFTGATE_POSITION_ACTION_FIXED_DUTY_OPEN" 0 "LIFTGATE_POSITION_ACTION_IDLE" ;
VAL_ 292 VCLEFT_liftgateReqObsDetMode 5 "PLG_OBSTACLE_DETECT_MODE_PARTY_CLOSE" 4 "PLG_OBSTACLE_DETECT_MODE_LATCH_EXIT" 3 "PLG_OBSTACLE_DETECT_MODE_LATCH_ENTRY" 2 "PLG_OBSTACLE_DETECT_MODE_CLOSING" 1 "PLG_OBSTACLE_DETECT_MODE_OPENING" 0 "PLG_OBSTACLE_DETECT_MODE_INACTIVE" ;
VAL_ 1802 VCLEFT_logging0point1HzIndex 1 "END" 0 "MISC" ;
VAL_ 1802 VCLEFT_leftBrakeTailLightCurrent 511 "SNA" ;
VAL_ 1802 VCLEFT_leftBrakeTailLightCu_0001 4 "FALLING_EDGE_TRANSIENT" 3 "STEADY_STATE_ON" 2 "RISING_EDGE_TRANSIENT" 1 "STEADY_STATE_OFF" 0 "SNA" ;
VAL_ 1802 VCLEFT_leftRearTurnLightCurrent 511 "SNA" ;
VAL_ 1802 VCLEFT_leftRearTurnLightCurrentS 4 "FALLING_EDGE_TRANSIENT" 3 "STEADY_STATE_ON" 2 "RISING_EDGE_TRANSIENT" 1 "STEADY_STATE_OFF" 0 "SNA" ;
VAL_ 1802 VCLEFT_phoneTemperatureFL -128 "SNA" ;
VAL_ 1802 VCLEFT_phoneTemperatureFR -128 "SNA" ;
VAL_ 930 VCLEFT_statusIndex 2 "MUX2" 1 "MUX1" 0 "MUX0" ;
VAL_ 930 VCLEFT_swcInputVoltage 255 "SNA" ;
VAL_ 930 VCLEFT_swcPCBATemperature -128 "SNA" ;
VAL_ 930 VCLEFT_LVBatteryTypeDBG 5 "LV_BATTERY_TYPE_TESLA_48V_LI_ION" 4 "LV_BATTERY_TYPE_TESLA_16V_LI_ION" 3 "LV_BATTERY_TYPE_CATL_LI_ION" 2 "LV_BATTERY_TYPE_CLARIOS_B24_FLOODED" 1 "LV_BATTERY_TYPE_ATLASBX_B24_FLOODED" 0 "LV_BATTERY_TYPE_UNKNOWN" ;
VAL_ 930 VCLEFT_trailerAuxCurrent 4095 "SNA" ;
VAL_ 930 VCLEFT_swcHeatTmp 1023 "SNA" ;
VAL_ 930 VCLEFT_swcHeatStatus 4 "HEATER_STATE_FAULT" 3 "HEATER_STATE_OFF_UNAVAILABLE" 2 "HEATER_STATE_OFF" 1 "HEATER_STATE_ON" 0 "HEATER_STATE_SNA" ;
VAL_ 930 VCLEFT_swcHeatPwr 511 "SNA" ;
VAL_ 930 VCLEFT_swcHeatDutyCycle 127 "SNA" ;
VAL_ 930 VCLEFT_autonomyBehaviorStatus 2 "DRIVERLESS_NO_TAKEOVER" 1 "DRIVERLESS_TAKEOVER" 0 "DRIVER" ;
VAL_ 930 VCLEFT_thirdRowLeftMapLightStatu 3 "LIGHT_SNA" 2 "LIGHT_FAULT" 1 "LIGHT_ON" 0 "LIGHT_OFF" ;
VAL_ 930 VCLEFT_thirdRowRightMapLightStat 3 "LIGHT_SNA" 2 "LIGHT_FAULT" 1 "LIGHT_ON" 0 "LIGHT_OFF" ;
VAL_ 962 VCLEFT_switchStatusIndex 1 "1" 0 "0" ;
VAL_ 962 VCLEFT_rightMirrorTilt 4 "MIRROR_TILT_LEFT" 3 "MIRROR_TILT_RIGHT" 2 "MIRROR_TILT_UP" 1 "MIRROR_TILT_DOWN" 0 "MIRROR_TILT_STOP" ;
VAL_ 962 VCLEFT_frontSeatTrackBack 3 "SWITCH_FAULT" 2 "SWITCH_ON" 1 "SWITCH_OFF" 0 "SWITCH_SNA" ;
VAL_ 962 VCLEFT_frontSeatTrackForward 3 "SWITCH_FAULT" 2 "SWITCH_ON" 1 "SWITCH_OFF" 0 "SWITCH_SNA" ;
VAL_ 962 VCLEFT_frontSeatTiltDown 3 "SWITCH_FAULT" 2 "SWITCH_ON" 1 "SWITCH_OFF" 0 "SWITCH_SNA" ;
VAL_ 962 VCLEFT_frontSeatTiltUp 3 "SWITCH_FAULT" 2 "SWITCH_ON" 1 "SWITCH_OFF" 0 "SWITCH_SNA" ;
VAL_ 962 VCLEFT_frontSeatLiftDown 3 "SWITCH_FAULT" 2 "SWITCH_ON" 1 "SWITCH_OFF" 0 "SWITCH_SNA" ;
VAL_ 962 VCLEFT_frontSeatLiftUp 3 "SWITCH_FAULT" 2 "SWITCH_ON" 1 "SWITCH_OFF" 0 "SWITCH_SNA" ;
VAL_ 962 VCLEFT_frontSeatBackrestBack 3 "SWITCH_FAULT" 2 "SWITCH_ON" 1 "SWITCH_OFF" 0 "SWITCH_SNA" ;
VAL_ 962 VCLEFT_frontSeatBackrestForward 3 "SWITCH_FAULT" 2 "SWITCH_ON" 1 "SWITCH_OFF" 0 "SWITCH_SNA" ;
VAL_ 962 VCLEFT_frontSeatLumbarDown 3 "SWITCH_FAULT" 2 "SWITCH_ON" 1 "SWITCH_OFF" 0 "SWITCH_SNA" ;
VAL_ 962 VCLEFT_frontSeatLumbarUp 3 "SWITCH_FAULT" 2 "SWITCH_ON" 1 "SWITCH_OFF" 0 "SWITCH_SNA" ;
VAL_ 962 VCLEFT_frontSeatLumbarIn 3 "SWITCH_FAULT" 2 "SWITCH_ON" 1 "SWITCH_OFF" 0 "SWITCH_SNA" ;
VAL_ 962 VCLEFT_frontSeatLumbarOut 3 "SWITCH_FAULT" 2 "SWITCH_ON" 1 "SWITCH_OFF" 0 "SWITCH_SNA" ;
VAL_ 962 VCLEFT_frontBuckleSwitch 3 "SWITCH_FAULT" 2 "SWITCH_ON" 1 "SWITCH_OFF" 0 "SWITCH_SNA" ;
VAL_ 962 VCLEFT_frontOccupancySwitch 3 "SWITCH_FAULT" 2 "SWITCH_ON" 1 "SWITCH_OFF" 0 "SWITCH_SNA" ;
VAL_ 962 VCLEFT_rearLeftBuckleSwitch 3 "SWITCH_FAULT" 2 "SWITCH_ON" 1 "SWITCH_OFF" 0 "SWITCH_SNA" ;
VAL_ 962 VCLEFT_rearCenterOccupancySwitch 3 "SWITCH_FAULT" 2 "SWITCH_ON" 1 "SWITCH_OFF" 0 "SWITCH_SNA" ;
VAL_ 962 VCLEFT_rearLeftOccupancySwitch 3 "SWITCH_FAULT" 2 "SWITCH_ON" 1 "SWITCH_OFF" 0 "SWITCH_SNA" ;
VAL_ 962 VCLEFT_rearRightOccupancySwitch 3 "SWITCH_FAULT" 2 "SWITCH_ON" 1 "SWITCH_OFF" 0 "SWITCH_SNA" ;
VAL_ 962 VCLEFT_rearCenterBuckleSwitch 3 "SWITCH_FAULT" 2 "SWITCH_ON" 1 "SWITCH_OFF" 0 "SWITCH_SNA" ;
VAL_ 962 VCLEFT_swcLeftTiltRight 3 "SWITCH_FAULT" 2 "SWITCH_ON" 1 "SWITCH_OFF" 0 "SWITCH_SNA" ;
VAL_ 962 VCLEFT_swcLeftPressed 3 "SWITCH_FAULT" 2 "SWITCH_ON" 1 "SWITCH_OFF" 0 "SWITCH_SNA" ;
VAL_ 962 VCLEFT_swcRightTiltLeft 3 "SWITCH_FAULT" 2 "SWITCH_ON" 1 "SWITCH_OFF" 0 "SWITCH_SNA" ;
VAL_ 962 VCLEFT_swcRightTiltRight 3 "SWITCH_FAULT" 2 "SWITCH_ON" 1 "SWITCH_OFF" 0 "SWITCH_SNA" ;
VAL_ 962 VCLEFT_swcRightPressed 3 "SWITCH_FAULT" 2 "SWITCH_ON" 1 "SWITCH_OFF" 0 "SWITCH_SNA" ;
VAL_ 962 VCLEFT_swcLeftTiltLeft 3 "SWITCH_FAULT" 2 "SWITCH_ON" 1 "SWITCH_OFF" 0 "SWITCH_SNA" ;
VAL_ 962 VCLEFT_swcWiperButtonState 3 "FAULT" 2 "HARD_PRESS" 1 "SOFT_PRESS" 0 "INACTIVE" ;
VAL_ 962 VCLEFT_swcTurnSignalLeftButtonSt 3 "FAULT" 2 "HARD_PRESS" 1 "SOFT_PRESS" 0 "INACTIVE" ;
VAL_ 962 VCLEFT_swcTurnSignalRightButtonS 3 "FAULT" 2 "HARD_PRESS" 1 "SOFT_PRESS" 0 "INACTIVE" ;
VAL_ 962 VCLEFT_swcHighBeamButtonState 3 "FAULT" 2 "HARD_PRESS" 1 "SOFT_PRESS" 0 "INACTIVE" ;
VAL_ 962 VCLEFT_swcVoiceControlPress 3 "SWITCH_FAULT" 2 "SWITCH_ON" 1 "SWITCH_OFF" 0 "SWITCH_SNA" ;
VAL_ 962 VCLEFT_swcCameraButtonState 3 "FAULT" 2 "HARD_PRESS" 1 "SOFT_PRESS" 0 "INACTIVE" ;
VAL_ 962 VCLEFT_swcRightPressedQF 1 "VALID" 0 "INVALID" ;
VAL_ 962 VCLEFT_2RowSeatReclineSwitchpack 6 "FAULT" 5 "REARWARD_FAST" 4 "REARWARD_SLOW" 3 "FORWARD_FAST" 2 "FORWARD_SLOW" 1 "INACTIVE" 0 "DISCONNECTED" ;
VAL_ 962 VCLEFT_3RowLeftBuckleSwitch 3 "SWITCH_FAULT" 2 "SWITCH_ON" 1 "SWITCH_OFF" 0 "SWITCH_SNA" ;
VAL_ 962 VCLEFT_frontSeatThighSupportExte 3 "SWITCH_FAULT" 2 "SWITCH_ON" 1 "SWITCH_OFF" 0 "SWITCH_SNA" ;
VAL_ 962 VCLEFT_frontSeatThighSupportRetr 3 "SWITCH_FAULT" 2 "SWITCH_ON" 1 "SWITCH_OFF" 0 "SWITCH_SNA" ;
VAL_ 962 VCLEFT_frontSeatResistiveOccupan 3 "SWITCH_FAULT" 2 "SWITCH_ON" 1 "SWITCH_OFF" 0 "SWITCH_SNA" ;
VAL_ 1114 VCRIGHT_AP_hvacState10HzIndex 2 "END" 1 "MUX_1" 0 "MUX_0" ;
VAL_ 1114 VCRIGHT_AP_hvacModelInitStatus 5 "INIT_WAITING_FOR_SENSORS" 4 "INIT_FORWARD_CALC" 3 "INIT_FROM_SENSORS_PREDICTION_ERROR" 2 "INIT_FROM_SENSORS" 1 "NOT_INIT_WAIT_FOR_GTW" 0 "NOT_INIT_WAIT_FOR_SENSORS" ;
VAL_ 1114 VCRIGHT_AP_cabinTempWindshield 255 "SNA" ;
VAL_ 1114 VCRIGHT_AP_cabinTempSideGlassRig 255 "SNA" ;
VAL_ 1114 VCRIGHT_AP_cabinTempSideGlassLef 255 "SNA" ;
VAL_ 1114 VCRIGHT_AP_hvacAirDistributionMo 7 "DEFROST_PANEL_FLOOR" 6 "DEFROST_PANEL" 5 "DEFROST_FLOOR" 4 "DEFROST" 3 "PANEL_FLOOR" 2 "PANEL" 1 "FLOOR" 0 "NONE" ;
VAL_ 1114 VCRIGHT_AP_tempDuctDefrost 255 "SNA" ;
VAL_ 1114 VCRIGHT_AP_cameraTurnOnTime 511 "SNA" ;
VAL_ 1114 VCRIGHT_AP_cameraDefogType 4 "TWO_CAMERA_PLUS_FAN" 3 "GLARESHIELD_HEATER_PLUS_FAN" 2 "CMD" 1 "CAMERA" 0 "NONE" ;
VAL_ 1114 VCRIGHT_ah_hvacFaultSurvivabilit 31 "SNA" ;
VAL_ 1114 VCRIGHT_ah_defoggingTimeNeeded 31 "SNA" ;
VAL_ 1114 VCRIGHT_AP_cameraFanDutyRequest 127 "SNA" ;
VAL_ 1114 VCRIGHT_ah_defogSystemState 7 "DEFOG_SYS_SNA" 6 "DEFOG_SYS_UNHEALTHY" 5 "DEFOG_SYS_HEALTHY_DEGRADED" 4 "DEFOG_SYS_HEALTHY" 3 "DEFOG_SYS_HEALTHY_REEVALUATING" 2 "DEFOG_SYS_EVALUATING_PRECONDITIONING" 1 "DEFOG_SYS_EVALUATING_HARDWARE" 0 "DEFOG_SYS_INIT" ;
VAL_ 1114 VCRIGHT_AP_turnForwardCameraHeat 15 "TURN_ON_REASON_MANUAL_FOGGING_HAMMER" 14 "TURN_ON_REASON_MANUAL_DEFOG_DEFROST" 13 "TURN_ON_REASON_MANUAL_HVAC_CONTROL" 12 "TURN_ON_REASON_HVAC_SYSTEM_NOT_NOMINAL" 11 "TURN_ON_REASON_WET_EVAP_STARTUP" 10 "TURN_ON_REASON_GLARESHIELD_PRECONDITIONING" 9 "TURN_ON_REASON_ROBOTAXI_PRECONDITIONING" 8 "TURN_ON_REASON_LOSS_OF_DEHUMIDIFICATION" 7 "TURN_ON_REASON_EXTERNAL_DEW_LIKELY" 6 "TURN_ON_REASON_FLASH_FOGGING" 5 "TURN_ON_REASON_COMPRESSOR_OFF" 4 "TURN_ON_REASON_START_OF_COLD_DRIVE" 3 "TURN_ON_REASON_RADIATOR_STEAMING" 2 "TURN_ON_REASON_EVAP_UNAVAILABLE" 1 "TURN_ON_REASON_EVAP_JUST_TURNED_OFF" 0 "TURN_ON_REASON_NONE" ;
VAL_ 1114 VCRIGHT_AP_turnCameraFanOffReaso 7 "TURN_OFF_REASON_CABIN_HUMIDITY" 6 "TURN_OFF_REASON_EVAP_CONTROLS_COMPROMISED" 5 "TURN_OFF_REASON_FLASH_FOGGING" 4 "TURN_OFF_REASON_VOC_CONCENTRATION_HIGH" 3 "TURN_OFF_REASON_START_OF_COLD_DRIVE" 2 "TURN_OFF_REASON_RADIATOR_STEAMING" 1 "TURN_OFF_REASON_EVAP_JUST_TURNED_OFF" 0 "TURN_OFF_REASON_NONE" ;
VAL_ 1114 VCRIGHT_AP_solarFluxOnRightWindo 255 "SNA" ;
VAL_ 1114 VCRIGHT_AP_solarFluxOnLeftWindow 255 "SNA" ;
VAL_ 1795 VCRIGHT_debugThermal10HzIndex 10 "END" 9 "HVAC_ACTUATOR_TUNNING" 8 "HVAC_PTC_COI_DEV4" 7 "HVAC_PTC_COI_DEV3" 6 "HVAC_PTC_COI_DEV2" 5 "HVAC_PTC_COI_DEV1" 4 "actuatorStatus" 3 "cabinModel" 2 "airflow" 1 "temps" 0 "heaterAndEvapWatts" ;
VAL_ 1795 VCRIGHT_setTempAdjustmentLeft 127 "SNA" ;
VAL_ 1795 VCRIGHT_setTempAdjustmentRight 127 "SNA" ;
VAL_ 1795 VCRIGHT_PTCcenterPowerLeft 63 "SNA" ;
VAL_ 1795 VCRIGHT_PTCouterPowerLeft 63 "SNA" ;
VAL_ 1795 VCRIGHT_PTCinnerPowerLeft 63 "SNA" ;
VAL_ 1795 VCRIGHT_PTCcenterPowerRight 63 "SNA" ;
VAL_ 1795 VCRIGHT_PTCouterPowerRight 63 "SNA" ;
VAL_ 1795 VCRIGHT_PTCinnerPowerRight 63 "SNA" ;
VAL_ 1795 VCRIGHT_PTCcenterStoneTempLeft 255 "SNA" ;
VAL_ 1795 VCRIGHT_PTCcenterStoneTempRight 255 "SNA" ;
VAL_ 1795 VCRIGHT_PTCinnerStoneTempLeft 255 "SNA" ;
VAL_ 1795 VCRIGHT_PTCinnerStoneTempRight 255 "SNA" ;
VAL_ 1795 VCRIGHT_PTCouterStoneTempLeft 255 "SNA" ;
VAL_ 1795 VCRIGHT_PTCouterRodTempLeft 255 "SNA" ;
VAL_ 1795 VCRIGHT_PTCouterAirTempLeft 255 "SNA" ;
VAL_ 1795 VCRIGHT_PTCcenterRodTempLeft 255 "SNA" ;
VAL_ 1795 VCRIGHT_PTCinnerRodTempLeft 255 "SNA" ;
VAL_ 1795 VCRIGHT_PTCcenterAirTempLeft 255 "SNA" ;
VAL_ 1795 VCRIGHT_PTCinnerAirTempLeft 255 "SNA" ;
VAL_ 1795 VCRIGHT_PTCouterStoneTempRight 255 "SNA" ;
VAL_ 1795 VCRIGHT_PTCouterRodTempRight 255 "SNA" ;
VAL_ 1795 VCRIGHT_PTCouterAirTempRight 255 "SNA" ;
VAL_ 1795 VCRIGHT_PTCcenterRodTempRight 255 "SNA" ;
VAL_ 1795 VCRIGHT_PTCinnerRodTempRight 255 "SNA" ;
VAL_ 1795 VCRIGHT_PTCcenterAirTempRight 255 "SNA" ;
VAL_ 1795 VCRIGHT_PTCinnerAirTempRight 255 "SNA" ;
VAL_ 291 VCRIGHT_doorStatus2Index 1 "MUX1" 0 "MUX0" ;
VAL_ 291 VCRIGHT_BPillarCameraHeaterState 4 "HEATER_STATE_FAULT" 3 "HEATER_STATE_OFF_UNAVAILABLE" 2 "HEATER_STATE_OFF" 1 "HEATER_STATE_ON" 0 "HEATER_STATE_SNA" ;
VAL_ 291 VCRIGHT_BPillarCameraHeaterCurre 63 "SNA" ;
VAL_ 739 VCRIGHT_seatStatus2Index 15 "SEAT_HEAT_3R_RIGHT" 14 "SEAT_3ROW_ADJUSTABLE_FOLD_FLAT" 13 "FRONT_SEAT_THIGH_SUPPORT" 12 "SEAT_2ROW_ADJUSTABLE_FOLD_FLAT_2" 11 "SEAT_2ROW_ADJUSTABLE_FOLD_FLAT" 10 "OCS_IEE" 9 "SEAT_2ROW_EASY_ENTRY" 8 "SEAT_SWITCH_VOLTAGES_2" 7 "SEAT_SWITCH_VOLTAGES_1" 6 "SEAT_2ROW_ACTUATOR" 5 "SEAT_HEAT_REARR_BACKREST" 4 "OCCUPANCY" 3 "SEAT_HEAT_REARR" 2 "SEAT_HEAT_REARC" 1 "SEAT_HEAT_REARL_CUSHION" 0 "SEAT_HEAT_FRONT" ;
VAL_ 739 VCRIGHT_frontSeatHeatCurrent 12 "SNA" ;
VAL_ 739 VC_AH_1RowRightSeatHeatVentHealt 2 "SEAT_HEAT_VENT_UNAVAILABLE" 1 "SEAT_HEAT_VENT_HEALTHY" 0 "SEAT_HEAT_VENT_HEALTH_UNKNOWN" ;
VAL_ 739 VCRIGHT_2RowSeatReclineState 15 "SEAT_ADJUSTABLE_FOLD_FLAT_STATE_SNA" 12 "SEAT_ADJUSTABLE_FOLD_FLAT_STATE_CALIBRATING_ABSOLUTE_SENSOR" 11 "SEAT_ADJUSTABLE_FOLD_FLAT_STATE_CALIBRATING_ZERO_POSITION" 10 "SEAT_ADJUSTABLE_FOLD_FLAT_STATE_WAITING_TO_CLEAR_FOR_UNFOLD" 9 "SEAT_ADJUSTABLE_FOLD_FLAT_STATE_WAITING_TO_CLEAR_FOR_FOLD" 8 "SEAT_ADJUSTABLE_FOLD_FLAT_STATE_MOVING_REARWARD_TO_POSITION" 7 "SEAT_ADJUSTABLE_FOLD_FLAT_STATE_MOVING_FORWARD_TO_POSITION" 6 "SEAT_ADJUSTABLE_FOLD_FLAT_STATE_UNFOLDING" 5 "SEAT_ADJUSTABLE_FOLD_FLAT_STATE_FOLDING" 4 "SEAT_ADJUSTABLE_FOLD_FLAT_STATE_ADJUSTING_REARWARD_FAST" 3 "SEAT_ADJUSTABLE_FOLD_FLAT_STATE_ADJUSTING_FORWARD_FAST" 2 "SEAT_ADJUSTABLE_FOLD_FLAT_STATE_ADJUSTING_REARWARD_COMFORT" 1 "SEAT_ADJUSTABLE_FOLD_FLAT_STATE_ADJUSTING_FORWARD_COMFORT" 0 "SEAT_ADJUSTABLE_FOLD_FLAT_STATE_STOPPED" ;
VAL_ 739 VCRIGHT_2RowSeatReclineAbsPosSwi 3 "SWITCH_FAULT" 2 "SWITCH_ON" 1 "SWITCH_OFF" 0 "SWITCH_SNA" ;
VAL_ 739 VCRIGHT_2RowSeatReclinePositionS 4 "SEAT_ADJUSTABLE_FOLD_FLAT_POSITION_STATE_SNA" 3 "SEAT_ADJUSTABLE_FOLD_FLAT_POSITION_STATE_UNKNOWN" 2 "SEAT_ADJUSTABLE_FOLD_FLAT_POSITION_STATE_UNSAFE_INTERMEDIATE" 1 "SEAT_ADJUSTABLE_FOLD_FLAT_POSITION_STATE_UNFOLDED" 0 "SEAT_ADJUSTABLE_FOLD_FLAT_POSITION_STATE_FOLDED" ;
VAL_ 739 VCRIGHT_2RowSeatReclineNextToggl 2 "SEAT_ADJUSTABLE_FOLD_FLAT_NEXT_TOGGLE_DIRECTION_SNA" 1 "SEAT_ADJUSTABLE_FOLD_FLAT_NEXT_TOGGLE_DIRECTION_UNFOLD" 0 "SEAT_ADJUSTABLE_FOLD_FLAT_NEXT_TOGGLE_DIRECTION_FOLD" ;
VAL_ 739 VCRIGHT_2RowSeat1RClashAvoidance 6 "SEAT_FOLD_FLAT_CLASH_AVOIDANCE_REASON_FRONT_SEAT_OCCUPANCY" 5 "SEAT_FOLD_FLAT_CLASH_AVOIDANCE_REASON_FRONT_SEAT_MOVING" 4 "SEAT_FOLD_FLAT_CLASH_AVOIDANCE_REASON_FRONT_SEAT_PROFILE_RECALL" 3 "SEAT_FOLD_FLAT_CLASH_AVOIDANCE_REASON_REAR_SEAT_UNCALIBRATED" 2 "SEAT_FOLD_FLAT_CLASH_AVOIDANCE_REASON_FRONT_SEAT_UNCALIBRATED" 1 "SEAT_FOLD_FLAT_CLASH_AVOIDANCE_REASON_VEHICLE_IN_MOTION" 0 "SEAT_FOLD_FLAT_CLASH_AVOIDANCE_REASON_NONE" ;
VAL_ 739 VCRIGHT_2RowSeat1RClashAvoi_0001 3 "SEAT_FOLD_FLAT_CLASH_AVOIDANCE_STATE_RESTORING_FRONT_SEAT" 2 "SEAT_FOLD_FLAT_CLASH_AVOIDANCE_STATE_WAITING_TO_RESTORE_FRONT_SEAT" 1 "SEAT_FOLD_FLAT_CLASH_AVOIDANCE_STATE_FRONT_SEAT_CLEARING" 0 "SEAT_FOLD_FLAT_CLASH_AVOIDANCE_STATE_IDLE" ;
VAL_ 739 VC_AH_2RowRightSeatMovementHealt 4 "SEAT_CALIBRATION_REQUIRED" 3 "SEAT_IN_NON_USE_POSITION" 2 "SEAT_CANNOT_MOVE" 1 "SEAT_MOVEMENT_HEALTHY" 0 "SEAT_MOVEMENT_HEALTH_UNKNOWN" ;
VAL_ 739 VCRIGHT_3RowSeatReclineState 15 "SEAT_ADJUSTABLE_FOLD_FLAT_STATE_SNA" 12 "SEAT_ADJUSTABLE_FOLD_FLAT_STATE_CALIBRATING_ABSOLUTE_SENSOR" 11 "SEAT_ADJUSTABLE_FOLD_FLAT_STATE_CALIBRATING_ZERO_POSITION" 10 "SEAT_ADJUSTABLE_FOLD_FLAT_STATE_WAITING_TO_CLEAR_FOR_UNFOLD" 9 "SEAT_ADJUSTABLE_FOLD_FLAT_STATE_WAITING_TO_CLEAR_FOR_FOLD" 8 "SEAT_ADJUSTABLE_FOLD_FLAT_STATE_MOVING_REARWARD_TO_POSITION" 7 "SEAT_ADJUSTABLE_FOLD_FLAT_STATE_MOVING_FORWARD_TO_POSITION" 6 "SEAT_ADJUSTABLE_FOLD_FLAT_STATE_UNFOLDING" 5 "SEAT_ADJUSTABLE_FOLD_FLAT_STATE_FOLDING" 4 "SEAT_ADJUSTABLE_FOLD_FLAT_STATE_ADJUSTING_REARWARD_FAST" 3 "SEAT_ADJUSTABLE_FOLD_FLAT_STATE_ADJUSTING_FORWARD_FAST" 2 "SEAT_ADJUSTABLE_FOLD_FLAT_STATE_ADJUSTING_REARWARD_COMFORT" 1 "SEAT_ADJUSTABLE_FOLD_FLAT_STATE_ADJUSTING_FORWARD_COMFORT" 0 "SEAT_ADJUSTABLE_FOLD_FLAT_STATE_STOPPED" ;
VAL_ 739 VCRIGHT_3RowSeatReclineNextToggl 2 "SEAT_ADJUSTABLE_FOLD_FLAT_NEXT_TOGGLE_DIRECTION_SNA" 1 "SEAT_ADJUSTABLE_FOLD_FLAT_NEXT_TOGGLE_DIRECTION_UNFOLD" 0 "SEAT_ADJUSTABLE_FOLD_FLAT_NEXT_TOGGLE_DIRECTION_FOLD" ;
VAL_ 739 VCRIGHT_3RowSeatReclinePositionS 4 "SEAT_ADJUSTABLE_FOLD_FLAT_POSITION_STATE_SNA" 3 "SEAT_ADJUSTABLE_FOLD_FLAT_POSITION_STATE_UNKNOWN" 2 "SEAT_ADJUSTABLE_FOLD_FLAT_POSITION_STATE_UNSAFE_INTERMEDIATE" 1 "SEAT_ADJUSTABLE_FOLD_FLAT_POSITION_STATE_UNFOLDED" 0 "SEAT_ADJUSTABLE_FOLD_FLAT_POSITION_STATE_FOLDED" ;
VAL_ 739 VCRIGHT_3RowSeatReclineAbsPosSwi 3 "SWITCH_FAULT" 2 "SWITCH_ON" 1 "SWITCH_OFF" 0 "SWITCH_SNA" ;
VAL_ 835 VCRIGHT_autonomyBehaviorStatus 2 "DRIVERLESS_NO_TAKEOVER" 1 "DRIVERLESS_TAKEOVER" 0 "DRIVER" ;
VAL_ 835 VCRIGHT_LVBatteryTypeDBG 5 "LV_BATTERY_TYPE_TESLA_48V_LI_ION" 4 "LV_BATTERY_TYPE_TESLA_16V_LI_ION" 3 "LV_BATTERY_TYPE_CATL_LI_ION" 2 "LV_BATTERY_TYPE_CLARIOS_B24_FLOODED" 1 "LV_BATTERY_TYPE_ATLASBX_B24_FLOODED" 0 "LV_BATTERY_TYPE_UNKNOWN" ;
VAL_ 835 VCRIGHT_rearDefrostState 4 "HEATER_STATE_FAULT" 3 "HEATER_STATE_OFF_UNAVAILABLE" 2 "HEATER_STATE_OFF" 1 "HEATER_STATE_ON" 0 "HEATER_STATE_SNA" ;
VAL_ 835 VCRIGHT_mirrorHeatState 4 "HEATER_STATE_FAULT" 3 "HEATER_STATE_OFF_UNAVAILABLE" 2 "HEATER_STATE_OFF" 1 "HEATER_STATE_ON" 0 "HEATER_STATE_SNA" ;
VAL_ 835 VCRIGHT_steeringWheelHeaterDCTgt 127 "SNA" ;
VAL_ 899 VCRIGHT_thsTemperature 255 "SNA" ;
VAL_ 899 VCRIGHT_thsState 4 "IDLE" 3 "WAIT_CRC_RESPONSE" 2 "WAIT_CRC_REQUEST" 1 "CONFIG" 0 "INIT" ;
VAL_ 899 VCRIGHT_thsLINCurrentSchedule 7 "OTHER" 3 "DIAGNOSTIC" 2 "CONFIG" 1 "MAIN" 0 "OFF" ;
VAL_ 899 VCRIGHT_thsHumidity 127 "SNA" ;
VAL_ 899 VCRIGHT_estimatedVehicleSituatio 2 "VEHICLE_SITUATION_OUTDOOR" 1 "VEHICLE_SITUATION_INDOOR" 0 "VEHICLE_SITUATION_UNKNOWN" ;
VAL_ 899 VCRIGHT_thsSolarLoadInfrared 1023 "SNA" ;
VAL_ 899 VCRIGHT_thsSolarLoadVisible 1023 "SNA" ;
VAL_ 899 VCRIGHT_estimatedThsSolarLoad 1023 "SNA" ;
VAL_ 1066 VCSEC_TPMSSensorState0 5 "SENSOR_WAIT_FOR_NEXT_ADV" 4 "SENSOR_DISCONNECTING" 3 "SENSOR_CONNECTED" 2 "SENSOR_WAIT_FOR_CONN" 1 "SENSOR_WAIT_FOR_ADV" 0 "SENSOR_NOT_PAIRED" ;
VAL_ 1066 VCSEC_TPMSConnectionTypeCurrent0 3 "CONNECTIONTYPE_FAST_SLAVE_LATENCY" 2 "CONNECTIONTYPE_UNKNOWN" 1 "CONNECTIONTYPE_SLOW" 0 "CONNECTIONTYPE_FAST" ;
VAL_ 1066 VCSEC_TPMSConnectionTypeDesired0 3 "CONNECTIONTYPE_FAST_SLAVE_LATENCY" 2 "CONNECTIONTYPE_UNKNOWN" 1 "CONNECTIONTYPE_SLOW" 0 "CONNECTIONTYPE_FAST" ;
VAL_ 1066 VCSEC_TPMSSensorState1 5 "SENSOR_WAIT_FOR_NEXT_ADV" 4 "SENSOR_DISCONNECTING" 3 "SENSOR_CONNECTED" 2 "SENSOR_WAIT_FOR_CONN" 1 "SENSOR_WAIT_FOR_ADV" 0 "SENSOR_NOT_PAIRED" ;
VAL_ 1066 VCSEC_TPMSConnectionTypeCurrent1 3 "CONNECTIONTYPE_FAST_SLAVE_LATENCY" 2 "CONNECTIONTYPE_UNKNOWN" 1 "CONNECTIONTYPE_SLOW" 0 "CONNECTIONTYPE_FAST" ;
VAL_ 1066 VCSEC_TPMSConnectionTypeDesired1 3 "CONNECTIONTYPE_FAST_SLAVE_LATENCY" 2 "CONNECTIONTYPE_UNKNOWN" 1 "CONNECTIONTYPE_SLOW" 0 "CONNECTIONTYPE_FAST" ;
VAL_ 1066 VCSEC_TPMSSensorState2 5 "SENSOR_WAIT_FOR_NEXT_ADV" 4 "SENSOR_DISCONNECTING" 3 "SENSOR_CONNECTED" 2 "SENSOR_WAIT_FOR_CONN" 1 "SENSOR_WAIT_FOR_ADV" 0 "SENSOR_NOT_PAIRED" ;
VAL_ 1066 VCSEC_TPMSConnectionTypeCurrent2 3 "CONNECTIONTYPE_FAST_SLAVE_LATENCY" 2 "CONNECTIONTYPE_UNKNOWN" 1 "CONNECTIONTYPE_SLOW" 0 "CONNECTIONTYPE_FAST" ;
VAL_ 1066 VCSEC_TPMSConnectionTypeDesired2 3 "CONNECTIONTYPE_FAST_SLAVE_LATENCY" 2 "CONNECTIONTYPE_UNKNOWN" 1 "CONNECTIONTYPE_SLOW" 0 "CONNECTIONTYPE_FAST" ;
VAL_ 1066 VCSEC_TPMSSensorState3 5 "SENSOR_WAIT_FOR_NEXT_ADV" 4 "SENSOR_DISCONNECTING" 3 "SENSOR_CONNECTED" 2 "SENSOR_WAIT_FOR_CONN" 1 "SENSOR_WAIT_FOR_ADV" 0 "SENSOR_NOT_PAIRED" ;
VAL_ 1066 VCSEC_TPMSConnectionTypeCurrent3 3 "CONNECTIONTYPE_FAST_SLAVE_LATENCY" 2 "CONNECTIONTYPE_UNKNOWN" 1 "CONNECTIONTYPE_SLOW" 0 "CONNECTIONTYPE_FAST" ;
VAL_ 1066 VCSEC_TPMSConnectionTypeDesired3 3 "CONNECTIONTYPE_FAST_SLAVE_LATENCY" 2 "CONNECTIONTYPE_UNKNOWN" 1 "CONNECTIONTYPE_SLOW" 0 "CONNECTIONTYPE_FAST" ;
VAL_ 1066 VCSEC_TPMSSensorPresence0 2 "PRESENT" 1 "NOT_PRESENT" 0 "NOT_PAIRED" ;
VAL_ 1066 VCSEC_TPMSSensorPresence1 2 "PRESENT" 1 "NOT_PRESENT" 0 "NOT_PAIRED" ;
VAL_ 1066 VCSEC_TPMSSensorPresence2 2 "PRESENT" 1 "NOT_PRESENT" 0 "NOT_PAIRED" ;
VAL_ 1066 VCSEC_TPMSSensorPresence3 2 "PRESENT" 1 "NOT_PRESENT" 0 "NOT_PAIRED" ;
VAL_ 281 VCSEC_activeImmobilizerAuthLevel 3 "IMMOBILIZER_AUTH_LEVEL_MANUAL_RECOVERY" 2 "IMMOBILIZER_AUTH_LEVEL_AUTONOMY" 1 "IMMOBILIZER_AUTH_LEVEL_USER_DRIVE" 0 "IMMOBILIZER_AUTH_LEVEL_NONE" ;
VAL_ 281 VCSEC_smartTrunkLightRequest 3 "VCSEC_LIGHT_REQUEST_TYPE_DIM" 2 "VCSEC_LIGHT_REQUEST_TYPE_BLINK" 1 "VCSEC_LIGHT_REQUEST_TYPE_ON" 0 "VCSEC_LIGHT_REQUEST_TYPE_NONE" ;
VAL_ 281 VCSEC_smartTrunkSoundRequest 2 "VCSEC_SOUND_REQUEST_TYPE_NEAR" 1 "VCSEC_SOUND_REQUEST_TYPE_VICINITY" 0 "VCSEC_SOUND_REQUEST_TYPE_NONE" ;
VAL_ 281 VCSEC_chargeHandleRequestModel 8 "VCSEC_CHARGE_HANDLE_MODEL_SC_CCS2" 7 "VCSEC_CHARGE_HANDLE_MODEL_SC_NACS" 6 "VCSEC_CHARGE_HANDLE_MODEL_WC3_TYPE2" 5 "VCSEC_CHARGE_HANDLE_MODEL_UMC3_TYPE_2" 4 "VCSEC_CHARGE_HANDLE_MODEL_UMC3_GB" 3 "VCSEC_CHARGE_HANDLE_MODEL_UMC3_NACS" 2 "VCSEC_CHARGE_HANDLE_MODEL_WC3_NACS" 0 "VCSEC_CHARGE_HANDLE_MODEL_UNKNOWN" ;
VAL_ 281 VCSEC_mobileToAPRequest 4 "VCSEC_MOBILE_TO_AP_REQUEST_MAX" 2 "VCSEC_MOBILE_TO_AP_REQUEST_DISENGAGE_AUTONOMY" 1 "VCSEC_MOBILE_TO_AP_REQUEST_EMERGENCY_PULL_OVER" 0 "VCSEC_MOBILE_TO_AP_REQUEST_NONE" ;
